VERSION ""

NS_ :

BS_:

BU_: VCU FCM

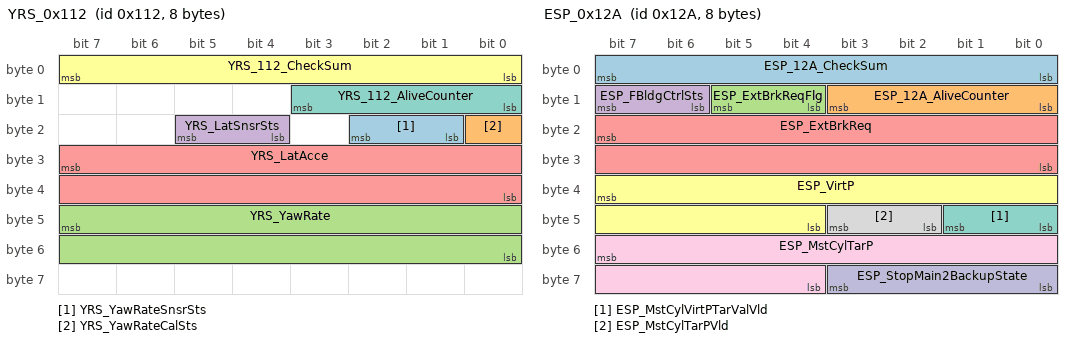
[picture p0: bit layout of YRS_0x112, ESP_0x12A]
BO_ 274 YRS_0x112: 8 VCU
 SG_ YRS_YawRateSnsrSts : 18|2@0+ (1,0) [0|3] ""  FCM
 SG_ YRS_YawRateCalSts : 16|1@0+ (1,0) [0|1] ""  FCM
 SG_ YRS_YawRate : 47|16@0+ (0.01,-180) [-180|180] "deg/s"  FCM
 SG_ YRS_LatSnsrSts : 21|2@0+ (1,0) [0|3] ""  FCM
 SG_ YRS_LatAcce : 31|16@0+ (0.001,-2) [-2|2] "g"  FCM
 SG_ YRS_112_CheckSum : 7|8@0+ (1,0) [0|255] ""  FCM
 SG_ YRS_112_AliveCounter : 11|4@0+ (1,0) [0|14] ""  FCM

BO_ 298 ESP_0x12A: 8 VCU
 SG_ ESP_12A_CheckSum : 7|8@0+ (1,0) [0|255] ""  FCM
 SG_ ESP_12A_AliveCounter : 11|4@0+ (1,0) [0|14] ""  FCM
 SG_ ESP_ExtBrkReqFlg : 13|2@0+ (1,0) [0|3] ""  FCM
 SG_ ESP_FBldgCtrlSts : 15|2@0+ (1,0) [0|3] ""  FCM
 SG_ ESP_ExtBrkReq : 23|16@0+ (0.0078125,-252) [-252|252] "ml/s"  FCM
 SG_ ESP_VirtP : 39|12@0+ (0.25,0) [0|250] "bar"  FCM
 SG_ ESP_MstCylVirtPTarValVld : 41|2@0+ (1,0) [0|3] ""  FCM
 SG_ ESP_MstCylTarPVld : 43|2@0+ (1,0) [0|3] ""  FCM
 SG_ ESP_MstCylTarP : 55|12@0+ (0.25,0) [0|250] "bar"  FCM
 SG_ ESP_StopMain2BackupState : 59|4@0+ (1,0) [0|15] ""  FCM

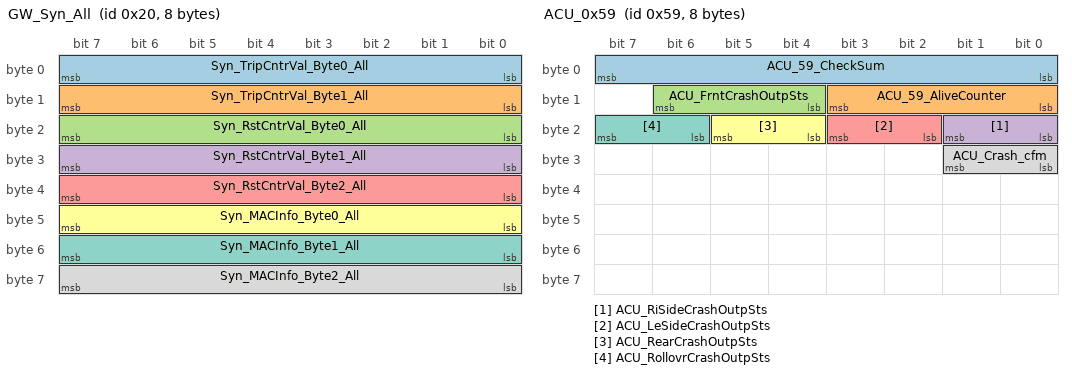
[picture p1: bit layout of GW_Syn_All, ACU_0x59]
BO_ 32 GW_Syn_All: 8 VCU
 SG_ Syn_TripCntrVal_Byte0_All : 7|8@0+ (1,0) [0|255] ""  FCM
 SG_ Syn_TripCntrVal_Byte1_All : 15|8@0+ (1,0) [0|255] ""  FCM
 SG_ Syn_RstCntrVal_Byte0_All : 23|8@0+ (1,0) [0|255] ""  FCM
 SG_ Syn_RstCntrVal_Byte1_All : 31|8@0+ (1,0) [0|255] ""  FCM
 SG_ Syn_RstCntrVal_Byte2_All : 39|8@0+ (1,0) [0|255] ""  FCM
 SG_ Syn_MACInfo_Byte0_All : 47|8@0+ (1,0) [0|255] ""  FCM
 SG_ Syn_MACInfo_Byte1_All : 55|8@0+ (1,0) [0|255] ""  FCM
 SG_ Syn_MACInfo_Byte2_All : 63|8@0+ (1,0) [0|255] ""  FCM

BO_ 89 ACU_0x59: 8 VCU
 SG_ ACU_59_CheckSum : 7|8@0+ (1,0) [0|255] ""  FCM
 SG_ ACU_59_AliveCounter : 11|4@0+ (1,0) [0|14] ""  FCM
 SG_ ACU_FrntCrashOutpSts : 14|3@0+ (1,0) [0|7] "" Vector__XXX
 SG_ ACU_RiSideCrashOutpSts : 17|2@0+ (1,0) [0|3] "" Vector__XXX
 SG_ ACU_LeSideCrashOutpSts : 19|2@0+ (1,0) [0|3] "" Vector__XXX
 SG_ ACU_RearCrashOutpSts : 21|2@0+ (1,0) [0|3] "" Vector__XXX
 SG_ ACU_RollovrCrashOutpSts : 23|2@0+ (1,0) [0|3] "" Vector__XXX
 SG_ ACU_Crash_cfm : 25|2@0+ (1,0) [0|3] ""  FCM

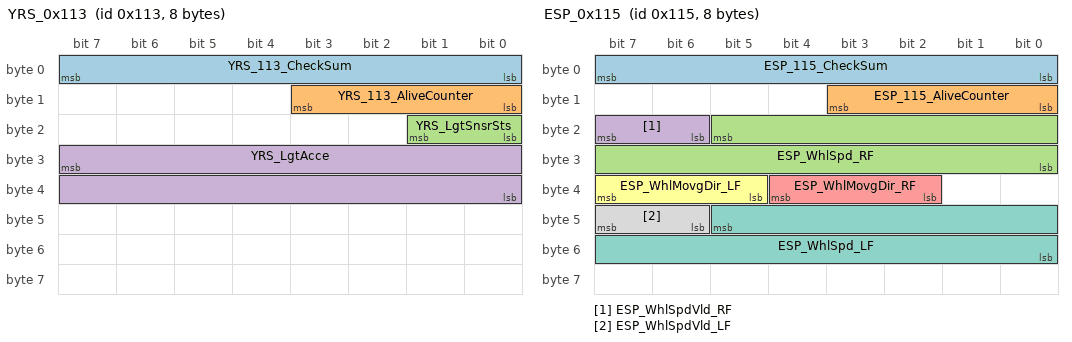
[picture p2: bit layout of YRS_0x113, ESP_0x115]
BO_ 275 YRS_0x113: 8 VCU
 SG_ YRS_113_CheckSum : 7|8@0+ (1,0) [0|255] ""  FCM
 SG_ YRS_113_AliveCounter : 11|4@0+ (1,0) [0|14] ""  FCM
 SG_ YRS_LgtSnsrSts : 17|2@0+ (1,0) [0|3] ""  FCM
 SG_ YRS_LgtAcce : 31|16@0+ (0.001,-2) [-2|2] "g"  FCM

BO_ 276 ESP_0x114: 8 VCU
 SG_ ESP_114_CheckSum : 7|8@0+ (1,0) [0|255] ""  FCM
 SG_ ESP_114_AliveCounter : 11|4@0+ (1,0) [0|14] ""  FCM
 SG_ ESP_OTARdy_Fb : 13|2@0+ (1,0) [0|3] "" Vector__XXX
 SG_ ESP_FltIndcn_DTC : 15|1@0+ (1,0) [0|1] "" Vector__XXX
 SG_ ESP_ActvSig_VDC : 16|1@0+ (1,0) [0|1] ""  FCM
 SG_ ESP_ActvSig_TCS : 17|1@0+ (1,0) [0|1] "" Vector__XXX
 SG_ ESP_ActvSig_EBD : 19|1@0+ (1,0) [0|1] "" Vector__XXX
 SG_ ESP_ActvSig_DTC : 20|1@0+ (1,0) [0|1] "" Vector__XXX
 SG_ ESP_WarningOn : 22|2@0+ (1,0) [0|3] "" Vector__XXX
 SG_ ESP_Actvndcn_CDD : 24|1@0+ (1,0) [0|1] "" Vector__XXX
 SG_ ESP_FltIndcn_CDD : 25|1@0+ (1,0) [0|1] "" Vector__XXX
 SG_ ESP_ActvIndcn_ABA : 26|1@0+ (1,0) [0|1] "" Vector__XXX
 SG_ ESP_FltIndcn_ABA : 27|1@0+ (1,0) [0|1] "" Vector__XXX
 SG_ ESP_ActvIndcn_ABP : 28|1@0+ (1,0) [0|1] "" Vector__XXX
 SG_ ESP_FltIndcn_ABP : 29|1@0+ (1,0) [0|1] "" Vector__XXX
 SG_ ESP_ActvIndcn_AEB : 30|1@0+ (1,0) [0|1] ""  FCM
 SG_ ESP_FltIndcn_AEB : 31|1@0+ (1,0) [0|1] ""  FCM
 SG_ ESP_ActvIndcn_AWB : 32|1@0+ (1,0) [0|1] "" Vector__XXX
 SG_ ESP_FltIndcn_AWB : 33|1@0+ (1,0) [0|1] "" Vector__XXX
 SG_ ESP_VehStandstillIndcn : 35|2@0+ (1,0) [0|3] ""  FCM
 SG_ ESP_BrkOverTIndcn : 36|1@0+ (1,0) [0|1] "" Vector__XXX
 SG_ ESP_FltIndcn_VDC : 37|1@0+ (1,0) [0|1] "" Vector__XXX
 SG_ ESP_ActvIndcn_CDD_AP : 42|1@0+ (1,0) [0|1] "" Vector__XXX
 SG_ ESP_FltIndcn_CDD_AP : 43|1@0+ (1,0) [0|1] "" Vector__XXX

BO_ 277 ESP_0x115: 8 VCU
 SG_ ESP_115_CheckSum : 7|8@0+ (1,0) [0|255] ""  FCM
 SG_ ESP_115_AliveCounter : 11|4@0+ (1,0) [0|14] ""  FCM
 SG_ ESP_WhlSpd_RF : 21|14@0+ (0.0625,0) [0|300] "km/h"  FCM
 SG_ ESP_WhlSpdVld_RF : 23|2@0+ (1,0) [0|3] ""  FCM
 SG_ ESP_WhlMovgDir_RF : 36|3@0+ (1,0) [0|7] ""  FCM
 SG_ ESP_WhlMovgDir_LF : 39|3@0+ (1,0) [0|7] ""  FCM
 SG_ ESP_WhlSpd_LF : 45|14@0+ (0.0625,0) [0|300] "km/h"  FCM
 SG_ ESP_WhlSpdVld_LF : 47|2@0+ (1,0) [0|3] ""  FCM

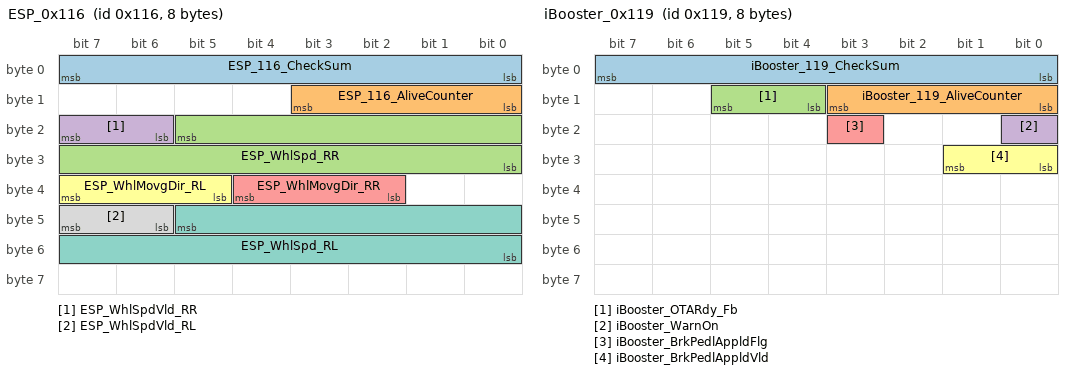
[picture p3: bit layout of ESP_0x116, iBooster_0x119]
BO_ 278 ESP_0x116: 8 VCU
 SG_ ESP_116_CheckSum : 7|8@0+ (1,0) [0|255] ""  FCM
 SG_ ESP_116_AliveCounter : 11|4@0+ (1,0) [0|14] ""  FCM
 SG_ ESP_WhlSpd_RR : 21|14@0+ (0.0625,0) [0|300] "km/h"  FCM
 SG_ ESP_WhlSpdVld_RR : 23|2@0+ (1,0) [0|3] ""  FCM
 SG_ ESP_WhlMovgDir_RR : 36|3@0+ (1,0) [0|7] ""  FCM
 SG_ ESP_WhlMovgDir_RL : 39|3@0+ (1,0) [0|7] ""  FCM
 SG_ ESP_WhlSpd_RL : 45|14@0+ (0.0625,0) [0|300] "km/h"  FCM
 SG_ ESP_WhlSpdVld_RL : 47|2@0+ (1,0) [0|3] ""  FCM

BO_ 281 iBooster_0x119: 8 VCU
 SG_ iBooster_119_CheckSum : 7|8@0+ (1,0) [0|255] ""  FCM
 SG_ iBooster_119_AliveCounter : 11|4@0+ (1,0) [0|14] ""  FCM
 SG_ iBooster_OTARdy_Fb : 13|2@0+ (1,0) [0|3] "" Vector__XXX
 SG_ iBooster_WarnOn : 16|1@0+ (1,0) [0|1] "" Vector__XXX
 SG_ iBooster_BrkPedlAppldFlg : 19|1@0+ (1,0) [0|1] ""  FCM
 SG_ iBooster_BrkPedlAppldVld : 25|2@0+ (1,0) [0|3] ""  FCM

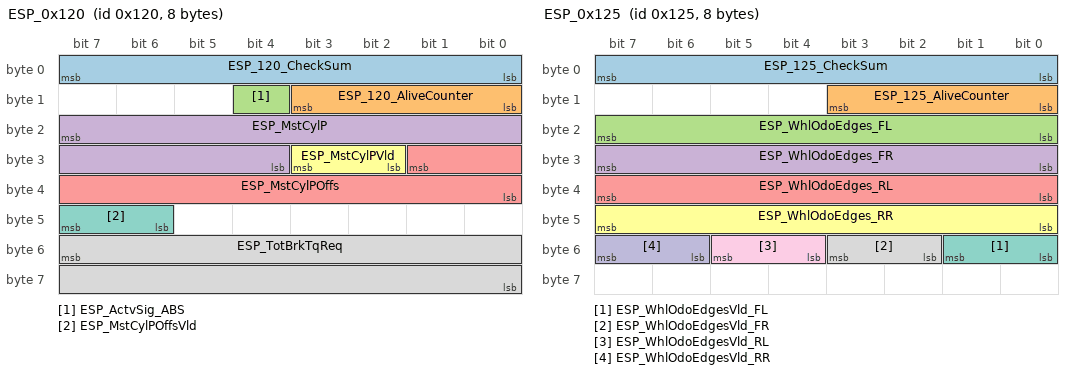
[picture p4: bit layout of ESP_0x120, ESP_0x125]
BO_ 288 ESP_0x120: 8 VCU
 SG_ ESP_120_CheckSum : 7|8@0+ (1,0) [0|255] ""  FCM
 SG_ ESP_120_AliveCounter : 11|4@0+ (1,0) [0|14] ""  FCM
 SG_ ESP_ActvSig_ABS : 12|1@0+ (1,0) [0|1] ""  FCM
 SG_ ESP_MstCylP : 23|12@0+ (0.1,-30) [-30|276.6] "bar"  FCM
 SG_ ESP_MstCylPOffs : 25|10@0+ (0.1,-15) [-15|15] "bar"  FCM
 SG_ ESP_MstCylPVld : 27|2@0+ (1,0) [0|3] ""  FCM
 SG_ ESP_MstCylPOffsVld : 47|2@0+ (1,0) [0|3] ""  FCM
 SG_ ESP_TotBrkTqReq : 55|16@0+ (1,-30000) [-30000|30000] "Nm" Vector__XXX

BO_ 293 ESP_0x125: 8 VCU
 SG_ ESP_125_CheckSum : 7|8@0+ (1,0) [0|255] ""  FCM
 SG_ ESP_125_AliveCounter : 11|4@0+ (1,0) [0|14] ""  FCM
 SG_ ESP_WhlOdoEdges_FL : 23|8@0+ (1,0) [0|255] "pulses"  FCM
 SG_ ESP_WhlOdoEdges_FR : 31|8@0+ (1,0) [0|255] "pulses"  FCM
 SG_ ESP_WhlOdoEdges_RL : 39|8@0+ (1,0) [0|255] "pulses"  FCM
 SG_ ESP_WhlOdoEdges_RR : 47|8@0+ (1,0) [0|255] "pulses"  FCM
 SG_ ESP_WhlOdoEdgesVld_FL : 49|2@0+ (1,0) [0|3] ""  FCM
 SG_ ESP_WhlOdoEdgesVld_FR : 51|2@0+ (1,0) [0|3] ""  FCM
 SG_ ESP_WhlOdoEdgesVld_RL : 53|2@0+ (1,0) [0|3] ""  FCM
 SG_ ESP_WhlOdoEdgesVld_RR : 55|2@0+ (1,0) [0|3] ""  FCM

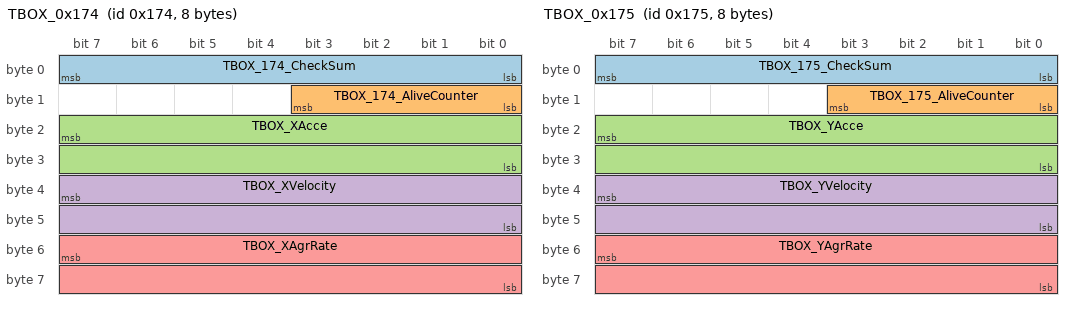
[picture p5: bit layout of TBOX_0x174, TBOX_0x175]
BO_ 372 TBOX_0x174: 8 VCU
 SG_ TBOX_174_CheckSum : 7|8@0+ (1,0) [0|255] ""  FCM
 SG_ TBOX_174_AliveCounter : 11|4@0+ (1,0) [0|14] ""  FCM
 SG_ TBOX_XAcce : 23|16@0- (0.01,0) [-327|327] "m/s2"  FCM
 SG_ TBOX_XVelocity : 39|16@0- (1,0) [-32768|32767] "cm/s"  FCM
 SG_ TBOX_XAgrRate : 55|16@0- (0.01,0) [-327|327] "deg/s"  FCM

BO_ 373 TBOX_0x175: 8 VCU
 SG_ TBOX_175_CheckSum : 7|8@0+ (1,0) [0|255] ""  FCM
 SG_ TBOX_175_AliveCounter : 11|4@0+ (1,0) [0|14] ""  FCM
 SG_ TBOX_YAcce : 23|16@0- (0.01,0) [-327|327] "m/s2"  FCM
 SG_ TBOX_YVelocity : 39|16@0- (1,0) [-32768|32767] "cm/s"  FCM
 SG_ TBOX_YAgrRate : 55|16@0- (0.01,0) [-327|327] "deg/s"  FCM

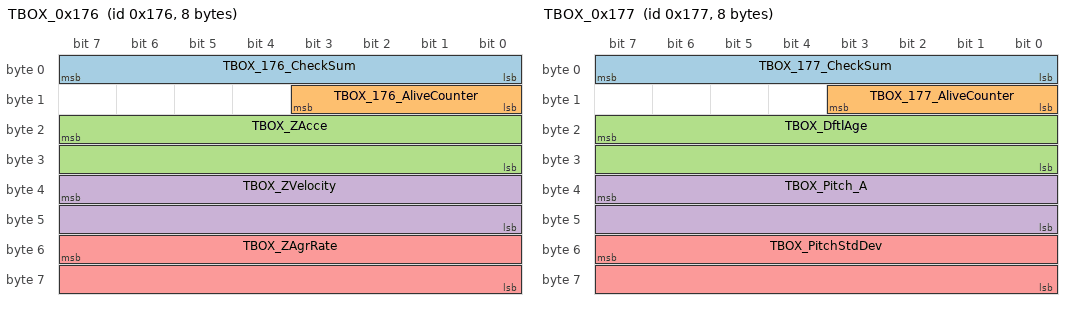
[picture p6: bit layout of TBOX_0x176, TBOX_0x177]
BO_ 374 TBOX_0x176: 8 VCU
 SG_ TBOX_176_CheckSum : 7|8@0+ (1,0) [0|255] ""  FCM
 SG_ TBOX_176_AliveCounter : 11|4@0+ (1,0) [0|14] ""  FCM
 SG_ TBOX_ZAcce : 23|16@0- (0.01,0) [-327|327] "m/s2"  FCM
 SG_ TBOX_ZVelocity : 39|16@0- (1,0) [-32768|32767] "cm/s"  FCM
 SG_ TBOX_ZAgrRate : 55|16@0- (0.01,0) [-327|327] "deg/s"  FCM

BO_ 375 TBOX_0x177: 8 VCU
 SG_ TBOX_177_CheckSum : 7|8@0+ (1,0) [0|255] ""  FCM
 SG_ TBOX_177_AliveCounter : 11|4@0+ (1,0) [0|14] ""  FCM
 SG_ TBOX_DftlAge : 23|16@0+ (1,0) [0|65000] "s"  FCM
 SG_ TBOX_Pitch_A : 39|16@0+ (0.01,-180) [-180|180] "deg"  FCM
 SG_ TBOX_PitchStdDev : 55|16@0+ (0.01,0) [0|179.9] "deg"  FCM

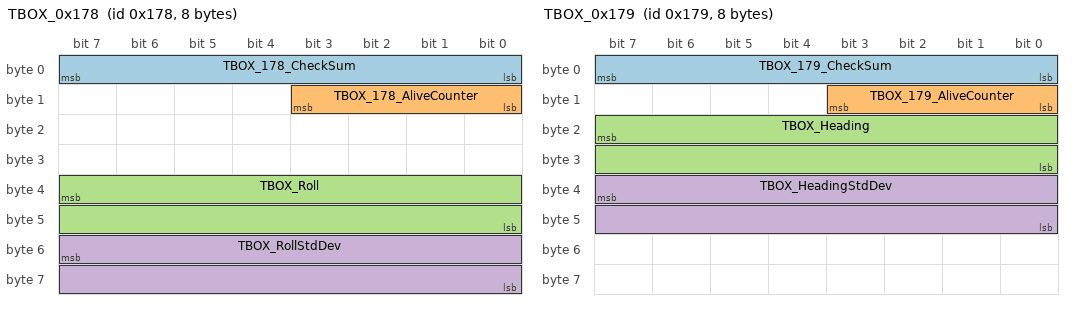
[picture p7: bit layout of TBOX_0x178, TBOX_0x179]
BO_ 376 TBOX_0x178: 8 VCU
 SG_ TBOX_178_CheckSum : 7|8@0+ (1,0) [0|255] ""  FCM
 SG_ TBOX_178_AliveCounter : 11|4@0+ (1,0) [0|14] ""  FCM
 SG_ TBOX_Roll : 39|16@0+ (0.01,-180) [-180|180] "deg"  FCM
 SG_ TBOX_RollStdDev : 55|16@0+ (0.01,0) [0|179.9] "deg"  FCM

BO_ 377 TBOX_0x179: 8 VCU
 SG_ TBOX_179_CheckSum : 7|8@0+ (1,0) [0|255] ""  FCM
 SG_ TBOX_179_AliveCounter : 11|4@0+ (1,0) [0|14] ""  FCM
 SG_ TBOX_Heading : 23|16@0+ (0.01,0) [0|359.9] "deg"  FCM
 SG_ TBOX_HeadingStdDev : 39|16@0+ (0.01,0) [0|179.9] "deg"  FCM

BO_ 440 ESP_0x1B8: 8 VCU
 SG_ ESP_1B8_CheckSum : 7|8@0+ (1,0) [0|255] ""  FCM
 SG_ ESP_1B8_AliveCounter : 11|4@0+ (1,0) [0|14] ""  FCM
 SG_ ESP_ModFbSig : 14|3@0+ (1,0) [0|7] "" Vector__XXX
 SG_ ESP_ModSwtAllw : 15|1@0+ (1,0) [0|1] "" Vector__XXX
 SG_ ESP_ActvVehHldFlg : 16|1@0+ (1,0) [0|1] "" Vector__XXX
 SG_ ESP_VehSecuCdn : 19|3@0+ (1,0) [0|7] "" Vector__XXX
 SG_ ESP_BrkFStsFlg : 20|1@0+ (1,0) [0|1] "" Vector__XXX
 SG_ ESP_CddApOpsDirMovmt : 24|1@0+ (1,0) [0|1] "" Vector__XXX
 SG_ ESP_VehStopSts : 32|1@0+ (1,0) [0|1] ""  FCM
 SG_ ESP_VehStandstillSts : 33|1@0+ (1,0) [0|1] ""  FCM
 SG_ ESP_EPB_BenchMode : 35|2@0+ (1,0) [0|3] "" Vector__XXX
 SG_ ESP_RoadSlopVld : 37|2@0+ (1,0) [0|3] "" Vector__XXX
 SG_ ESP_AEBRdy : 41|2@0+ (1,0) [0|3] "" Vector__XXX
 SG_ ESPACCRdy : 43|2@0+ (1,0) [0|3] "" Vector__XXX
 SG_ ESP_ParkRdy : 45|2@0+ (1,0) [0|3] "" Vector__XXX
 SG_ ESP_ReAEBRdy : 47|2@0+ (1,0) [0|3] "" Vector__XXX
 SG_ ESP_RoadSlop : 50|11@0+ (0.01,-10) [-10|10] "m/s2" Vector__XXX
 SG_ ESP_SpclTerrainModFltIndcn : 51|1@0+ (1,0) [0|1] "" Vector__XXX
 SG_ ESP_DrvOffStRdy : 52|1@0+ (1,0) [0|1] "" Vector__XXX
 SG_ ESP_TarLSMSts : 55|1@0+ (1,0) [0|1] "" Vector__XXX

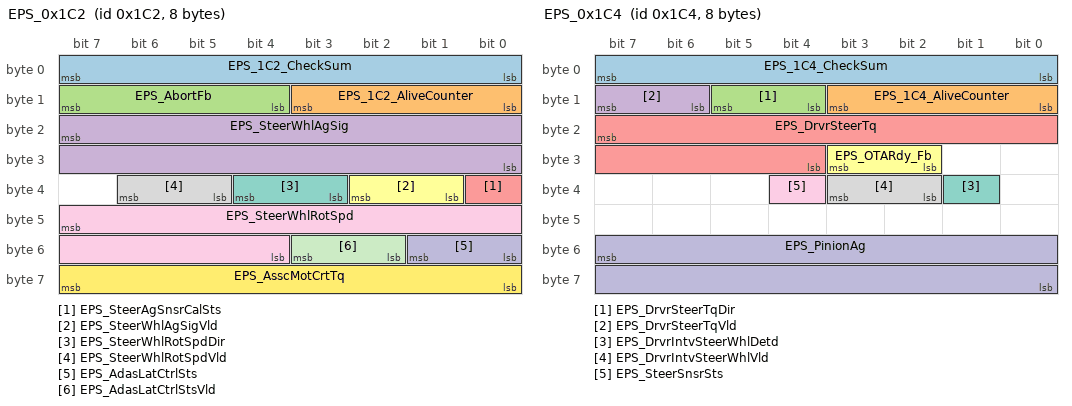
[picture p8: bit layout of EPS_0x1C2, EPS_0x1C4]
BO_ 450 EPS_0x1C2: 8 VCU
 SG_ EPS_1C2_CheckSum : 7|8@0+ (1,0) [0|255] ""  FCM
 SG_ EPS_1C2_AliveCounter : 11|4@0+ (1,0) [0|14] ""  FCM
 SG_ EPS_AbortFb : 15|4@0+ (1,0) [0|15] "" Vector__XXX
 SG_ EPS_SteerWhlAgSig : 23|16@0+ (0.0625,-780) [-780|780] "deg"  FCM
 SG_ EPS_SteerAgSnsrCalSts : 32|1@0+ (1,0) [0|1] ""  FCM
 SG_ EPS_SteerWhlAgSigVld : 34|2@0+ (1,0) [0|3] ""  FCM
 SG_ EPS_SteerWhlRotSpdDir : 36|2@0+ (1,0) [0|3] "" Vector__XXX
 SG_ EPS_SteerWhlRotSpdVld : 38|2@0+ (1,0) [0|3] ""  FCM
 SG_ EPS_SteerWhlRotSpd : 47|12@0+ (0.5,-1016) [-1016|1016] "deg/s"  FCM
 SG_ EPS_AdasLatCtrlSts : 49|2@0+ (1,0) [0|3] "" Vector__XXX
 SG_ EPS_AdasLatCtrlStsVld : 51|2@0+ (1,0) [0|3] "" Vector__XXX
 SG_ EPS_AsscMotCrtTq : 63|8@0+ (0.1,0) [0|10] "Nm" Vector__XXX

BO_ 452 EPS_0x1C4: 8 VCU
 SG_ EPS_1C4_CheckSum : 7|8@0+ (1,0) [0|255] ""  FCM
 SG_ EPS_1C4_AliveCounter : 11|4@0+ (1,0) [0|14] ""  FCM
 SG_ EPS_DrvrSteerTqDir : 13|2@0+ (1,0) [0|3] "" Vector__XXX
 SG_ EPS_DrvrSteerTqVld : 15|2@0+ (1,0) [0|3] "" Vector__XXX
 SG_ EPS_DrvrSteerTq : 23|12@0+ (0.01,0) [0|8] "Nm" Vector__XXX
 SG_ EPS_OTARdy_Fb : 27|2@0+ (1,0) [0|3] "" Vector__XXX
 SG_ EPS_DrvrIntvSteerWhlDetd : 33|1@0+ (1,0) [0|1] "" Vector__XXX
 SG_ EPS_DrvrIntvSteerWhlVld : 35|2@0+ (1,0) [0|3] "" Vector__XXX
 SG_ EPS_SteerSnsrSts : 36|1@0+ (1,0) [0|1] ""  FCM
 SG_ EPS_PinionAg : 55|16@0+ (0.0625,-780) [-780|780] "deg" Vector__XXX

BO_ 532 VCU_0x214: 16 VCU
 SG_ VCU_214_234_CheckSum : 7|8@0+ (1,0) [0|255] ""  FCM
 SG_ VCU_214_234_AliveCounter : 11|4@0+ (1,0) [0|14] ""  FCM
 SG_ VCU_RdyLamp : 12|1@0+ (1,0) [0|1] "" Vector__XXX
 SG_ VCU_BrkLampCtrlSts : 14|1@0+ (1,0) [0|1] "" Vector__XXX
 SG_ VCU_RemWakeUpEndFlg : 15|1@0+ (1,0) [0|1] "" Vector__XXX
 SG_ VCU_StgyGearSig : 19|4@0+ (1,0) [0|15] "" Vector__XXX
 SG_ VCU_ShiftMisoper : 21|1@0+ (1,0) [0|1] "" Vector__XXX
 SG_ VCU_GearSigVld : 23|2@0+ (1,0) [0|3] ""  FCM
 SG_ VCU_GearSig : 27|4@0+ (1,0) [0|15] ""  FCM
 SG_ VCU_ACCRdy : 28|1@0+ (1,0) [0|1] "" Vector__XXX
 SG_ VCU_ParkRdy : 29|1@0+ (1,0) [0|1] "" Vector__XXX
 SG_ VCU_APSPercVld : 31|2@0+ (1,0) [0|3] ""  FCM
 SG_ VCU_VehSt : 39|16@0+ (1,0) [0|65535] "" Vector__XXX
 SG_ VCU_APSPerc : 55|8@0+ (0.4,0) [0|100] "%"  FCM
 SG_ VCU_BrkSig : 56|1@0+ (1,0) [0|1] ""  FCM
 SG_ VCU_BrkSigVld : 58|2@0+ (1,0) [0|3] ""  FCM
 SG_ VCU_DrvModSigFb : 61|3@0+ (1,0) [0|7] "" Vector__XXX
 SG_ VCU_DrvModShiftMisoper : 62|1@0+ (1,0) [0|1] "" Vector__XXX
 SG_ VCU_SpclTerrainModEnaSig : 63|1@0+ (1,0) [0|1] "" Vector__XXX
 SG_ VCU_214_SSecOC_Fresh_Byte0 : 71|8@0+ (1,0) [0|255] "" Vector__XXX
 SG_ VCU_214_SSecOC_MAC_Byte0 : 79|8@0+ (1,0) [0|255] "" Vector__XXX
 SG_ VCU_214_SSecOC_MAC_Byte1 : 87|8@0+ (1,0) [0|255] "" Vector__XXX
 SG_ VCU_214_SSecOC_MAC_Byte2 : 95|8@0+ (1,0) [0|255] "" Vector__XXX

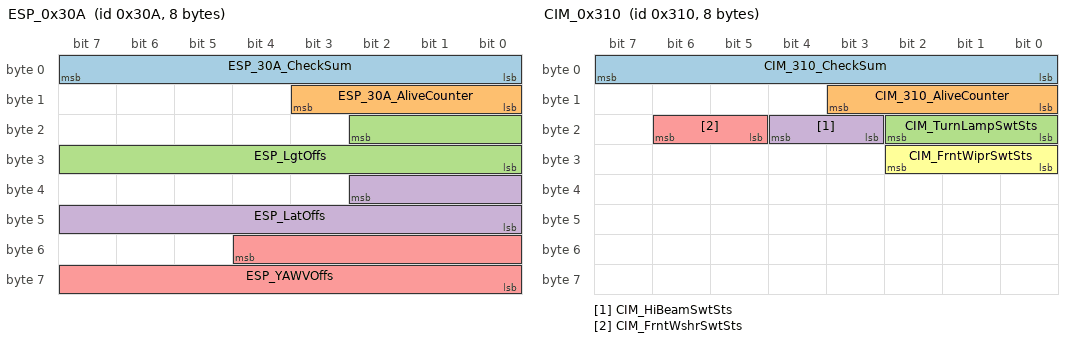
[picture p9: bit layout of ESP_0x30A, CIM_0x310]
BO_ 778 ESP_0x30A: 8 VCU
 SG_ ESP_30A_CheckSum : 7|8@0+ (1,0) [0|255] ""  FCM
 SG_ ESP_30A_AliveCounter : 11|4@0+ (1,0) [0|14] ""  FCM
 SG_ ESP_LgtOffs : 18|11@0+ (0.0027127,-2.15928) [-2.15928|2.15928] "g"  FCM
 SG_ ESP_LatOffs : 34|11@0+ (0.0027127,-2.15928) [-2.15928|2.15928] "g"  FCM
 SG_ ESP_YAWVOffs : 52|13@0+ (0.056,-120) [-120|120] "deg/s"  FCM

BO_ 784 CIM_0x310: 8 VCU
 SG_ CIM_310_CheckSum : 7|8@0+ (1,0) [0|255] ""  FCM
 SG_ CIM_310_AliveCounter : 11|4@0+ (1,0) [0|14] ""  FCM
 SG_ CIM_TurnLampSwtSts : 18|3@0+ (1,0) [0|7] ""  FCM
 SG_ CIM_HiBeamSwtSts : 20|2@0+ (1,0) [0|3] ""  FCM
 SG_ CIM_FrntWshrSwtSts : 22|2@0+ (1,0) [0|3] ""  FCM
 SG_ CIM_FrntWiprSwtSts : 26|3@0+ (1,0) [0|7] ""  FCM

BO_ 792 ESP_0x318: 8 VCU
 SG_ ESP_318_CheckSum : 7|8@0+ (1,0) [0|255] ""  FCM
 SG_ ESP_318_AliveCounter : 11|4@0+ (1,0) [0|14] ""  FCM
 SG_ ESP_BrkPedlStsVld : 13|2@0+ (1,0) [0|3] ""  FCM
 SG_ ESP_BrkPedlSts : 14|1@0+ (1,0) [0|1] ""  FCM
 SG_ ESP_VehSpdVld : 17|2@0+ (1,0) [0|3] ""  FCM
 SG_ ESP_SysActv : 20|1@0+ (1,0) [0|1] "" Vector__XXX
 SG_ ESP_LampSwtOffIndcn : 21|1@0+ (1,0) [0|1] "" Vector__XXX
 SG_ ESP_FltIndcn_EBD : 22|1@0+ (1,0) [0|1] "" Vector__XXX
 SG_ ESP_FltIndcn_ABS : 23|1@0+ (1,0) [0|1] ""  FCM
 SG_ ESP_MilgRollgCntr_ODO : 31|16@0+ (1,0) [0|65535] "pulses" Vector__XXX
 SG_ ESP_VehSpd : 47|16@0+ (0.1,0) [0|300] "km/h"  FCM
 SG_ ESP_IninModSigIndcn : 56|1@0+ (1,0) [0|1] "" Vector__XXX
 SG_ ESP_FltIndcn_TCS : 57|1@0+ (1,0) [0|1] ""  FCM
 SG_ ESP_CtrlSts_HDC : 59|2@0+ (1,0) [0|3] "" Vector__XXX
 SG_ ESP_AvlIndcn_HDC : 60|1@0+ (1,0) [0|1] "" Vector__XXX
 SG_ ESP_NoBrkP : 61|1@0+ (1,0) [0|1] "" Vector__XXX
 SG_ ESP_RDAEnaFlg : 62|1@0+ (1,0) [0|1] "" Vector__XXX

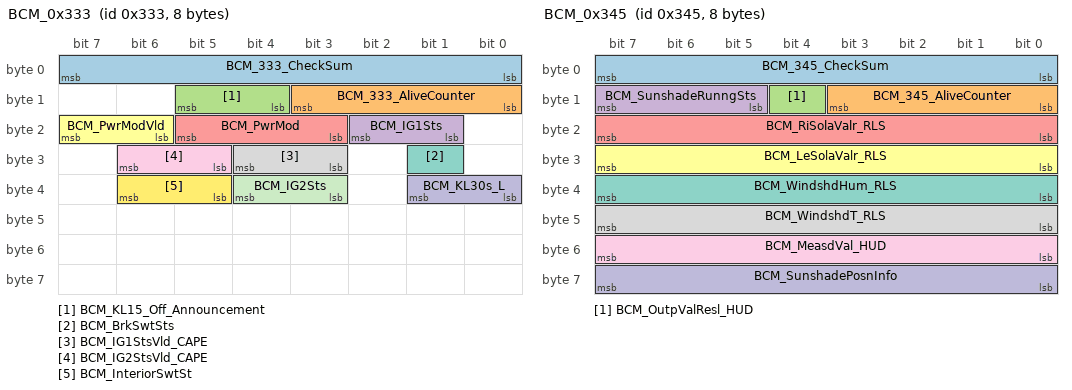
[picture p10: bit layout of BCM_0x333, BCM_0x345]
BO_ 819 BCM_0x333: 8 VCU
 SG_ BCM_333_CheckSum : 7|8@0+ (1,0) [0|255] ""  FCM
 SG_ BCM_333_AliveCounter : 11|4@0+ (1,0) [0|14] ""  FCM
 SG_ BCM_KL15_Off_Announcement : 13|2@0+ (1,0) [0|3] "" Vector__XXX
 SG_ BCM_IG1Sts : 18|2@0+ (1,0) [0|3] ""  FCM
 SG_ BCM_PwrMod : 21|3@0+ (1,0) [0|7] ""  FCM
 SG_ BCM_PwrModVld : 23|2@0+ (1,0) [0|3] ""  FCM
 SG_ BCM_BrkSwtSts : 25|1@0+ (1,0) [0|1] "" Vector__XXX
 SG_ BCM_IG1StsVld_CAPE : 28|2@0+ (1,0) [0|3] "" Vector__XXX
 SG_ BCM_IG2StsVld_CAPE : 30|2@0+ (1,0) [0|3] "" Vector__XXX
 SG_ BCM_KL30s_L : 33|2@0+ (1,0) [0|3] "" Vector__XXX
 SG_ BCM_IG2Sts : 36|2@0+ (1,0) [0|3] "" Vector__XXX
 SG_ BCM_InteriorSwtSt : 38|2@0+ (1,0) [0|3] "" Vector__XXX

BO_ 821 BCM_0x335: 8 VCU
 SG_ BCM_335_CheckSum : 7|8@0+ (1,0) [0|255] ""  FCM
 SG_ BCM_335_AliveCounter : 11|4@0+ (1,0) [0|14] ""  FCM
 SG_ BCM_WiprInSrvPosn : 12|1@0+ (1,0) [0|1] "" Vector__XXX
 SG_ BCM_IntLampTiSetSts : 15|3@0+ (1,0) [0|7] "" Vector__XXX
 SG_ BCM_WaterPosnSnsrSwtSts : 16|1@0+ (1,0) [0|1] "" Vector__XXX
 SG_ BCM_FrntFogLampOutpCmd : 17|1@0+ (1,0) [0|1] "" Vector__XXX
 SG_ BCM_LicPlateLampOutpCmd : 18|1@0+ (1,0) [0|1] "" Vector__XXX
 SG_ BCM_EnaSts_ADB : 19|1@0+ (1,0) [0|1] "" Vector__XXX
 SG_ BCM_PwrSaveOutpCmd : 20|1@0+ (1,0) [0|1] "" Vector__XXX
 SG_ BCM_ExtLampSwtSts : 23|3@0+ (1,0) [0|7] ""  FCM
 SG_ BCM_HornOutpCmd : 24|1@0+ (1,0) [0|1] "" Vector__XXX
 SG_ BCM_HornSwtSts : 25|1@0+ (1,0) [0|1] "" Vector__XXX
 SG_ BCM_WelLampOutpCmd : 26|1@0+ (1,0) [0|1] "" Vector__XXX
 SG_ BCM_FolwMeHomeSts : 27|1@0+ (1,0) [0|1] "" Vector__XXX
 SG_ BCM_FrntFogLampSwtSts : 28|1@0+ (1,0) [0|1] "" Vector__XXX
 SG_ BCM_ReFogLampSwtSts : 29|1@0+ (1,0) [0|1] ""  FCM
 SG_ BCM_ReWiprBackSwtSts : 30|1@0+ (1,0) [0|1] "" Vector__XXX
 SG_ BCM_RainClsSunroofSetSts : 31|1@0+ (1,0) [0|0] "" Vector__XXX
 SG_ BCM_MirrLockAutoSetSts : 32|1@0+ (1,0) [0|1] "" Vector__XXX
 SG_ BCM_FrntWshrOutpCmd : 33|1@0+ (1,0) [0|1] "" Vector__XXX
 SG_ BCM_DangerAlrmLampSwtSts : 34|1@0+ (1,0) [0|1] "" Vector__XXX
 SG_ BCM_ReDefrstHeatgCmd : 35|1@0+ (1,0) [0|1] "" Vector__XXX
 SG_ BCM_RvsLampOutpCmd : 36|1@0+ (1,0) [0|1] "" Vector__XXX
 SG_ BCM_IntLampOutpCmd : 37|1@0+ (1,0) [0|1] "" Vector__XXX
 SG_ BCM_LeTrunLampOutpCmd : 38|1@0+ (1,0) [0|1] "" Vector__XXX
 SG_ BCM_RiTrunLampOutpCmd : 39|1@0+ (1,0) [0|1] "" Vector__XXX
 SG_ BCM_ReWiprOutpCmd : 40|1@0+ (1,0) [0|1] "" Vector__XXX
 SG_ BCM_ReWshrOutpCmd : 41|1@0+ (1,0) [0|1] "" Vector__XXX
 SG_ BCM_BrkLampSwtSts : 42|1@0+ (1,0) [0|1] "" Vector__XXX
 SG_ BCM_HiBeamOutpCmd : 43|1@0+ (1,0) [0|1] ""  FCM
 SG_ BCM_LoBeamOutpCmd : 44|1@0+ (1,0) [0|1] ""  FCM
 SG_ BCM_PosnLampOutpCmd : 46|2@0+ (1,0) [0|3] "" Vector__XXX
 SG_ BCM_BrkLampOutpCmd : 47|1@0+ (1,0) [0|1] "" Vector__XXX
 SG_ BCM_ReFogLampOutpCmd : 48|1@0+ (1,0) [0|1] "" Vector__XXX
 SG_ BCM_FrntWiprSpd : 54|6@0+ (1,0) [0|63] "time/m"  FCM
 SG_ BCM_EnaReq_ADB : 55|1@0+ (1,0) [0|1] "" Vector__XXX
 SG_ BCM_VehAmbBri : 63|8@0+ (100,0) [0|25400] "lx" Vector__XXX

BO_ 822 ICC_0x336: 8 VCU
 SG_ ICC_336_Checksum : 7|8@0+ (1,0) [0|255] ""  FCM
 SG_ ICC_336_AliveCounter : 11|4@0+ (1,0) [0|14] ""  FCM
 SG_ ICC_SetAtmLampBri : 15|4@0+ (1,0) [0|15] "" Vector__XXX
 SG_ ICC_SuspSet : 17|2@0+ (1,0) [0|3] "" Vector__XXX
 SG_ ICC_OTAInhbRdy : 19|2@0+ (1,0) [0|3] "" Vector__XXX
 SG_ ICC_AtmLampOpenCmd : 20|1@0+ (1,0) [0|1] "" Vector__XXX
 SG_ ICC_SteerAssiSet : 23|3@0+ (1,0) [0|7] "" Vector__XXX
 SG_ ICC_SetStorageBriLvl : 27|4@0+ (1,0) [0|15] "" Vector__XXX
 SG_ ICC_HDCSwtSig : 28|1@0+ (1,0) [0|1] "" Vector__XXX
 SG_ ICC_ESPSwtSig : 29|1@0+ (1,0) [0|1] "" Vector__XXX
 SG_ ICC_ReqCalifModHMIBtn : 31|2@0+ (1,0) [0|3] "" Vector__XXX
 SG_ ICC_SpdLimOffs : 35|4@0+ (1,0) [0|15] ""  FCM
 SG_ ICC_iTPMSResetSig : 37|2@0+ (1,0) [0|3] "" Vector__XXX
 SG_ ICC_WIFIOnOffSig : 39|2@0+ (1,0) [0|3] "" Vector__XXX
 SG_ ICC_LeMirrAlrmLampFlt : 41|2@0+ (1,0) [0|3] "" Vector__XXX
 SG_ ICC_RiMirrAlrmLampFlt : 43|2@0+ (1,0) [0|3] "" Vector__XXX
 SG_ ICC_PhoneSt : 45|2@0+ (1,0) [0|3] ""  FCM
 SG_ ICC_SpeechSt : 47|2@0+ (1,0) [0|3] ""  FCM
 SG_ ICC_RemReqFb : 49|2@0+ (1,0) [0|3] "" Vector__XXX
 SG_ ICC_SpdLimFdb : 51|2@0+ (1,0) [0|3] "" Vector__XXX
 SG_ ICC_OTARdy_Fb : 54|2@0+ (1,0) [0|3] "" Vector__XXX

BO_ 837 BCM_0x345: 8 VCU
 SG_ BCM_345_CheckSum : 7|8@0+ (1,0) [0|255] ""  FCM
 SG_ BCM_345_AliveCounter : 11|4@0+ (1,0) [0|14] ""  FCM
 SG_ BCM_OutpValResl_HUD : 12|1@0+ (1,0) [0|1] "" Vector__XXX
 SG_ BCM_SunshadeRunngSts : 15|3@0+ (1,0) [0|7] "" Vector__XXX
 SG_ BCM_RiSolaValr_RLS : 23|8@0+ (4.01575,0) [0|1024.01625] "W/m2"  FCM
 SG_ BCM_LeSolaValr_RLS : 31|8@0+ (4.01575,0) [0|1024.01625] "W/m2"  FCM
 SG_ BCM_WindshdHum_RLS : 39|8@0+ (0.5,0) [0|127.5] "%"  FCM
 SG_ BCM_WindshdT_RLS : 47|8@0+ (0.5,-40) [-40|87.5] "Degree Celsius"  FCM
 SG_ BCM_MeasdVal_HUD : 55|8@0+ (1,0) [0|255] "" Vector__XXX
 SG_ BCM_SunshadePosnInfo : 63|8@0+ (1,0) [0|100] "" Vector__XXX

BO_ 856 VCU_0x358: 8 VCU
 SG_ VCU_358_CheckSum : 7|8@0+ (1,0) [0|255] "" Vector__XXX
 SG_ VCU_358_AliveCounter : 11|4@0+ (1,0) [0|14] "" Vector__XXX
 SG_ VCU_KickdwnFlg : 13|2@0+ (1,0) [0|3] "" Vector__XXX
 SG_ VCU_EPedlEnaSig : 15|1@0+ (1,0) [0|1] "" Vector__XXX
 SG_ VCU_ComLostFlt_ESP : 16|1@0+ (1,0) [0|1] "" Vector__XXX
 SG_ VCU_ComFlt_iBooster : 17|1@0+ (1,0) [0|1] "" Vector__XXX
 SG_ VCU_RegenLvlFb : 19|2@0+ (1,0) [0|3] "" Vector__XXX
 SG_ VCU_AccelModFb : 21|2@0+ (1,0) [0|3] "" Vector__XXX
 SG_ VCU_EPedlStsFb : 23|2@0+ (1,0) [0|3] "" Vector__XXX
 SG_ VCU_CcTrgSpdDisp : 31|8@0+ (1,0) [0|255] "" Vector__XXX
 SG_ VCU_Sts_CC_ICC : 35|4@0+ (1,0) [0|15] "" Vector__XXX
 SG_ VCU_CCIconDisp : 38|3@0+ (1,0) [0|7] "" Vector__XXX
 SG_ VCU_DispSpdUnit_CC : 39|1@0+ (1,0) [0|1] "" Vector__XXX
 SG_ VCU_BoostEnStat : 43|4@0+ (1,0) [0|15] "" Vector__XXX
 SG_ VCU_OTARdy_Fb : 45|2@0+ (1,0) [0|3] "" Vector__XXX
 SG_ VCU_OTA_ECUInhb_Req : 47|2@0+ (1,0) [0|3] "" Vector__XXX
 SG_ VCU_OTAVehCdnChk_ASIL : 49|2@0+ (1,0) [0|3] ""  FCM
 SG_ VCU_OTAVehInhb_ASIL_Fb : 51|2@0+ (1,0) [0|3] ""  FCM

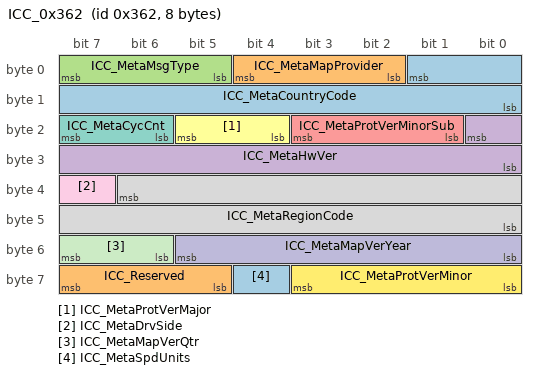
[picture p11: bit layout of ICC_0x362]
BO_ 866 ICC_0x362: 8 VCU
 SG_ ICC_MetaCountryCode : 1|10@0+ (1,0) [0|1023] ""  FCM
 SG_ ICC_MetaMapProvider : 4|3@0+ (1,0) [0|7] "m" Vector__XXX
 SG_ ICC_MetaMsgType : 7|3@0+ (1,0) [0|7] "" Vector__XXX
 SG_ ICC_MetaHwVer : 16|9@0+ (1,0) [0|511] "" Vector__XXX
 SG_ ICC_MetaProtVerMinorSub : 19|3@0+ (1,0) [0|7] "" Vector__XXX
 SG_ ICC_MetaProtVerMajor : 21|2@0+ (1,0) [0|3] "" Vector__XXX
 SG_ ICC_MetaCycCnt : 23|2@0+ (1,0) [0|3] "" Vector__XXX
 SG_ ICC_MetaRegionCode : 38|15@0+ (1,0) [0|32767] ""  FCM
 SG_ ICC_MetaDrvSide : 39|1@0+ (1,0) [0|1] "" Vector__XXX
 SG_ ICC_MetaMapVerYear : 53|6@0+ (1,2000) [2000|2063] "" Vector__XXX
 SG_ ICC_MetaMapVerQtr : 55|2@0+ (1,1) [1|3] "" Vector__XXX
 SG_ ICC_MetaProtVerMinor : 59|4@0+ (1,0) [0|15] "" Vector__XXX
 SG_ ICC_MetaSpdUnits : 60|1@0+ (1,0) [0|1] "" Vector__XXX
 SG_ ICC_Reserved : 63|3@0+ (1,0) [0|7] "" Vector__XXX

BO_ 883 ECC_0x373: 8 VCU
 SG_ ECC_CrtSts : 3|4@0+ (1,0) [0|15] "" Vector__XXX
 SG_ ECC_IninSts : 4|1@0+ (1,0) [0|1] "" Vector__XXX
 SG_ ECC_PwrSysHeatMngtSts : 6|2@0+ (1,0) [0|3] "" Vector__XXX
 SG_ ECC_ACSts : 7|1@0+ (1,0) [0|1] "" Vector__XXX
 SG_ ECC_AirClnSts : 8|1@0+ (1,0) [0|1] "" Vector__XXX
 SG_ ECC_WindSpdSts : 12|4@0+ (1,0) [0|15] ""  FCM
 SG_ ECC_BackRowAirOutlModSts : 15|3@0+ (1,0) [0|7] "" Vector__XXX
 SG_ ECC_DrvrTSetSts : 23|8@0+ (0.5,0) [0|127.5] "" Vector__XXX
 SG_ ECC_PassTSetSts : 31|8@0+ (0.5,0) [0|127.5] "" Vector__XXX
 SG_ ECC_HeatSts : 32|1@0+ (1,0) [0|1] "" Vector__XXX
 SG_ ECC_AUTOSts : 33|1@0+ (1,0) [0|1] "" Vector__XXX
 SG_ ECC_SYNCSts : 34|1@0+ (1,0) [0|1] "" Vector__XXX
 SG_ ECC_InfoSysWrmColdDisp : 36|2@0+ (1,0) [0|3] "" Vector__XXX
 SG_ ECC_CircSts : 37|1@0+ (1,0) [0|1] "" Vector__XXX
 SG_ ECC_ParticleConcVld : 39|2@0+ (1,0) [0|3] "" Vector__XXX
 SG_ ECC_OutdT : 47|8@0+ (0.5,-48) [-48|79.5] "Degree Celsius"  FCM
 SG_ ECC_OutdTVld : 49|2@0+ (1,0) [0|3] ""  FCM
 SG_ ECC_MaxFrntDefrst : 50|1@0+ (1,0) [0|1] "" Vector__XXX
 SG_ ECC_HeatMngtSysFlt : 51|1@0+ (1,0) [0|1] "" Vector__XXX
 SG_ ECC_HeatMngtFctLim : 52|1@0+ (1,0) [0|1] "" Vector__XXX
 SG_ ECC_DrvrAirOutlMod : 55|3@0+ (1,0) [0|7] "" Vector__XXX
 SG_ ECC_PassAirOutlMod : 58|3@0+ (1,0) [0|7] "" Vector__XXX
 SG_ ECC_RemSts : 60|2@0+ (1,0) [0|3] "" Vector__XXX
 SG_ ECC_OTAInhbRdy : 62|2@0+ (1,0) [0|3] "" Vector__XXX

CM_ SG_ 274 YRS_YawRateSnsrSts "Status of yaw rate sensor Indicates Yaw Rate Sensor State.";
CM_ SG_ 274 YRS_YawRateCalSts "Yaw rate sensor calibration state Indicates Yaw Rate Sensor Calibration State.";
CM_ SG_ 274 YRS_YawRate "Indicates the yaw rate (counterclockwise positive, clockwise negative, Real Value = raw value-offset)Indicates Yaw Rate.";
CM_ SG_ 274 YRS_LatSnsrSts "Status of lateral sensor Indicates Lateral Sensor State.";
CM_ SG_ 274 YRS_LatAcce "Lateral acceleration (left positive, right negative, Real Value = raw value-offset)Indicates Lateral Acceleration.";
CM_ SG_ 274 YRS_112_CheckSum "YRS_112_Message Checksum (E2E data ID: 0xA1)";
CM_ SG_ 274 YRS_112_AliveCounter "YRS_112_ AliveCounter";
CM_ SG_ 298 ESP_12A_CheckSum "ESP_12A_Message checksum_( E2E data ID: 0x54)";
CM_ SG_ 298 ESP_12A_AliveCounter "EP_12A_Message CounterESP_12A_AliveCounter";
CM_ SG_ 298 ESP_ExtBrkReqFlg "External brake request flag bitEnable bit for qTargetExternal.";
CM_ SG_ 298 ESP_FBldgCtrlSts "Electro-hydraulic coordination state positionControl state of force-blending interface to activate or hold teh pedal force compenasation.";
CM_ SG_ 298 ESP_ExtBrkReq "External braking requestTarget volume flow for external brake request (EBR) by iBooster.";
CM_ SG_ 298 ESP_MstCylVirtPTarValVld "Effective position of virtual pressure target value of master cylinderQualifier for pMcVirtual.";
CM_ SG_ 298 ESP_MstCylTarPVld "Effective position of master cylinder target pressureQualifier for pForceBlendingMc.";
CM_ SG_ 298 ESP_StopMain2BackupState "Brake master state to brake backup mode";
CM_ SG_ 32 Syn_TripCntrVal_Byte0_All "Trip Counter Value";
CM_ SG_ 32 Syn_TripCntrVal_Byte1_All "Trip Counter Value";
CM_ SG_ 32 Syn_RstCntrVal_Byte0_All "Reset Counter Value";
CM_ SG_ 32 Syn_RstCntrVal_Byte1_All "Reset Counter Value";
CM_ SG_ 32 Syn_RstCntrVal_Byte2_All "Reset Counter Value";
CM_ SG_ 32 Syn_MACInfo_Byte0_All "Synchronization message Mac Info";
CM_ SG_ 32 Syn_MACInfo_Byte1_All "Synchronization message Mac Info";
CM_ SG_ 32 Syn_MACInfo_Byte2_All "Synchronization message Mac Info";
CM_ SG_ 89 ACU_59_CheckSum "ACU_59_CheckSum (E2E data ID: 0x98) ";
CM_ SG_ 89 ACU_59_AliveCounter "ACU_0x59_Message counterACU_59_AliveCounter";
CM_ SG_ 89 ACU_FrntCrashOutpSts "Front Crash Status";
CM_ SG_ 89 ACU_RiSideCrashOutpSts "Right Side Crash Status";
CM_ SG_ 89 ACU_LeSideCrashOutpSts "Left Side Crash Status";
CM_ SG_ 89 ACU_RearCrashOutpSts "Rear Crash Status";
CM_ SG_ 89 ACU_RollovrCrashOutpSts "Rollover Crash Status";
CM_ SG_ 89 ACU_Crash_cfm "Crash confirm signal";
CM_ SG_ 275 YRS_113_CheckSum "YRS_113_Message Checksum (E2E data ID: 0xB8)";
CM_ SG_ 275 YRS_113_AliveCounter "YRS_113_AliveCounter";
CM_ SG_ 275 YRS_LgtSnsrSts "Status of lateral sensorIndicates Lateral Sensor State.";
CM_ SG_ 275 YRS_LgtAcce "Longitudinal acceleration (Forward positive, Backward negative, Real Value = raw value-offset)Indicates Longitudinal Acceleration";
CM_ SG_ 276 ESP_114_CheckSum "ESP_114_Message checksum (E2E data ID: 0x72)";
CM_ SG_ 276 ESP_114_AliveCounter "EP_114 _Message counter";
CM_ SG_ 276 ESP_OTARdy_Fb "ESP OTA ready status feedback";
CM_ SG_ 276 ESP_FltIndcn_DTC "ESP/TCS fault indication Signal indicates failure monitoring of ESP function. Not used for ABS";
CM_ SG_ 276 ESP_ActvSig_VDC "ESP activation signal VDC operating When ESP is active shall the system send out a bus signal. Not used for ABS.";
CM_ SG_ 276 ESP_ActvSig_TCS "TCS activation signal TCS operating(including DTC operating)When TCS is active shall the system send out a bus signal. Not used for ABS.";
CM_ SG_ 276 ESP_ActvSig_EBD "EBD activation signal indicating EBD in active control or not.";
CM_ SG_ 276 ESP_ActvSig_DTC "DTC activation signal indicate DTC in active control or not.";
CM_ SG_ 276 ESP_WarningOn "ESP brake fault turning on request With this signal ESP requests the warning in the dashboard.";
CM_ SG_ 276 ESP_Actvndcn_CDD "CDD operation indication indicating CDD is working or not.";
CM_ SG_ 276 ESP_FltIndcn_CDD "CDD fault indication indicating CDD is available or not.";
CM_ SG_ 276 ESP_ActvIndcn_ABA "ABA working indication ABA is active.";
CM_ SG_ 276 ESP_FltIndcn_ABA "ABA fault indication the ABA function is available.";
CM_ SG_ 276 ESP_ActvIndcn_ABP "ABP operation indication Prefill (ABP) is active.";
CM_ SG_ 276 ESP_FltIndcn_ABP "ABP fault indication Prefill (ABP) is available.";
CM_ SG_ 276 ESP_ActvIndcn_AEB "AEB operation indication ESP is excuting AEB braking function.";
CM_ SG_ 276 ESP_FltIndcn_AEB "AEB fault indication AEB is available.";
CM_ SG_ 276 ESP_ActvIndcn_AWB "AWB operation indication AWB is active(brake jerk).";
CM_ SG_ 276 ESP_FltIndcn_AWB "AWB fault indication AWB is available. Feedback of AWB activation for ACC.";
CM_ SG_ 276 ESP_VehStandstillIndcn "Vehicle stop indication indicating whether the vehicle is standstill or not; must not be set until standstill is surely reached.";
CM_ SG_ 276 ESP_BrkOverTIndcn "Brake disc high temperature indication , set 1 to exit ACC function indicating brake temperature too high or not.";
CM_ SG_ 276 ESP_FltIndcn_VDC "ESP/TCS fault indication Signal indicates failure monitoring of ESP function. Not used for ABS";
CM_ SG_ 276 ESP_ActvIndcn_CDD_AP "ECS Active indication_CDD_APWhen VLC AP is active shall the system send out a bus signal.";
CM_ SG_ 276 ESP_FltIndcn_CDD_AP "Signal from ESC indicates whether CDD_AP is activated When VLC AP is active shall the system send out a bus signal.";
CM_ SG_ 277 ESP_115_CheckSum "ESP_115_Message checksum (E2E data ID: 0x8A)";
CM_ SG_ 277 ESP_115_AliveCounter "EP_115 _Message counter";
CM_ SG_ 277 ESP_WhlSpd_RF "Right front wheel speed Wheel speed of the front right wheel.";
CM_ SG_ 277 ESP_WhlSpdVld_RF "Effective right front wheel speed Validty of signal 'WHEEL_SPEED_FRONT_RIGHT_ACC '";
CM_ SG_ 277 ESP_WhlMovgDir_RF "Front right wheel movement direction (positive forward and negative backward)Front Right wheel Moving direction.";
CM_ SG_ 277 ESP_WhlMovgDir_LF "Front left wheel movement direction (positive forward and negative backward)Front left wheel Moving direction.";
CM_ SG_ 277 ESP_WhlSpd_LF "Left front wheel speed Wheel speed of the front left wheel.";
CM_ SG_ 277 ESP_WhlSpdVld_LF "Effective position of left front wheel speed Validty of signal 'WHEEL_SPEED_FRONT_LEFT_ACC'";
CM_ SG_ 278 ESP_116_CheckSum "ESP_116_Message checksum (E2E data ID: 0x9F)";
CM_ SG_ 278 ESP_116_AliveCounter "EP_116 _Message counter";
CM_ SG_ 278 ESP_WhlSpd_RR "Right rear wheel speed Wheel speed of the rear right wheel.";
CM_ SG_ 278 ESP_WhlSpdVld_RR "Right rear wheel speed effective position Validty of signal 'WHEEL_SPEED_REAR_RIGHT_ACC'.";
CM_ SG_ 278 ESP_WhlMovgDir_RR "Movement direction of right rear wheel (positive forward and negative backward)Rear Right wheel Moving direction.";
CM_ SG_ 278 ESP_WhlMovgDir_RL "Movement direction of left rear wheel (positive forward and negative backward)Rear left wheel Moving direction.";
CM_ SG_ 278 ESP_WhlSpd_RL "Left rear wheel speed Wheel speed of the rear left wheel.";
CM_ SG_ 278 ESP_WhlSpdVld_RL "Effective left rear wheel speed Validty of signal 'WHEEL_SPEED_REAR_LEFT_ACC'.";
CM_ SG_ 281 iBooster_119_CheckSum "iBooster_119_Message Checksum (E2E data ID: 0xA4)";
CM_ SG_ 281 iBooster_119_AliveCounter "iBooster_119_Message CounteriBooster_119_AliveCounter";
CM_ SG_ 281 iBooster_OTARdy_Fb "iBooster OTA ready status feedback";
CM_ SG_ 281 iBooster_WarnOn "Required instrument display fault warning lamp With this signal eBooster requests the warning lamp in the dashboard.";
CM_ SG_ 281 iBooster_BrkPedlAppldFlg "Press the brake pedal to the mark position information about the driver attendance.";
CM_ SG_ 281 iBooster_BrkPedlAppldVld "State bit of the brake pedal depressed flag position Qualifier for Brake Pedal Applied.";
CM_ SG_ 288 ESP_120_CheckSum "ESP_120_Message checksum (E2E data ID: 0xB1)";
CM_ SG_ 288 ESP_120_AliveCounter "EP_120_Message CounterESP_120_AliveCounter";
CM_ SG_ 288 ESP_ActvSig_ABS "ABS activation signal ABS operating When ABS is active shall the system send out a bus signal.";
CM_ SG_ 288 ESP_MstCylP "Master cylinder pressure (Real value = raw value-offset)Current pressure of the master cylinder pressure sensor in the ESP. Raw value without offset compensation.";
CM_ SG_ 288 ESP_MstCylPOffs "Master cylinder pressure offset Master cylinder pressure offset.(Real value = raw value ¨C offset)";
CM_ SG_ 288 ESP_MstCylPVld "Effective pressure of master cylinder Information about signal quality of pMC1.";
CM_ SG_ 288 ESP_MstCylPOffsVld "Effective position of master cylinder pressure offset Valid Information of the signal.";
CM_ SG_ 288 ESP_TotBrkTqReq "(Total driver braking torque requirement)This signal with driver general brake torque request.";
CM_ SG_ 293 ESP_125_CheckSum "ESP_125_Message checksum (E2E data ID: 0x91)";
CM_ SG_ 293 ESP_125_AliveCounter "EP_125_Message counterESP_125_AliveCounter";
CM_ SG_ 293 ESP_WhlOdoEdges_FL "Left front wheel speed pulse accumulation Wheel speed Odo Edges front left wheel.";
CM_ SG_ 293 ESP_WhlOdoEdges_FR "Right front wheel speed pulse accumulation Wheel speed Odo Edges front right wheel.";
CM_ SG_ 293 ESP_WhlOdoEdges_RL "Trunk of left rear wheel speed Wheel speed Odo Edges rear left wheel.";
CM_ SG_ 293 ESP_WhlOdoEdges_RR "Right rear wheel speed pulse accumulation Wheel speed Odo Edges rear right wheel.";
CM_ SG_ 293 ESP_WhlOdoEdgesVld_FL "Cumulative effective bit of left front wheel speed pulseValidty of signal 'ESP_WhlOdoEdges_FL'.";
CM_ SG_ 293 ESP_WhlOdoEdgesVld_FR "Cumulative effective bit of right front wheel speed pulseValidty of signal 'ESP_WhlOdoEdges_FR'.";
CM_ SG_ 293 ESP_WhlOdoEdgesVld_RL "Effective accumulative value of left rear wheel speed pulse Validty of signal 'ESP_WhlOdoEdges_RL'.";
CM_ SG_ 293 ESP_WhlOdoEdgesVld_RR "Effective sum of right rear wheel speed pulse Validty of signal 'ESP_WhlOdoEdges_RR'.";
CM_ SG_ 372 TBOX_174_CheckSum "TBOX_174_message checksum (E2E Data ID: 0x66)";
CM_ SG_ 372 TBOX_174_AliveCounter "TBOX_174_message counter";
CM_ SG_ 372 TBOX_XAcce "X Acceleration";
CM_ SG_ 372 TBOX_XVelocity "X Velocity";
CM_ SG_ 372 TBOX_XAgrRate "X Angular Rate";
CM_ SG_ 373 TBOX_175_CheckSum "TBOX_175_message checksum (E2E Data ID: 0x67)";
CM_ SG_ 373 TBOX_175_AliveCounter "TBOX_175_message counter";
CM_ SG_ 373 TBOX_YAcce "Y Acceleration";
CM_ SG_ 373 TBOX_YVelocity "Y Velocity";
CM_ SG_ 373 TBOX_YAgrRate "Y Angular Rate";
CM_ SG_ 374 TBOX_176_CheckSum "TBOX_176_message checksum (E2E Data ID: 0x64)";
CM_ SG_ 374 TBOX_176_AliveCounter "TBOX_176_message counter";
CM_ SG_ 374 TBOX_ZAcce "Z Acceleration";
CM_ SG_ 374 TBOX_ZVelocity "Z Velocity";
CM_ SG_ 374 TBOX_ZAgrRate "Z Angular Rate";
CM_ SG_ 375 TBOX_177_CheckSum "TBOX_177_message checksum (E2E Data ID: 0x69)";
CM_ SG_ 375 TBOX_177_AliveCounter "TBOX_177_message counter";
CM_ SG_ 375 TBOX_DftlAge "Differential Age";
CM_ SG_ 375 TBOX_Pitch_A "Pitch";
CM_ SG_ 375 TBOX_PitchStdDev "Pitch Std Dev";
CM_ SG_ 376 TBOX_178_CheckSum "TBOX_178_message checksum (E2E Data ID: 0x6A)";
CM_ SG_ 376 TBOX_178_AliveCounter "TBOX_178_message counter";
CM_ SG_ 376 TBOX_Roll "Roll";
CM_ SG_ 376 TBOX_RollStdDev "Roll Std Dev";
CM_ SG_ 377 TBOX_179_CheckSum "TBOX_179_message checksum (E2E Data ID: 0x6B)";
CM_ SG_ 377 TBOX_179_AliveCounter "TBOX_179_message counter";
CM_ SG_ 377 TBOX_Heading "Vehicle heading";
CM_ SG_ 377 TBOX_HeadingStdDev "Vehicle heading Std Dev";
CM_ SG_ 440 ESP_1B8_CheckSum "ESP _1B8_Message checksum (E2E data ID: 0xC1)";
CM_ SG_ 440 ESP_1B8_AliveCounter "EP_1B8_Message counterESP_1B8_AliveCounter";
CM_ SG_ 440 ESP_ModFbSig "ESP mode feedback signal ESP mode feedback signal";
CM_ SG_ 440 ESP_ModSwtAllw "Whether ESP allows switching mode ESP Special terrain mode switch allowed";
CM_ SG_ 440 ESP_ActvVehHldFlg "ESP actively builds the brake stop vehicle flag position Flag whether the vehicle is actively held by ESP pressure built up.";
CM_ SG_ 440 ESP_VehSecuCdn "Vehicle safety condition .Indicates security states when request security condition.";
CM_ SG_ 440 ESP_BrkFStsFlg "Whether ESP has brake force Flag whether ESP there is brake force present.";
CM_ SG_ 440 ESP_CddApOpsDirMovmt "CDD_AP flag for identification of opposite direction motion Flag whether CDDAP recognises an opposite direction movement.";
CM_ SG_ 440 ESP_VehStopSts "Vehicle stop signal (fully stationary)Flag whether vehicle is in stop.";
CM_ SG_ 440 ESP_VehStandstillSts "Vehicle stop signal (v < 3 km/h)flag whether vehicle is in standstill.";
CM_ SG_ 440 ESP_RoadSlopVld "Whether the slope signal is Valid";
CM_ SG_ 440 ESP_AEBRdy "AEB ready status signal from ESP";
CM_ SG_ 440 ESPACCRdy "ACC ready status signal from ESP";
CM_ SG_ 440 ESP_ParkRdy "Park ready status signal from ESP";
CM_ SG_ 440 ESP_ReAEBRdy "ReAEB ready status signal from ESP";
CM_ SG_ 440 ESP_RoadSlop " Road gradient ";
CM_ SG_ 440 ESP_SpclTerrainModFltIndcn "ESP all-terrain mode fault indication ATM Available";
CM_ SG_ 440 ESP_DrvOffStRdy "Does the drive off flag be supported in the current LSMLSM confirmation that all conditions are fullfilled to support parking maneuver";
CM_ SG_ 440 ESP_TarLSMSts " LSM status of ESP request";
CM_ SG_ 450 EPS_1C2_CheckSum "EPS_1C2_Message check ( E2E data ID: 0x90)";
CM_ SG_ 450 EPS_1C2_AliveCounter "EP_1C2 _Message counterEPS_1C2_AliveCounter";
CM_ SG_ 450 EPS_AbortFb "EPS control interruption reason";
CM_ SG_ 450 EPS_SteerWhlAgSig "Steering wheel angle signal (counterclockwise as positive, clockwise as negative)Steering wheel angle left is positive, right is negative.
";
CM_ SG_ 450 EPS_SteerAgSnsrCalSts "Calibration state of rotation angle sensor SAS Calibration status.";
CM_ SG_ 450 EPS_SteerWhlAgSigVld "Effective bit of steering wheel angle signal indicate Steer Wheel Angle signal valid or not.";
CM_ SG_ 450 EPS_SteerWhlRotSpdDir "Steering wheel speed direction Rotation speed direction of the steering wheel.";
CM_ SG_ 450 EPS_SteerWhlRotSpdVld "Effective Position of Steering Wheel Speed";
CM_ SG_ 450 EPS_SteerWhlRotSpd "Steering wheel speed (counterclockwise is positive, clockwise is negative)Rotation speed of the steering wheel.";
CM_ SG_ 450 EPS_AdasLatCtrlSts "EPS system available state Electrical Power Steering Available Status.";
CM_ SG_ 450 EPS_AdasLatCtrlStsVld "EPS system available state Electrical Power Steering Available valid Status.";
CM_ SG_ 450 EPS_AsscMotCrtTq "Current torque of EPS booster motor";
CM_ SG_ 452 EPS_1C4_CheckSum "EPS_1C4_Message check ( E2E data ID: 0x9C)";
CM_ SG_ 452 EPS_1C4_AliveCounter "EP_1C4EPS_1C4_AliveCounter";
CM_ SG_ 452 EPS_DrvrSteerTqDir "Driver steering torque direction (0 in counterclockwise and 1 in clockwise)";
CM_ SG_ 452 EPS_DrvrSteerTqVld "Effective Position of Driver Steering Torque";
CM_ SG_ 452 EPS_DrvrSteerTq "Driver steering torque";
CM_ SG_ 452 EPS_OTARdy_Fb "EPS OTA ready status feedback";
CM_ SG_ 452 EPS_DrvrIntvSteerWhlDetd "Detect driver intervention on steering wheel Driver Steering Interference Detected.";
CM_ SG_ 452 EPS_DrvrIntvSteerWhlVld "Effective position of driver intervention on steering wheel Driver Steering Interference Detected Validity.";
CM_ SG_ 452 EPS_SteerSnsrSts "Rotation angle sensor status SAS_Failure_Status.";
CM_ SG_ 452 EPS_PinionAg "Pinion rotation angle (positive counterclockwise, negative clockwise)";
CM_ SG_ 532 VCU_214_234_CheckSum "VCU_214_Message checksum (E2E data ID: 0x12)";
CM_ SG_ 532 VCU_214_234_AliveCounter "VCU_214_Packet counterVCU_214_AliveCounter";
CM_ SG_ 532 VCU_RdyLamp "READY lamp";
CM_ SG_ 532 VCU_BrkLampCtrlSts "Stop lamp control state";
CM_ SG_ 532 VCU_RemWakeUpEndFlg "Terminal wake-up end flag bit";
CM_ SG_ 532 VCU_StgyGearSig "Strategy gear signal";
CM_ SG_ 532 VCU_ShiftMisoper "Gear misoperation";
CM_ SG_ 532 VCU_GearSigVld "Effective bit of gear signal";
CM_ SG_ 532 VCU_GearSig "Gear signal";
CM_ SG_ 532 VCU_ACCRdy "ACC ready signal from VCU";
CM_ SG_ 532 VCU_ParkRdy "Park ready signal from VCU";
CM_ SG_ 532 VCU_APSPercVld "Effective position of accelerator pedal opening";
CM_ SG_ 532 VCU_VehSt "State of complete vehicle";
CM_ SG_ 532 VCU_APSPerc "Accelerator pedal opening";
CM_ SG_ 532 VCU_BrkSig "Brake signal";
CM_ SG_ 532 VCU_BrkSigVld "Effective bit of brake signal";
CM_ SG_ 532 VCU_DrvModSigFb "Driving mode signal feedback to ICC";
CM_ SG_ 532 VCU_DrvModShiftMisoper "Driving mode switching error operation";
CM_ SG_ 532 VCU_SpclTerrainModEnaSig "All-terrain driving mode enable signal";
CM_ SG_ 532 VCU_214_SSecOC_Fresh_Byte0 "Short SecOC Fresh signal byte 0 on CAN";
CM_ SG_ 532 VCU_214_SSecOC_MAC_Byte0 "Short SecOC MAC signal byte 0 on CAN";
CM_ SG_ 532 VCU_214_SSecOC_MAC_Byte1 "Short SecOC MAC signal byte 1 on CAN";
CM_ SG_ 532 VCU_214_SSecOC_MAC_Byte2 "Short SecOC MAC signal byte 2 on CAN";
CM_ SG_ 778 ESP_30A_CheckSum "ESP_30A_Message checksum ( E2E data ID: 0x74)";
CM_ SG_ 778 ESP_30A_AliveCounter "EP_30A_Message CounterESP_30A_AliveCounter";
CM_ SG_ 778 ESP_LgtOffs "Longitudinal acceleration offset It is used with Longitudinal acceleration raw data (Real value = raw value ¨C offset).";
CM_ SG_ 778 ESP_LatOffs "Lateral acceleration offset It is used with Lateral acceleration raw data (Real value = raw value ¨C offset).";
CM_ SG_ 778 ESP_YAWVOffs "Yaw velocity offset It is used with YAW veloctity raw data (Real value = raw value ¨C offset).";
CM_ SG_ 784 CIM_310_CheckSum "CIM_310_Message checksum ( 0xC8)CIM_310_CheckSum";
CM_ SG_ 784 CIM_310_AliveCounter "CIM_310_Message counterCIM_310_AliveCounter";
CM_ SG_ 784 CIM_TurnLampSwtSts "Turn signal lamp switch stateturn signal lever status.";
CM_ SG_ 784 CIM_HiBeamSwtSts "High beam switch stateHigh beam switch status.";
CM_ SG_ 784 CIM_FrntWshrSwtSts "Status of front washer switchWasherFrontCommand.";
CM_ SG_ 784 CIM_FrntWiprSwtSts "Front wiper wiper switch stateWiper front command.";
CM_ SG_ 792 ESP_318_CheckSum "ESP318_Message Checksum ( E2E data ID: 0x79)";
CM_ SG_ 792 ESP_318_AliveCounter "ESP 3318_Message counterESP_318_AliveCounter";
CM_ SG_ 792 ESP_BrkPedlStsVld "Effective position of brake pedal state validity of BRAKE_STATUS_ESP.";
CM_ SG_ 792 ESP_BrkPedlSts "Brake pedal state indicating brake pedal activated by driver or not.";
CM_ SG_ 792 ESP_VehSpdVld "ABS_ESC signal indicates whether the vehicle speed is valid When the diagnostic have set the failure code on this signal the value wil be 2.";
CM_ SG_ 792 ESP_SysActv "ESP works effectively Is used to indicate to the driver that the system is currently active. Not used for ABS.";
CM_ SG_ 792 ESP_LampSwtOffIndcn "ESP OFF indication Signal indicates to light up 'TCS/ESP off' lamp.-manual switch off of ESP function (on/off switch).Not used for ABS.";
CM_ SG_ 792 ESP_FltIndcn_EBD "EBD fault indication Signal indicates to light up EBD lamp.";
CM_ SG_ 792 ESP_FltIndcn_ABS "ABS fault indication Signal indicates to light up ABS lamp.";
CM_ SG_ 792 ESP_MilgRollgCntr_ODO "Mileage statistical pulse Odometer rolling count 1 pulse/bit. The value shall be set to zero at every ignition off and if the counter reach max value it starts from zero again.";
CM_ SG_ 792 ESP_VehSpd "Speed signal";
CM_ SG_ 792 ESP_IninModSigIndcn "The signal needs to cover the time of ESP and ABS fault signals caused by self-inspection. Signal indicates if ESP or ABS is in initialization mode or not.";
CM_ SG_ 792 ESP_FltIndcn_TCS "ESP/TCS fault indication Signal indicates failure monitoring of ESP function. Not used for ABS";
CM_ SG_ 792 ESP_CtrlSts_HDC "Indicate that the HDC is on/off or working, and the ADAS receives this signal to determine whether the ACC is off. HDC control(Off/On, not active braking/On, active braking).";
CM_ SG_ 792 ESP_AvlIndcn_HDC "Effective bit of HDC indicating HDC is available or not.";
CM_ SG_ 792 ESP_NoBrkP "When the vehicle is stationary, whether the function has braking force or not, whether it is braking.no brake pressure applied; generally it regards wheel cylinder presure.";
CM_ SG_ 792 ESP_RDAEnaFlg "ESP remote driving function enable flag position";
CM_ SG_ 819 BCM_333_CheckSum "BCM333_message checksum ( 0xCB)BCM_333_CheckSum";
CM_ SG_ 819 BCM_333_AliveCounter "BCM333_Packet counterBCM_333_AliveCounter";
CM_ SG_ 819 BCM_KL15_Off_Announcement "Before switching off the KL15 (5s), this signal gets active to inform other ECUs that the KL15 will be disabled in 5seconds if there are still no triggers to keep it active";
CM_ SG_ 819 BCM_IG1Sts "IG1 state";
CM_ SG_ 819 BCM_PwrMod "Power mode";
CM_ SG_ 819 BCM_PwrModVld "Effective value of power mode";
CM_ SG_ 819 BCM_BrkSwtSts "Brake switch status";
CM_ SG_ 819 BCM_IG1StsVld_CAPE "Effective value of IG1 state";
CM_ SG_ 819 BCM_IG2StsVld_CAPE "Effective value of IG2 state";
CM_ SG_ 819 BCM_KL30s_L "Logical State of KL30";
CM_ SG_ 819 BCM_IG2Sts "IG2 state";
CM_ SG_ 819 BCM_InteriorSwtSt "Interior switch status from LIN1";
CM_ SG_ 821 BCM_335_CheckSum "BCM_335_Message checksum ( 0xD4)BCM_335_CheckSum";
CM_ SG_ 821 BCM_335_AliveCounter "BC_335_Message counterBCM_335_AliveCounter";
CM_ SG_ 821 BCM_WiprInSrvPosn "Whether the electronic wiper is in the service position";
CM_ SG_ 821 BCM_IntLampTiSetSts "Central control interior lamp door control delay time setting state";
CM_ SG_ 821 BCM_WaterPosnSnsrSwtSts "Condition of level sensor switch";
CM_ SG_ 821 BCM_FrntFogLampOutpCmd "Front fog lamp output command";
CM_ SG_ 821 BCM_LicPlateLampOutpCmd "License plate lamp output command";
CM_ SG_ 821 BCM_EnaSts_ADB "ADB enable";
CM_ SG_ 821 BCM_PwrSaveOutpCmd "Power saving output command";
CM_ SG_ 821 BCM_ExtLampSwtSts "Outside lamp switch status";
CM_ SG_ 821 BCM_HornOutpCmd "Horn output command";
CM_ SG_ 821 BCM_HornSwtSts "Horn switch state";
CM_ SG_ 821 BCM_WelLampOutpCmd "Approach lamp output command";
CM_ SG_ 821 BCM_FolwMeHomeSts "Follow me home state";
CM_ SG_ 821 BCM_FrntFogLampSwtSts "Front fog lamp switch state";
CM_ SG_ 821 BCM_ReFogLampSwtSts "Rear fog lamp switch state";
CM_ SG_ 821 BCM_ReWiprBackSwtSts "State of rear wiper return switch";
CM_ SG_ 821 BCM_RainClsSunroofSetSts "Central control screen closing sunroof setting state in rainy days";
CM_ SG_ 821 BCM_MirrLockAutoSetSts "Central control rearview mirror locking automatic folding setting state";
CM_ SG_ 821 BCM_FrntWshrOutpCmd "Front washing output command";
CM_ SG_ 821 BCM_DangerAlrmLampSwtSts "Hazard warning lamp switch state";
CM_ SG_ 821 BCM_ReDefrstHeatgCmd "Rear defrosting heating command";
CM_ SG_ 821 BCM_RvsLampOutpCmd "Reverse lamp output command";
CM_ SG_ 821 BCM_IntLampOutpCmd "Output state of internal lamp";
CM_ SG_ 821 BCM_LeTrunLampOutpCmd "Left turn signal lamp output command";
CM_ SG_ 821 BCM_RiTrunLampOutpCmd "Right turn signal lamp output command";
CM_ SG_ 821 BCM_ReWiprOutpCmd "Rear wiper output command";
CM_ SG_ 821 BCM_ReWshrOutpCmd "Rear washer output command";
CM_ SG_ 821 BCM_BrkLampSwtSts "Brake lamp switch state";
CM_ SG_ 821 BCM_HiBeamOutpCmd "High beam output command";
CM_ SG_ 821 BCM_LoBeamOutpCmd "Low beam output command";
CM_ SG_ 821 BCM_PosnLampOutpCmd "Position lamp output command";
CM_ SG_ 821 BCM_BrkLampOutpCmd "Brake lamp output command";
CM_ SG_ 821 BCM_ReFogLampOutpCmd "Rear fog lamp output command";
CM_ SG_ 821 BCM_FrntWiprSpd "Front wiper speed";
CM_ SG_ 821 BCM_EnaReq_ADB "ADB enable state feedback";
CM_ SG_ 821 BCM_VehAmbBri "Ambient light detection value output";
CM_ SG_ 822 ICC_336_Checksum "EHU336_Message checksum ( 0xE5)EHU_336_Checksum";
CM_ SG_ 822 ICC_336_AliveCounter "EHU336_Message CounterEHU_336_AliveCounter";
CM_ SG_ 822 ICC_SetAtmLampBri "Set the ambient light brightness";
CM_ SG_ 822 ICC_SuspSet "Suspension set";
CM_ SG_ 822 ICC_AtmLampOpenCmd "Atmosphere lamp opening command";
CM_ SG_ 822 ICC_SteerAssiSet "Steering Assist set";
CM_ SG_ 822 ICC_SetStorageBriLvl "Set brightness of storage lights";
CM_ SG_ 822 ICC_HDCSwtSig "HDC switch signalHDC switch, pressed or not.";
CM_ SG_ 822 ICC_ESPSwtSig "ESP switch signalESP switch, pressed or not.";
CM_ SG_ 822 ICC_ReqCalifModHMIBtn "California HMI button";
CM_ SG_ 822 ICC_SpdLimOffs "Speed limit deviation (reserved)";
CM_ SG_ 822 ICC_iTPMSResetSig "iTPMS reset signal";
CM_ SG_ 822 ICC_WIFIOnOffSig "Send WIFI ON/OFF signal to TBOX";
CM_ SG_ 822 ICC_LeMirrAlrmLampFlt "Left reflector warning lamp fault";
CM_ SG_ 822 ICC_RiMirrAlrmLampFlt "Right reflector warning lamp fault";
CM_ SG_ 822 ICC_PhoneSt "Phone is being usedPhone status";
CM_ SG_ 822 ICC_SpeechSt "Speech statusIndication of someone talking to a vehicle application, like navigation.";
CM_ SG_ 822 ICC_RemReqFb "Feeback signal to TBOX_RemSWH_Req from ICC to TBOX";
CM_ SG_ 822 ICC_SpdLimFdb "Feeback signal to TBOX_SpdLim from ICC to TBOX";
CM_ SG_ 822 ICC_OTARdy_Fb "ICC OTA ready status feedback";
CM_ SG_ 837 BCM_345_CheckSum "BCM_345_Message checksum ( 0xD9)BCM_345_CheckSum";
CM_ SG_ 837 BCM_345_AliveCounter "BCM345_Packet counterBCM_345_AliveCounter";
CM_ SG_ 837 BCM_OutpValResl_HUD "HUD output value resolution";
CM_ SG_ 837 BCM_SunshadeRunngSts "Sunshade running status";
CM_ SG_ 837 BCM_RiSolaValr_RLS "Solar radiation intensity at the right side";
CM_ SG_ 837 BCM_LeSolaValr_RLS "Left solar radiation intensity";
CM_ SG_ 837 BCM_WindshdHum_RLS "Glass humidity";
CM_ SG_ 837 BCM_WindshdT_RLS "Glass temperature";
CM_ SG_ 837 BCM_MeasdVal_HUD "HUD function measurement value";
CM_ SG_ 837 BCM_SunshadePosnInfo "Sunshade opening information";
CM_ SG_ 856 VCU_358_CheckSum "VCU_0x358_Message Check (E2E data ID: 0x47)";
CM_ SG_ 856 VCU_358_AliveCounter "VCU_0x358_Message counter";
CM_ SG_ 856 VCU_KickdwnFlg "status of kickdown function ";
CM_ SG_ 856 VCU_EPedlEnaSig "E-Pedal enable signal (TBD if required)";
CM_ SG_ 856 VCU_ComLostFlt_ESP "VCU and ESP communication related faults";
CM_ SG_ 856 VCU_ComFlt_iBooster "VCU and iBooster communication failure_U101587_E03";
CM_ SG_ 856 VCU_RegenLvlFb "Coasting Mode settings (Off, Normal, high) feedback to ICC";
CM_ SG_ 856 VCU_AccelModFb "Acceleration Mode setting (Low/Mid/High) feedback to ICC";
CM_ SG_ 856 VCU_EPedlStsFb "Pedal Comport Setting (One Pedal Drive / Roll / Creep) feedback to ICC";
CM_ SG_ 856 VCU_CcTrgSpdDisp "Cruise Control Target Speed display";
CM_ SG_ 856 VCU_Sts_CC_ICC "ACC status";
CM_ SG_ 856 VCU_CCIconDisp "ACC icon color";
CM_ SG_ 856 VCU_DispSpdUnit_CC "CC display speed unit";
CM_ SG_ 856 VCU_BoostEnStat "Boost Enable Status";
CM_ SG_ 856 VCU_OTARdy_Fb "VCU OTA ready status feedback";
CM_ SG_ 856 VCU_OTA_ECUInhb_Req "VCU OTA inhibit request to ECUs";
CM_ SG_ 856 VCU_OTAVehCdnChk_ASIL "ASIL A group OTA vehicle condition check status";
CM_ SG_ 856 VCU_OTAVehInhb_ASIL_Fb "ASIL A group OTA vehicle Inhibit feedback";
CM_ SG_ 866 ICC_MetaCountryCode "Country codeISO 3166-1 Release 2007-03 country code of current position;0 stands for unknown. Valid values are those specified by ISO 3166-1 numeric [14].";
CM_ SG_ 866 ICC_MetaMapProvider "Map providers of the current area (map tile, area, country...).";
CM_ SG_ 866 ICC_MetaMsgType "Identify the message bit";
CM_ SG_ 866 ICC_MetaHwVer "Hardware and/or software version of generator";
CM_ SG_ 866 ICC_MetaProtVerMinorSub "Secondary agreement sub-versionContains Minor protocol sub-version.";
CM_ SG_ 866 ICC_MetaProtVerMajor "Main agreement versionContains Major protocol version.";
CM_ SG_ 866 ICC_MetaCycCnt "This message type loop counter: The reconstructor can use this value to detect missing messagesCyclic counter of this message type:Reconstructor can use this value to detect missing messages.";
CM_ SG_ 866 ICC_MetaRegionCode "Area code0 stands for unknown, value 32767 means N/AAll other values are based on ISO 3166-2 [15] with the code mapping scheme.";
CM_ SG_ 866 ICC_MetaDrvSide "Driving direction";
CM_ SG_ 866 ICC_MetaMapVerYear "Map version (year)Please note if the whole map may be partitioned into parts that can be released on different times or even by different providers. In that case, value of this field may vary between messages. 63 stands for N/A";
CM_ SG_ 866 ICC_MetaMapVerQtr "Map version (quarter)Please note if the whole map may be partitioned into parts that can be released on different times or even by different providers. In that case, value if this field may vary between messages.";
CM_ SG_ 866 ICC_MetaProtVerMinor "Minor agreement version";
CM_ SG_ 866 ICC_MetaSpdUnits "Speed limit unit";
CM_ SG_ 866 ICC_Reserved "Reserved space";
CM_ SG_ 883 ECC_CrtSts "ECC current state";
CM_ SG_ 883 ECC_IninSts "ECC initialization state";
CM_ SG_ 883 ECC_PwrSysHeatMngtSts "Power system thermal management state";
CM_ SG_ 883 ECC_ACSts "A/C state";
CM_ SG_ 883 ECC_AirClnSts "Air purification state";
CM_ SG_ 883 ECC_WindSpdSts "Wind speed state";
CM_ SG_ 883 ECC_BackRowAirOutlModSts "Rear exhaust mode state";
CM_ SG_ 883 ECC_DrvrTSetSts "Main driving temperature setting state";
CM_ SG_ 883 ECC_PassTSetSts "Temperature setting state of front passenger";
CM_ SG_ 883 ECC_HeatSts "HEAT state";
CM_ SG_ 883 ECC_AUTOSts "A/C AUTO state";
CM_ SG_ 883 ECC_SYNCSts "SYNC state";
CM_ SG_ 883 ECC_InfoSysWrmColdDisp "Display of heating and cooling degree of entertainment system";
CM_ SG_ 883 ECC_CircSts "Cycle state";
CM_ SG_ 883 ECC_ParticleConcVld "Effective position of particle concentration";
CM_ SG_ 883 ECC_OutdT "Ambient temperature outside the vehicle";
CM_ SG_ 883 ECC_OutdTVld "Effective position of ambient temperature outside vehicle";
CM_ SG_ 883 ECC_MaxFrntDefrst "Max Front defrosting";
CM_ SG_ 883 ECC_HeatMngtSysFlt "Fault of thermal management system";
CM_ SG_ 883 ECC_HeatMngtFctLim "Requirement for Thermal Management Function of Occupant Compartment";
CM_ SG_ 883 ECC_DrvrAirOutlMod "Driver Air Outlet Mode";
CM_ SG_ 883 ECC_PassAirOutlMod "Front passenger air-out mode";
CM_ SG_ 883 ECC_RemSts "Operating status of remote A/C";
CM_ SG_ 883 ECC_OTAInhbRdy "OTA pre-condition and Inhibiting of all OTA relevant ECUs";
BA_DEF_ BO_  "FBlock" STRING ;
BA_DEF_ BO_  "FunctionClass" ENUM  "Property","Method";
BA_DEF_  "NmAsrWaitBusSleepTime" INT 0 65535;
BA_DEF_  "NmAsrTimeoutTime" INT 0 65535;
BA_DEF_  "NmAsrRepeatMessageTime" INT 0 65535;
BA_DEF_ BU_  "NmAsrNodeIdentifier" HEX 0 255;
BA_DEF_ BU_  "NmAsrNode" ENUM  "No","Yes";
BA_DEF_  "E2EP01ProfileName" STRING ;
BA_DEF_  "NmAsrMessageCount" INT 1 256;
BA_DEF_  "E2EP01ProfileBehavior" ENUM  "PRE_R4_2","R4_2";
BA_DEF_ BO_  "NmAsrMessage" ENUM  "No","Yes";
BA_DEF_ BU_  "NmAsrCanMsgReducedTime" INT 320 640;
BA_DEF_ BU_  "NmAsrCanMsgCycleOffset" INT 0 65535;
BA_DEF_ SG_  "GenSigCycleTime" INT 0 0;
BA_DEF_  "NmAsrBaseAddress" HEX 0 2047;
BA_DEF_  "NmAsrCanMsgCycleTime" INT 0 0;
BA_DEF_ BO_  "NmMessage" ENUM  "No","Yes";
BA_DEF_ BO_  "SC_Message" ENUM  "No","Yes","Yes, split message";
BA_DEF_ BO_  "DiagState" ENUM  "No","Yes";
BA_DEF_ BO_  "SC_LinkPos" INT 0 65535;
BA_DEF_ BO_  "DiagRequest" ENUM  "No","Yes";
BA_DEF_ BO_  "DiagFdOnly" ENUM  "No","Yes";
BA_DEF_ BO_  "DiagResponse" ENUM  "No","Yes";
BA_DEF_ BO_  "SCP_AuthInfoTxLength" INT 0 512;
BA_DEF_  "BusBaudateData" INT 0 10000;
BA_DEF_  "E2EP01DataIdMode" ENUM  "all16Bit","alternating8Bit","lower8Bit","lower12Bit";
BA_DEF_ BO_  "GenMsgSendType" ENUM  "Cyclic","NotUsed","NotUsed","NotUsed","NotUsed","NotUsed","NotUsed","IfActive","NoMsgSendType";
BA_DEF_ BO_  "SCP_DataId" INT 0 65535;
BA_DEF_  "BusBaudateOther" INT 0 10000;
BA_DEF_ BO_  "GenMsgCycleTime" INT 0 0;
BA_DEF_ BO_  "SCP_FreshnessValueId" INT 0 65535;
BA_DEF_ BO_  "SCP_FreshnessValueLength" INT 0 512;
BA_DEF_ SG_  "GenSigStartValue" INT 0 0;
BA_DEF_ BO_  "SCL_CryptographicMessageID" INT 0 65535;
BA_DEF_ SG_  "GenSigInactiveValue" INT 0 0;
BA_DEF_ SG_  "GenSigSendType" ENUM  "Cyclic","OnWrite","OnWriteWithRepetition","OnChange","OnChangeWithRepetition","IfActive","IfActiveWithRepetition","NoSigSendType";
BA_DEF_ BO_  "SCP_FreshnessValueTxLength" INT 0 512;
BA_DEF_ BO_  "GenMsgCycleTimeFast" INT 0 0;
BA_DEF_ BO_  "GenMsgNrOfRepetition" INT 0 0;
BA_DEF_ BO_  "DiagConnection" INT 0 65535;
BA_DEF_ BO_  "GenMsgDelayTime" INT 0 0;
BA_DEF_  "DBName" STRING ;
BA_DEF_  "BusBaudrate" INT 0 10000;
BA_DEF_ BU_  "NodeLayerModules" STRING ;
BA_DEF_ BU_  "ILUsed" ENUM  "No","Yes";
BA_DEF_ BU_  "DiagStationAddress" HEX 0 255;
BA_DEF_ BU_  "NmNode" ENUM  "No","Yes";
BA_DEF_ BU_  "NmStationAddress" HEX 0 65535;
BA_DEF_ BU_  "NmCAN" INT 0 2;
BA_DEF_  "NmType" STRING ;
BA_DEF_  "NmBaseAddress" HEX 1024 2047;
BA_DEF_  "NmMessageCount" INT 0 255;
BA_DEF_ BO_  "CANFD_BRS" ENUM  "0","1";
BA_DEF_ BO_  "VFrameFormat" ENUM  "StandardCAN","ExtendedCAN","reserved","reserved","reserved","reserved","reserved","reserved","reserved","reserved","reserved","reserved","reserved","reserved","StandardCAN_FD","ExtendedCAN_FD";
BA_DEF_ BO_  "GenMsgILSupport" ENUM  "No","Yes";
BA_DEF_ BO_  "GenMsgStartDelayTime" INT 0 65535;
BA_DEF_  "BusType" STRING ;
BA_DEF_ BO_  "E2EP01DataLength" INT 0 65535;
BA_DEF_ BO_  "E2EP01DataId" INT 0 65535;
BA_DEF_ SG_  "sigSecLevel" STRING ;
BA_DEF_ SG_  "sigConfig" STRING ;
BA_DEF_ SG_  "sigExplanation" STRING ;
BA_DEF_DEF_  "FBlock" "GeneralBlock";
BA_DEF_DEF_  "FunctionClass" "Property";
BA_DEF_DEF_  "NmAsrWaitBusSleepTime" 1500;
BA_DEF_DEF_  "NmAsrTimeoutTime" 2000;
BA_DEF_DEF_  "NmAsrRepeatMessageTime" 3200;
BA_DEF_DEF_  "NmAsrNodeIdentifier" 0;
BA_DEF_DEF_  "NmAsrNode" "No";
BA_DEF_DEF_  "E2EP01ProfileName" "PROFILE_01";
BA_DEF_DEF_  "NmAsrMessageCount" 128;
BA_DEF_DEF_  "E2EP01ProfileBehavior" "R4_2";
BA_DEF_DEF_  "NmAsrMessage" "No";
BA_DEF_DEF_  "NmAsrCanMsgReducedTime" 320;
BA_DEF_DEF_  "NmAsrCanMsgCycleOffset" 0;
BA_DEF_DEF_  "GenSigCycleTime" 0;
BA_DEF_DEF_  "NmAsrBaseAddress" 1024;
BA_DEF_DEF_  "NmAsrCanMsgCycleTime" 640;
BA_DEF_DEF_  "NmMessage" "No";
BA_DEF_DEF_  "SC_Message" "No";
BA_DEF_DEF_  "DiagState" "No";
BA_DEF_DEF_  "SC_LinkPos" 0;
BA_DEF_DEF_  "DiagRequest" "No";
BA_DEF_DEF_  "DiagFdOnly" "No";
BA_DEF_DEF_  "DiagResponse" "No";
BA_DEF_DEF_  "SCP_AuthInfoTxLength" 0;
BA_DEF_DEF_  "BusBaudateData" 2;
BA_DEF_DEF_  "E2EP01DataIdMode" "lower8Bit";
BA_DEF_DEF_  "GenMsgSendType" "Cyclic";
BA_DEF_DEF_  "SCP_DataId" 0;
BA_DEF_DEF_  "BusBaudateOther" 500;
BA_DEF_DEF_  "GenMsgCycleTime" 0;
BA_DEF_DEF_  "SCP_FreshnessValueId" 0;
BA_DEF_DEF_  "SCP_FreshnessValueLength" 0;
BA_DEF_DEF_  "GenSigStartValue" 0;
BA_DEF_DEF_  "SCL_CryptographicMessageID" 0;
BA_DEF_DEF_  "GenSigInactiveValue" 0;
BA_DEF_DEF_  "GenSigSendType" "Cyclic";
BA_DEF_DEF_  "SCP_FreshnessValueTxLength" 0;
BA_DEF_DEF_  "GenMsgCycleTimeFast" 0;
BA_DEF_DEF_  "GenMsgNrOfRepetition" 0;
BA_DEF_DEF_  "DiagConnection" 0;
BA_DEF_DEF_  "GenMsgDelayTime" 0;
BA_DEF_DEF_  "DBName" "";
BA_DEF_DEF_  "BusBaudrate" 500;
BA_DEF_DEF_  "NodeLayerModules" "CANoeILNLVector.dll";
BA_DEF_DEF_  "ILUsed" "Yes";
BA_DEF_DEF_  "DiagStationAddress" 0;
BA_DEF_DEF_  "NmNode" "No";
BA_DEF_DEF_  "NmStationAddress" 0;
BA_DEF_DEF_  "NmCAN" 0;
BA_DEF_DEF_  "NmType" "NmAsr";
BA_DEF_DEF_  "NmBaseAddress" 1024;
BA_DEF_DEF_  "NmMessageCount" 128;
BA_DEF_DEF_  "CANFD_BRS" "1";
BA_DEF_DEF_  "VFrameFormat" "StandardCAN";
BA_DEF_DEF_  "GenMsgILSupport" "Yes";
BA_DEF_DEF_  "GenMsgStartDelayTime" 0;
BA_DEF_DEF_  "BusType" "MOST";
BA_DEF_DEF_  "E2EP01DataLength" 0;
BA_DEF_DEF_  "E2EP01DataId" 0;
BA_DEF_DEF_  "sigSecLevel" "";
BA_DEF_DEF_  "sigConfig" "";
BA_DEF_DEF_  "sigExplanation" "";
BA_ "NmMessageCount" 64;
BA_ "NmAsrMessageCount" 64;
BA_ "BusType" "CAN FD";
BA_ "BusBaudrate" 2000;
BA_ "DBName" "CAN_LRR_CENTER";
BA_ "NmStationAddress" BU_ VCU 45;
BA_ "NmNode" BU_ VCU 1;
BA_ "NmCAN" BU_ VCU 1;
BA_ "NmAsrNodeIdentifier" BU_ VCU 45;
BA_ "NmAsrNode" BU_ VCU 1;
BA_ "NmAsrCanMsgReducedTime" BU_ VCU 432;
BA_ "NmAsrCanMsgCycleOffset" BU_ VCU 225;
BA_ "DiagStationAddress" BU_ VCU 174;
BA_ "NmStationAddress" BU_ FCM 46;
BA_ "NmNode" BU_ FCM 1;
BA_ "NmCAN" BU_ FCM 1;
BA_ "NmAsrNodeIdentifier" BU_ FCM 46;
BA_ "NmAsrNode" BU_ FCM 1;
BA_ "NmAsrCanMsgReducedTime" BU_ FCM 435;
BA_ "NmAsrCanMsgCycleOffset" BU_ FCM 230;
BA_ "DiagStationAddress" BU_ FCM 136;
BA_ "VFrameFormat" BO_ 274 14;
BA_ "VFrameFormat" BO_ 298 14;
BA_ "GenMsgCycleTime" BO_ 32 1000;
BA_ "GenMsgCycleTimeFast" BO_ 32 1000;
BA_ "GenMsgNrOfRepetition" BO_ 32 3;
BA_ "SC_Message" BO_ 32 1;
BA_ "SCP_FreshnessValueTxLength" BO_ 32 40;
BA_ "SCP_FreshnessValueLength" BO_ 32 40;
BA_ "SCP_DataId" BO_ 32 32;
BA_ "SCP_AuthInfoTxLength" BO_ 32 24;
BA_ "GenMsgDelayTime" BO_ 32 50;
BA_ "VFrameFormat" BO_ 32 14;
BA_ "GenMsgNrOfRepetition" BO_ 89 5;
BA_ "GenMsgDelayTime" BO_ 89 10;
BA_ "GenMsgCycleTimeFast" BO_ 89 10;
BA_ "GenMsgCycleTime" BO_ 89 50;
BA_ "E2EP01DataLength" BO_ 89 64;
BA_ "E2EP01DataId" BO_ 89 152;
BA_ "VFrameFormat" BO_ 89 14;
BA_ "GenMsgCycleTime" BO_ 275 10;
BA_ "E2EP01DataLength" BO_ 275 64;
BA_ "E2EP01DataId" BO_ 275 184;
BA_ "VFrameFormat" BO_ 275 14;
BA_ "GenMsgCycleTime" BO_ 276 20;
BA_ "E2EP01DataLength" BO_ 276 64;
BA_ "E2EP01DataId" BO_ 276 114;
BA_ "VFrameFormat" BO_ 276 14;
BA_ "GenMsgCycleTime" BO_ 277 10;
BA_ "E2EP01DataLength" BO_ 277 64;
BA_ "E2EP01DataId" BO_ 277 138;
BA_ "VFrameFormat" BO_ 277 14;
BA_ "GenMsgCycleTime" BO_ 278 10;
BA_ "E2EP01DataLength" BO_ 278 64;
BA_ "E2EP01DataId" BO_ 278 159;
BA_ "VFrameFormat" BO_ 278 14;
BA_ "GenMsgCycleTime" BO_ 281 20;
BA_ "E2EP01DataLength" BO_ 281 64;
BA_ "E2EP01DataId" BO_ 281 164;
BA_ "VFrameFormat" BO_ 281 14;
BA_ "GenMsgCycleTime" BO_ 288 10;
BA_ "E2EP01DataLength" BO_ 288 64;
BA_ "E2EP01DataId" BO_ 288 177;
BA_ "VFrameFormat" BO_ 288 14;
BA_ "GenMsgCycleTime" BO_ 293 10;
BA_ "E2EP01DataLength" BO_ 293 64;
BA_ "E2EP01DataId" BO_ 293 145;
BA_ "VFrameFormat" BO_ 293 14;
BA_ "GenMsgCycleTime" BO_ 372 100;
BA_ "E2EP01DataLength" BO_ 372 64;
BA_ "E2EP01DataId" BO_ 372 102;
BA_ "VFrameFormat" BO_ 372 14;
BA_ "GenMsgCycleTime" BO_ 373 100;
BA_ "E2EP01DataLength" BO_ 373 64;
BA_ "E2EP01DataId" BO_ 373 103;
BA_ "VFrameFormat" BO_ 373 14;
BA_ "GenMsgCycleTime" BO_ 374 100;
BA_ "E2EP01DataLength" BO_ 374 64;
BA_ "E2EP01DataId" BO_ 374 100;
BA_ "VFrameFormat" BO_ 374 14;
BA_ "GenMsgCycleTime" BO_ 375 100;
BA_ "E2EP01DataLength" BO_ 375 64;
BA_ "E2EP01DataId" BO_ 375 105;
BA_ "VFrameFormat" BO_ 375 14;
BA_ "GenMsgCycleTime" BO_ 376 100;
BA_ "E2EP01DataLength" BO_ 376 64;
BA_ "E2EP01DataId" BO_ 376 106;
BA_ "VFrameFormat" BO_ 376 14;
BA_ "GenMsgCycleTime" BO_ 377 100;
BA_ "E2EP01DataLength" BO_ 377 64;
BA_ "E2EP01DataId" BO_ 377 107;
BA_ "VFrameFormat" BO_ 377 14;
BA_ "GenMsgCycleTime" BO_ 440 20;
BA_ "E2EP01DataLength" BO_ 440 64;
BA_ "E2EP01DataId" BO_ 440 193;
BA_ "VFrameFormat" BO_ 440 14;
BA_ "GenMsgCycleTime" BO_ 450 10;
BA_ "E2EP01DataLength" BO_ 450 64;
BA_ "E2EP01DataId" BO_ 450 144;
BA_ "VFrameFormat" BO_ 450 14;
BA_ "GenMsgCycleTime" BO_ 452 10;
BA_ "E2EP01DataLength" BO_ 452 64;
BA_ "E2EP01DataId" BO_ 452 156;
BA_ "VFrameFormat" BO_ 452 14;
BA_ "SC_Message" BO_ 532 1;
BA_ "SC_LinkPos" BO_ 532 64;
BA_ "SCP_FreshnessValueTxLength" BO_ 532 8;
BA_ "SCP_FreshnessValueLength" BO_ 532 64;
BA_ "SCP_FreshnessValueId" BO_ 532 532;
BA_ "SCP_DataId" BO_ 532 532;
BA_ "SCP_AuthInfoTxLength" BO_ 532 24;
BA_ "SCL_CryptographicMessageID" BO_ 532 532;
BA_ "GenMsgCycleTime" BO_ 532 10;
BA_ "E2EP01DataLength" BO_ 532 64;
BA_ "E2EP01DataId" BO_ 532 18;
BA_ "VFrameFormat" BO_ 532 14;
BA_ "GenMsgCycleTime" BO_ 778 10;
BA_ "E2EP01DataLength" BO_ 778 64;
BA_ "E2EP01DataId" BO_ 778 116;
BA_ "VFrameFormat" BO_ 778 14;
BA_ "GenMsgCycleTime" BO_ 784 20;
BA_ "E2EP01DataLength" BO_ 784 64;
BA_ "E2EP01DataId" BO_ 784 200;
BA_ "VFrameFormat" BO_ 784 14;
BA_ "GenMsgCycleTime" BO_ 792 20;
BA_ "E2EP01DataLength" BO_ 792 64;
BA_ "E2EP01DataId" BO_ 792 121;
BA_ "VFrameFormat" BO_ 792 14;
BA_ "GenMsgCycleTime" BO_ 819 50;
BA_ "E2EP01DataLength" BO_ 819 64;
BA_ "E2EP01DataId" BO_ 819 203;
BA_ "VFrameFormat" BO_ 819 14;
BA_ "GenMsgCycleTime" BO_ 821 50;
BA_ "E2EP01DataLength" BO_ 821 64;
BA_ "E2EP01DataId" BO_ 821 212;
BA_ "VFrameFormat" BO_ 821 14;
BA_ "GenMsgCycleTime" BO_ 822 100;
BA_ "E2EP01DataLength" BO_ 822 64;
BA_ "E2EP01DataId" BO_ 822 229;
BA_ "VFrameFormat" BO_ 822 14;
BA_ "GenMsgCycleTime" BO_ 837 50;
BA_ "E2EP01DataLength" BO_ 837 64;
BA_ "E2EP01DataId" BO_ 837 217;
BA_ "VFrameFormat" BO_ 837 14;
BA_ "GenMsgCycleTime" BO_ 856 100;
BA_ "E2EP01DataLength" BO_ 856 64;
BA_ "E2EP01DataId" BO_ 856 71;
BA_ "VFrameFormat" BO_ 856 14;
BA_ "GenMsgCycleTime" BO_ 866 100;
BA_ "VFrameFormat" BO_ 866 14;
BA_ "GenMsgCycleTime" BO_ 883 100;
BA_ "VFrameFormat" BO_ 883 14;
BA_ "sigSecLevel" SG_ 32 Syn_TripCntrVal_Byte0_All "null";
BA_ "sigExplanation" SG_ 32 Syn_TripCntrVal_Byte0_All "null";
BA_ "sigConfig" SG_ 32 Syn_TripCntrVal_Byte0_All "null";
BA_ "GenSigSendType" SG_ 32 Syn_TripCntrVal_Byte0_All 2;
BA_ "sigSecLevel" SG_ 32 Syn_TripCntrVal_Byte1_All "null";
BA_ "sigExplanation" SG_ 32 Syn_TripCntrVal_Byte1_All "null";
BA_ "sigConfig" SG_ 32 Syn_TripCntrVal_Byte1_All "null";
BA_ "GenSigSendType" SG_ 32 Syn_TripCntrVal_Byte1_All 2;
BA_ "sigSecLevel" SG_ 32 Syn_RstCntrVal_Byte0_All "null";
BA_ "sigExplanation" SG_ 32 Syn_RstCntrVal_Byte0_All "null";
BA_ "sigConfig" SG_ 32 Syn_RstCntrVal_Byte0_All "null";
BA_ "GenSigSendType" SG_ 32 Syn_RstCntrVal_Byte0_All 2;
BA_ "sigSecLevel" SG_ 32 Syn_RstCntrVal_Byte1_All "null";
BA_ "sigExplanation" SG_ 32 Syn_RstCntrVal_Byte1_All "null";
BA_ "sigConfig" SG_ 32 Syn_RstCntrVal_Byte1_All "null";
BA_ "GenSigSendType" SG_ 32 Syn_RstCntrVal_Byte1_All 2;
BA_ "sigSecLevel" SG_ 32 Syn_RstCntrVal_Byte2_All "null";
BA_ "sigExplanation" SG_ 32 Syn_RstCntrVal_Byte2_All "null";
BA_ "sigConfig" SG_ 32 Syn_RstCntrVal_Byte2_All "null";
BA_ "GenSigSendType" SG_ 32 Syn_RstCntrVal_Byte2_All 2;
BA_ "sigSecLevel" SG_ 32 Syn_MACInfo_Byte0_All "null";
BA_ "sigExplanation" SG_ 32 Syn_MACInfo_Byte0_All "null";
BA_ "sigConfig" SG_ 32 Syn_MACInfo_Byte0_All "null";
BA_ "GenSigSendType" SG_ 32 Syn_MACInfo_Byte0_All 2;
BA_ "sigSecLevel" SG_ 32 Syn_MACInfo_Byte1_All "null";
BA_ "sigExplanation" SG_ 32 Syn_MACInfo_Byte1_All "null";
BA_ "sigConfig" SG_ 32 Syn_MACInfo_Byte1_All "null";
BA_ "GenSigSendType" SG_ 32 Syn_MACInfo_Byte1_All 2;
BA_ "sigSecLevel" SG_ 32 Syn_MACInfo_Byte2_All "null";
BA_ "sigExplanation" SG_ 32 Syn_MACInfo_Byte2_All "null";
BA_ "sigConfig" SG_ 32 Syn_MACInfo_Byte2_All "null";
BA_ "GenSigSendType" SG_ 32 Syn_MACInfo_Byte2_All 2;
BA_ "sigSecLevel" SG_ 89 ACU_59_CheckSum "null";
BA_ "sigExplanation" SG_ 89 ACU_59_CheckSum "null";
BA_ "sigConfig" SG_ 89 ACU_59_CheckSum "null";
BA_ "sigSecLevel" SG_ 89 ACU_59_AliveCounter "null";
BA_ "sigExplanation" SG_ 89 ACU_59_AliveCounter "null";
BA_ "sigConfig" SG_ 89 ACU_59_AliveCounter "null";
BA_ "sigSecLevel" SG_ 89 ACU_FrntCrashOutpSts "A(D)";
BA_ "sigExplanation" SG_ 89 ACU_FrntCrashOutpSts "null";
BA_ "sigConfig" SG_ 89 ACU_FrntCrashOutpSts "null";
BA_ "GenSigSendType" SG_ 89 ACU_FrntCrashOutpSts 4;
BA_ "sigSecLevel" SG_ 89 ACU_RiSideCrashOutpSts "A(D)";
BA_ "sigExplanation" SG_ 89 ACU_RiSideCrashOutpSts "null";
BA_ "sigConfig" SG_ 89 ACU_RiSideCrashOutpSts "null";
BA_ "GenSigSendType" SG_ 89 ACU_RiSideCrashOutpSts 4;
BA_ "sigSecLevel" SG_ 89 ACU_LeSideCrashOutpSts "A(D)";
BA_ "sigExplanation" SG_ 89 ACU_LeSideCrashOutpSts "null";
BA_ "sigConfig" SG_ 89 ACU_LeSideCrashOutpSts "null";
BA_ "GenSigSendType" SG_ 89 ACU_LeSideCrashOutpSts 4;
BA_ "sigSecLevel" SG_ 89 ACU_RearCrashOutpSts "A(D)";
BA_ "sigExplanation" SG_ 89 ACU_RearCrashOutpSts "null";
BA_ "sigConfig" SG_ 89 ACU_RearCrashOutpSts "null";
BA_ "GenSigSendType" SG_ 89 ACU_RearCrashOutpSts 4;
BA_ "sigSecLevel" SG_ 89 ACU_RollovrCrashOutpSts "A(D)";
BA_ "sigExplanation" SG_ 89 ACU_RollovrCrashOutpSts "null";
BA_ "sigConfig" SG_ 89 ACU_RollovrCrashOutpSts "null";
BA_ "GenSigSendType" SG_ 89 ACU_RollovrCrashOutpSts 4;
BA_ "sigSecLevel" SG_ 89 ACU_Crash_cfm "A(D)";
BA_ "sigExplanation" SG_ 89 ACU_Crash_cfm "null";
BA_ "sigConfig" SG_ 89 ACU_Crash_cfm "null";
BA_ "GenSigSendType" SG_ 89 ACU_Crash_cfm 4;
BA_ "sigSecLevel" SG_ 275 YRS_113_CheckSum "null";
BA_ "sigExplanation" SG_ 275 YRS_113_CheckSum "null";
BA_ "sigConfig" SG_ 275 YRS_113_CheckSum "null";
BA_ "sigSecLevel" SG_ 275 YRS_113_AliveCounter "null";
BA_ "sigExplanation" SG_ 275 YRS_113_AliveCounter "null";
BA_ "sigConfig" SG_ 275 YRS_113_AliveCounter "null";
BA_ "sigSecLevel" SG_ 275 YRS_LgtSnsrSts "C";
BA_ "sigExplanation" SG_ 275 YRS_LgtSnsrSts "null";
BA_ "sigConfig" SG_ 275 YRS_LgtSnsrSts "null";
BA_ "sigSecLevel" SG_ 275 YRS_LgtAcce "C";
BA_ "sigExplanation" SG_ 275 YRS_LgtAcce "null";
BA_ "sigConfig" SG_ 275 YRS_LgtAcce "null";
BA_ "GenSigStartValue" SG_ 275 YRS_LgtAcce 2000;
BA_ "sigSecLevel" SG_ 276 ESP_114_CheckSum "null";
BA_ "sigExplanation" SG_ 276 ESP_114_CheckSum "null";
BA_ "sigConfig" SG_ 276 ESP_114_CheckSum "null";
BA_ "sigSecLevel" SG_ 276 ESP_114_AliveCounter "null";
BA_ "sigExplanation" SG_ 276 ESP_114_AliveCounter "null";
BA_ "sigConfig" SG_ 276 ESP_114_AliveCounter "null";
BA_ "sigSecLevel" SG_ 276 ESP_FltIndcn_DTC "A";
BA_ "sigExplanation" SG_ 276 ESP_FltIndcn_DTC "null";
BA_ "sigConfig" SG_ 276 ESP_FltIndcn_DTC "null";
BA_ "sigSecLevel" SG_ 276 ESP_ActvSig_VDC "B";
BA_ "sigExplanation" SG_ 276 ESP_ActvSig_VDC "null";
BA_ "sigConfig" SG_ 276 ESP_ActvSig_VDC "null";
BA_ "sigSecLevel" SG_ 276 ESP_ActvSig_TCS "B";
BA_ "sigExplanation" SG_ 276 ESP_ActvSig_TCS "null";
BA_ "sigConfig" SG_ 276 ESP_ActvSig_TCS "null";
BA_ "sigSecLevel" SG_ 276 ESP_ActvSig_EBD "B";
BA_ "sigExplanation" SG_ 276 ESP_ActvSig_EBD "null";
BA_ "sigConfig" SG_ 276 ESP_ActvSig_EBD "null";
BA_ "sigSecLevel" SG_ 276 ESP_ActvSig_DTC "B";
BA_ "sigExplanation" SG_ 276 ESP_ActvSig_DTC "null";
BA_ "sigConfig" SG_ 276 ESP_ActvSig_DTC "null";
BA_ "sigSecLevel" SG_ 276 ESP_WarningOn "B";
BA_ "sigExplanation" SG_ 276 ESP_WarningOn "null";
BA_ "sigConfig" SG_ 276 ESP_WarningOn "null";
BA_ "sigSecLevel" SG_ 276 ESP_Actvndcn_CDD "null";
BA_ "sigExplanation" SG_ 276 ESP_Actvndcn_CDD "null";
BA_ "sigConfig" SG_ 276 ESP_Actvndcn_CDD "null";
BA_ "sigSecLevel" SG_ 276 ESP_FltIndcn_CDD "null";
BA_ "sigExplanation" SG_ 276 ESP_FltIndcn_CDD "null";
BA_ "sigConfig" SG_ 276 ESP_FltIndcn_CDD "null";
BA_ "sigSecLevel" SG_ 276 ESP_ActvIndcn_ABA "A";
BA_ "sigExplanation" SG_ 276 ESP_ActvIndcn_ABA "null";
BA_ "sigConfig" SG_ 276 ESP_ActvIndcn_ABA "null";
BA_ "sigSecLevel" SG_ 276 ESP_FltIndcn_ABA "A";
BA_ "sigExplanation" SG_ 276 ESP_FltIndcn_ABA "null";
BA_ "sigConfig" SG_ 276 ESP_FltIndcn_ABA "null";
BA_ "sigSecLevel" SG_ 276 ESP_ActvIndcn_ABP "A";
BA_ "sigExplanation" SG_ 276 ESP_ActvIndcn_ABP "null";
BA_ "sigConfig" SG_ 276 ESP_ActvIndcn_ABP "null";
BA_ "sigSecLevel" SG_ 276 ESP_FltIndcn_ABP "A";
BA_ "sigExplanation" SG_ 276 ESP_FltIndcn_ABP "null";
BA_ "sigConfig" SG_ 276 ESP_FltIndcn_ABP "null";
BA_ "sigSecLevel" SG_ 276 ESP_ActvIndcn_AEB "A";
BA_ "sigExplanation" SG_ 276 ESP_ActvIndcn_AEB "null";
BA_ "sigConfig" SG_ 276 ESP_ActvIndcn_AEB "null";
BA_ "sigSecLevel" SG_ 276 ESP_FltIndcn_AEB "A";
BA_ "sigExplanation" SG_ 276 ESP_FltIndcn_AEB "null";
BA_ "sigConfig" SG_ 276 ESP_FltIndcn_AEB "null";
BA_ "sigSecLevel" SG_ 276 ESP_ActvIndcn_AWB "C";
BA_ "sigExplanation" SG_ 276 ESP_ActvIndcn_AWB "null";
BA_ "sigConfig" SG_ 276 ESP_ActvIndcn_AWB "null";
BA_ "sigSecLevel" SG_ 276 ESP_FltIndcn_AWB "C";
BA_ "sigExplanation" SG_ 276 ESP_FltIndcn_AWB "null";
BA_ "sigConfig" SG_ 276 ESP_FltIndcn_AWB "null";
BA_ "sigSecLevel" SG_ 276 ESP_VehStandstillIndcn "null";
BA_ "sigExplanation" SG_ 276 ESP_VehStandstillIndcn "null";
BA_ "sigConfig" SG_ 276 ESP_VehStandstillIndcn "null";
BA_ "sigSecLevel" SG_ 276 ESP_BrkOverTIndcn "C";
BA_ "sigExplanation" SG_ 276 ESP_BrkOverTIndcn "null";
BA_ "sigConfig" SG_ 276 ESP_BrkOverTIndcn "null";
BA_ "sigSecLevel" SG_ 276 ESP_FltIndcn_VDC "B";
BA_ "sigExplanation" SG_ 276 ESP_FltIndcn_VDC "null";
BA_ "sigConfig" SG_ 276 ESP_FltIndcn_VDC "null";
BA_ "sigSecLevel" SG_ 276 ESP_ActvIndcn_CDD_AP "null";
BA_ "sigExplanation" SG_ 276 ESP_ActvIndcn_CDD_AP "null";
BA_ "sigConfig" SG_ 276 ESP_ActvIndcn_CDD_AP "null";
BA_ "sigSecLevel" SG_ 276 ESP_FltIndcn_CDD_AP "null";
BA_ "sigExplanation" SG_ 276 ESP_FltIndcn_CDD_AP "null";
BA_ "sigConfig" SG_ 276 ESP_FltIndcn_CDD_AP "null";
BA_ "sigSecLevel" SG_ 277 ESP_115_CheckSum "null";
BA_ "sigExplanation" SG_ 277 ESP_115_CheckSum "null";
BA_ "sigConfig" SG_ 277 ESP_115_CheckSum "null";
BA_ "sigSecLevel" SG_ 277 ESP_115_AliveCounter "null";
BA_ "sigExplanation" SG_ 277 ESP_115_AliveCounter "null";
BA_ "sigConfig" SG_ 277 ESP_115_AliveCounter "null";
BA_ "sigSecLevel" SG_ 277 ESP_WhlSpd_RF "B";
BA_ "sigExplanation" SG_ 277 ESP_WhlSpd_RF "null";
BA_ "sigConfig" SG_ 277 ESP_WhlSpd_RF "null";
BA_ "sigSecLevel" SG_ 277 ESP_WhlSpdVld_RF "B";
BA_ "sigExplanation" SG_ 277 ESP_WhlSpdVld_RF "null";
BA_ "sigConfig" SG_ 277 ESP_WhlSpdVld_RF "null";
BA_ "sigSecLevel" SG_ 277 ESP_WhlMovgDir_RF "A";
BA_ "sigExplanation" SG_ 277 ESP_WhlMovgDir_RF "null";
BA_ "sigConfig" SG_ 277 ESP_WhlMovgDir_RF "null";
BA_ "sigSecLevel" SG_ 277 ESP_WhlMovgDir_LF "A";
BA_ "sigExplanation" SG_ 277 ESP_WhlMovgDir_LF "null";
BA_ "sigConfig" SG_ 277 ESP_WhlMovgDir_LF "null";
BA_ "sigSecLevel" SG_ 277 ESP_WhlSpd_LF "B";
BA_ "sigExplanation" SG_ 277 ESP_WhlSpd_LF "null";
BA_ "sigConfig" SG_ 277 ESP_WhlSpd_LF "null";
BA_ "sigSecLevel" SG_ 277 ESP_WhlSpdVld_LF "B";
BA_ "sigExplanation" SG_ 277 ESP_WhlSpdVld_LF "null";
BA_ "sigConfig" SG_ 277 ESP_WhlSpdVld_LF "null";
BA_ "sigSecLevel" SG_ 278 ESP_116_CheckSum "null";
BA_ "sigExplanation" SG_ 278 ESP_116_CheckSum "null";
BA_ "sigConfig" SG_ 278 ESP_116_CheckSum "null";
BA_ "sigSecLevel" SG_ 278 ESP_116_AliveCounter "null";
BA_ "sigExplanation" SG_ 278 ESP_116_AliveCounter "null";
BA_ "sigConfig" SG_ 278 ESP_116_AliveCounter "null";
BA_ "sigSecLevel" SG_ 278 ESP_WhlSpd_RR "B";
BA_ "sigExplanation" SG_ 278 ESP_WhlSpd_RR "null";
BA_ "sigConfig" SG_ 278 ESP_WhlSpd_RR "null";
BA_ "sigSecLevel" SG_ 278 ESP_WhlSpdVld_RR "B";
BA_ "sigExplanation" SG_ 278 ESP_WhlSpdVld_RR "null";
BA_ "sigConfig" SG_ 278 ESP_WhlSpdVld_RR "null";
BA_ "sigSecLevel" SG_ 278 ESP_WhlMovgDir_RR "A";
BA_ "sigExplanation" SG_ 278 ESP_WhlMovgDir_RR "null";
BA_ "sigConfig" SG_ 278 ESP_WhlMovgDir_RR "null";
BA_ "sigSecLevel" SG_ 278 ESP_WhlMovgDir_RL "A";
BA_ "sigExplanation" SG_ 278 ESP_WhlMovgDir_RL "null";
BA_ "sigConfig" SG_ 278 ESP_WhlMovgDir_RL "null";
BA_ "sigSecLevel" SG_ 278 ESP_WhlSpd_RL "B";
BA_ "sigExplanation" SG_ 278 ESP_WhlSpd_RL "null";
BA_ "sigConfig" SG_ 278 ESP_WhlSpd_RL "null";
BA_ "sigSecLevel" SG_ 278 ESP_WhlSpdVld_RL "B";
BA_ "sigExplanation" SG_ 278 ESP_WhlSpdVld_RL "null";
BA_ "sigConfig" SG_ 278 ESP_WhlSpdVld_RL "null";
BA_ "sigSecLevel" SG_ 281 iBooster_119_CheckSum "null";
BA_ "sigExplanation" SG_ 281 iBooster_119_CheckSum "null";
BA_ "sigConfig" SG_ 281 iBooster_119_CheckSum "null";
BA_ "sigSecLevel" SG_ 281 iBooster_119_AliveCounter "null";
BA_ "sigExplanation" SG_ 281 iBooster_119_AliveCounter "null";
BA_ "sigConfig" SG_ 281 iBooster_119_AliveCounter "null";
BA_ "sigSecLevel" SG_ 281 iBooster_WarnOn "null";
BA_ "sigExplanation" SG_ 281 iBooster_WarnOn "null";
BA_ "sigConfig" SG_ 281 iBooster_WarnOn "null";
BA_ "sigSecLevel" SG_ 281 iBooster_BrkPedlAppldFlg "A";
BA_ "sigExplanation" SG_ 281 iBooster_BrkPedlAppldFlg "null";
BA_ "sigConfig" SG_ 281 iBooster_BrkPedlAppldFlg "null";
BA_ "sigSecLevel" SG_ 281 iBooster_BrkPedlAppldVld "A";
BA_ "sigExplanation" SG_ 281 iBooster_BrkPedlAppldVld "null";
BA_ "sigConfig" SG_ 281 iBooster_BrkPedlAppldVld "null";
BA_ "sigSecLevel" SG_ 288 ESP_120_CheckSum "null";
BA_ "sigExplanation" SG_ 288 ESP_120_CheckSum "null";
BA_ "sigConfig" SG_ 288 ESP_120_CheckSum "null";
BA_ "sigSecLevel" SG_ 288 ESP_120_AliveCounter "null";
BA_ "sigExplanation" SG_ 288 ESP_120_AliveCounter "null";
BA_ "sigConfig" SG_ 288 ESP_120_AliveCounter "null";
BA_ "sigSecLevel" SG_ 288 ESP_ActvSig_ABS "C";
BA_ "sigExplanation" SG_ 288 ESP_ActvSig_ABS "null";
BA_ "sigConfig" SG_ 288 ESP_ActvSig_ABS "null";
BA_ "sigSecLevel" SG_ 288 ESP_MstCylP "B";
BA_ "sigExplanation" SG_ 288 ESP_MstCylP "null";
BA_ "sigConfig" SG_ 288 ESP_MstCylP "null";
BA_ "GenSigStartValue" SG_ 288 ESP_MstCylP 300;
BA_ "sigSecLevel" SG_ 288 ESP_MstCylPOffs "null";
BA_ "sigExplanation" SG_ 288 ESP_MstCylPOffs "null";
BA_ "sigConfig" SG_ 288 ESP_MstCylPOffs "null";
BA_ "sigSecLevel" SG_ 288 ESP_MstCylPVld "B";
BA_ "sigExplanation" SG_ 288 ESP_MstCylPVld "null";
BA_ "sigConfig" SG_ 288 ESP_MstCylPVld "null";
BA_ "sigSecLevel" SG_ 288 ESP_MstCylPOffsVld "null";
BA_ "sigExplanation" SG_ 288 ESP_MstCylPOffsVld "null";
BA_ "sigConfig" SG_ 288 ESP_MstCylPOffsVld "null";
BA_ "sigSecLevel" SG_ 288 ESP_TotBrkTqReq "C";
BA_ "sigExplanation" SG_ 288 ESP_TotBrkTqReq "null";
BA_ "sigConfig" SG_ 288 ESP_TotBrkTqReq "null";
BA_ "GenSigStartValue" SG_ 288 ESP_TotBrkTqReq 30000;
BA_ "sigSecLevel" SG_ 293 ESP_125_CheckSum "null";
BA_ "sigExplanation" SG_ 293 ESP_125_CheckSum "null";
BA_ "sigConfig" SG_ 293 ESP_125_CheckSum "null";
BA_ "sigSecLevel" SG_ 293 ESP_125_AliveCounter "null";
BA_ "sigExplanation" SG_ 293 ESP_125_AliveCounter "null";
BA_ "sigConfig" SG_ 293 ESP_125_AliveCounter "null";
BA_ "sigSecLevel" SG_ 293 ESP_WhlOdoEdges_FL "null";
BA_ "sigExplanation" SG_ 293 ESP_WhlOdoEdges_FL "null";
BA_ "sigConfig" SG_ 293 ESP_WhlOdoEdges_FL "null";
BA_ "sigSecLevel" SG_ 293 ESP_WhlOdoEdges_FR "null";
BA_ "sigExplanation" SG_ 293 ESP_WhlOdoEdges_FR "null";
BA_ "sigConfig" SG_ 293 ESP_WhlOdoEdges_FR "null";
BA_ "sigSecLevel" SG_ 293 ESP_WhlOdoEdges_RL "null";
BA_ "sigExplanation" SG_ 293 ESP_WhlOdoEdges_RL "null";
BA_ "sigConfig" SG_ 293 ESP_WhlOdoEdges_RL "null";
BA_ "sigSecLevel" SG_ 293 ESP_WhlOdoEdges_RR "null";
BA_ "sigExplanation" SG_ 293 ESP_WhlOdoEdges_RR "null";
BA_ "sigConfig" SG_ 293 ESP_WhlOdoEdges_RR "null";
BA_ "sigSecLevel" SG_ 293 ESP_WhlOdoEdgesVld_FL "A";
BA_ "sigExplanation" SG_ 293 ESP_WhlOdoEdgesVld_FL "null";
BA_ "sigConfig" SG_ 293 ESP_WhlOdoEdgesVld_FL "null";
BA_ "sigSecLevel" SG_ 293 ESP_WhlOdoEdgesVld_FR "A";
BA_ "sigExplanation" SG_ 293 ESP_WhlOdoEdgesVld_FR "null";
BA_ "sigConfig" SG_ 293 ESP_WhlOdoEdgesVld_FR "null";
BA_ "sigSecLevel" SG_ 293 ESP_WhlOdoEdgesVld_RL "A";
BA_ "sigExplanation" SG_ 293 ESP_WhlOdoEdgesVld_RL "null";
BA_ "sigConfig" SG_ 293 ESP_WhlOdoEdgesVld_RL "null";
BA_ "sigSecLevel" SG_ 293 ESP_WhlOdoEdgesVld_RR "A";
BA_ "sigExplanation" SG_ 293 ESP_WhlOdoEdgesVld_RR "null";
BA_ "sigConfig" SG_ 293 ESP_WhlOdoEdgesVld_RR "null";
BA_ "sigSecLevel" SG_ 372 TBOX_XAcce "null";
BA_ "sigExplanation" SG_ 372 TBOX_XAcce "null";
BA_ "sigConfig" SG_ 372 TBOX_XAcce "null";
BA_ "sigSecLevel" SG_ 372 TBOX_XVelocity "null";
BA_ "sigExplanation" SG_ 372 TBOX_XVelocity "null";
BA_ "sigConfig" SG_ 372 TBOX_XVelocity "null";
BA_ "sigSecLevel" SG_ 372 TBOX_XAgrRate "null";
BA_ "sigExplanation" SG_ 372 TBOX_XAgrRate "null";
BA_ "sigConfig" SG_ 372 TBOX_XAgrRate "null";
BA_ "sigSecLevel" SG_ 373 TBOX_YAcce "null";
BA_ "sigExplanation" SG_ 373 TBOX_YAcce "null";
BA_ "sigConfig" SG_ 373 TBOX_YAcce "null";
BA_ "sigSecLevel" SG_ 373 TBOX_YVelocity "null";
BA_ "sigExplanation" SG_ 373 TBOX_YVelocity "null";
BA_ "sigConfig" SG_ 373 TBOX_YVelocity "null";
BA_ "sigSecLevel" SG_ 373 TBOX_YAgrRate "null";
BA_ "sigExplanation" SG_ 373 TBOX_YAgrRate "null";
BA_ "sigConfig" SG_ 373 TBOX_YAgrRate "null";
BA_ "sigSecLevel" SG_ 374 TBOX_ZAcce "null";
BA_ "sigExplanation" SG_ 374 TBOX_ZAcce "null";
BA_ "sigConfig" SG_ 374 TBOX_ZAcce "null";
BA_ "sigSecLevel" SG_ 374 TBOX_ZVelocity "null";
BA_ "sigExplanation" SG_ 374 TBOX_ZVelocity "null";
BA_ "sigConfig" SG_ 374 TBOX_ZVelocity "null";
BA_ "sigSecLevel" SG_ 374 TBOX_ZAgrRate "null";
BA_ "sigExplanation" SG_ 374 TBOX_ZAgrRate "null";
BA_ "sigConfig" SG_ 374 TBOX_ZAgrRate "null";
BA_ "sigSecLevel" SG_ 375 TBOX_DftlAge "null";
BA_ "sigExplanation" SG_ 375 TBOX_DftlAge "null";
BA_ "sigConfig" SG_ 375 TBOX_DftlAge "null";
BA_ "sigSecLevel" SG_ 375 TBOX_PitchStdDev "null";
BA_ "sigExplanation" SG_ 375 TBOX_PitchStdDev "null";
BA_ "sigConfig" SG_ 375 TBOX_PitchStdDev "null";
BA_ "sigSecLevel" SG_ 376 TBOX_Roll "null";
BA_ "sigExplanation" SG_ 376 TBOX_Roll "null";
BA_ "sigConfig" SG_ 376 TBOX_Roll "null";
BA_ "sigSecLevel" SG_ 376 TBOX_RollStdDev "null";
BA_ "sigExplanation" SG_ 376 TBOX_RollStdDev "null";
BA_ "sigConfig" SG_ 376 TBOX_RollStdDev "null";
BA_ "sigSecLevel" SG_ 377 TBOX_Heading "null";
BA_ "sigExplanation" SG_ 377 TBOX_Heading "null";
BA_ "sigConfig" SG_ 377 TBOX_Heading "null";
BA_ "sigSecLevel" SG_ 377 TBOX_HeadingStdDev "null";
BA_ "sigExplanation" SG_ 377 TBOX_HeadingStdDev "null";
BA_ "sigConfig" SG_ 377 TBOX_HeadingStdDev "null";
BA_ "sigSecLevel" SG_ 440 ESP_1B8_CheckSum "null";
BA_ "sigExplanation" SG_ 440 ESP_1B8_CheckSum "null";
BA_ "sigConfig" SG_ 440 ESP_1B8_CheckSum "null";
BA_ "sigSecLevel" SG_ 440 ESP_1B8_AliveCounter "null";
BA_ "sigExplanation" SG_ 440 ESP_1B8_AliveCounter "null";
BA_ "sigConfig" SG_ 440 ESP_1B8_AliveCounter "null";
BA_ "sigSecLevel" SG_ 440 ESP_ModFbSig "null";
BA_ "sigExplanation" SG_ 440 ESP_ModFbSig "null";
BA_ "sigConfig" SG_ 440 ESP_ModFbSig "null";
BA_ "sigSecLevel" SG_ 440 ESP_ModSwtAllw "null";
BA_ "sigExplanation" SG_ 440 ESP_ModSwtAllw "null";
BA_ "sigConfig" SG_ 440 ESP_ModSwtAllw "null";
BA_ "sigSecLevel" SG_ 440 ESP_ActvVehHldFlg "null";
BA_ "sigExplanation" SG_ 440 ESP_ActvVehHldFlg "null";
BA_ "sigConfig" SG_ 440 ESP_ActvVehHldFlg "null";
BA_ "sigSecLevel" SG_ 440 ESP_VehSecuCdn "null";
BA_ "sigExplanation" SG_ 440 ESP_VehSecuCdn "null";
BA_ "sigConfig" SG_ 440 ESP_VehSecuCdn "null";
BA_ "sigSecLevel" SG_ 440 ESP_BrkFStsFlg "null";
BA_ "sigExplanation" SG_ 440 ESP_BrkFStsFlg "null";
BA_ "sigConfig" SG_ 440 ESP_BrkFStsFlg "null";
BA_ "sigSecLevel" SG_ 440 ESP_CddApOpsDirMovmt "null";
BA_ "sigExplanation" SG_ 440 ESP_CddApOpsDirMovmt "null";
BA_ "sigConfig" SG_ 440 ESP_CddApOpsDirMovmt "null";
BA_ "sigSecLevel" SG_ 440 ESP_VehStopSts "B";
BA_ "sigExplanation" SG_ 440 ESP_VehStopSts "null";
BA_ "sigConfig" SG_ 440 ESP_VehStopSts "null";
BA_ "sigSecLevel" SG_ 440 ESP_VehStandstillSts "B";
BA_ "sigExplanation" SG_ 440 ESP_VehStandstillSts "null";
BA_ "sigConfig" SG_ 440 ESP_VehStandstillSts "null";
BA_ "sigSecLevel" SG_ 440 ESP_RoadSlopVld "null";
BA_ "sigExplanation" SG_ 440 ESP_RoadSlopVld "null";
BA_ "sigConfig" SG_ 440 ESP_RoadSlopVld "null";
BA_ "sigSecLevel" SG_ 440 ESP_AEBRdy "null";
BA_ "sigExplanation" SG_ 440 ESP_AEBRdy "null";
BA_ "sigConfig" SG_ 440 ESP_AEBRdy "null";
BA_ "sigSecLevel" SG_ 440 ESPACCRdy "null";
BA_ "sigExplanation" SG_ 440 ESPACCRdy "null";
BA_ "sigConfig" SG_ 440 ESPACCRdy "null";
BA_ "sigSecLevel" SG_ 440 ESP_ParkRdy "null";
BA_ "sigExplanation" SG_ 440 ESP_ParkRdy "null";
BA_ "sigConfig" SG_ 440 ESP_ParkRdy "null";
BA_ "sigSecLevel" SG_ 440 ESP_ReAEBRdy "null";
BA_ "sigExplanation" SG_ 440 ESP_ReAEBRdy "null";
BA_ "sigConfig" SG_ 440 ESP_ReAEBRdy "null";
BA_ "sigSecLevel" SG_ 440 ESP_RoadSlop "null";
BA_ "sigExplanation" SG_ 440 ESP_RoadSlop "null";
BA_ "sigConfig" SG_ 440 ESP_RoadSlop "null";
BA_ "GenSigStartValue" SG_ 440 ESP_RoadSlop 1000;
BA_ "sigSecLevel" SG_ 440 ESP_SpclTerrainModFltIndcn "null";
BA_ "sigExplanation" SG_ 440 ESP_SpclTerrainModFltIndcn "null";
BA_ "sigConfig" SG_ 440 ESP_SpclTerrainModFltIndcn "null";
BA_ "sigSecLevel" SG_ 440 ESP_DrvOffStRdy "null";
BA_ "sigExplanation" SG_ 440 ESP_DrvOffStRdy "null";
BA_ "sigConfig" SG_ 440 ESP_DrvOffStRdy "null";
BA_ "sigSecLevel" SG_ 440 ESP_TarLSMSts "null";
BA_ "sigExplanation" SG_ 440 ESP_TarLSMSts "null";
BA_ "sigConfig" SG_ 440 ESP_TarLSMSts "null";
BA_ "sigSecLevel" SG_ 450 EPS_1C2_CheckSum "null";
BA_ "sigExplanation" SG_ 450 EPS_1C2_CheckSum "null";
BA_ "sigConfig" SG_ 450 EPS_1C2_CheckSum "null";
BA_ "sigSecLevel" SG_ 450 EPS_1C2_AliveCounter "null";
BA_ "sigExplanation" SG_ 450 EPS_1C2_AliveCounter "null";
BA_ "sigConfig" SG_ 450 EPS_1C2_AliveCounter "null";
BA_ "sigSecLevel" SG_ 450 EPS_AbortFb "null";
BA_ "sigExplanation" SG_ 450 EPS_AbortFb "null";
BA_ "sigConfig" SG_ 450 EPS_AbortFb "null";
BA_ "sigSecLevel" SG_ 450 EPS_SteerWhlAgSig "B";
BA_ "sigExplanation" SG_ 450 EPS_SteerWhlAgSig "null";
BA_ "sigConfig" SG_ 450 EPS_SteerWhlAgSig "null";
BA_ "GenSigStartValue" SG_ 450 EPS_SteerWhlAgSig 12480;
BA_ "sigSecLevel" SG_ 450 EPS_SteerAgSnsrCalSts "null";
BA_ "sigExplanation" SG_ 450 EPS_SteerAgSnsrCalSts "null";
BA_ "sigConfig" SG_ 450 EPS_SteerAgSnsrCalSts "null";
BA_ "sigSecLevel" SG_ 450 EPS_SteerWhlAgSigVld "B";
BA_ "sigExplanation" SG_ 450 EPS_SteerWhlAgSigVld "null";
BA_ "sigConfig" SG_ 450 EPS_SteerWhlAgSigVld "null";
BA_ "sigSecLevel" SG_ 450 EPS_SteerWhlRotSpdDir "B";
BA_ "sigExplanation" SG_ 450 EPS_SteerWhlRotSpdDir "null";
BA_ "sigConfig" SG_ 450 EPS_SteerWhlRotSpdDir "null";
BA_ "GenSigStartValue" SG_ 450 EPS_SteerWhlRotSpdDir 2;
BA_ "sigSecLevel" SG_ 450 EPS_SteerWhlRotSpdVld "B";
BA_ "sigExplanation" SG_ 450 EPS_SteerWhlRotSpdVld "null";
BA_ "sigConfig" SG_ 450 EPS_SteerWhlRotSpdVld "null";
BA_ "sigSecLevel" SG_ 450 EPS_SteerWhlRotSpd "B";
BA_ "sigExplanation" SG_ 450 EPS_SteerWhlRotSpd "null";
BA_ "sigConfig" SG_ 450 EPS_SteerWhlRotSpd "null";
BA_ "GenSigStartValue" SG_ 450 EPS_SteerWhlRotSpd 2032;
BA_ "sigSecLevel" SG_ 450 EPS_AdasLatCtrlSts "null";
BA_ "sigExplanation" SG_ 450 EPS_AdasLatCtrlSts "null";
BA_ "sigConfig" SG_ 450 EPS_AdasLatCtrlSts "null";
BA_ "sigSecLevel" SG_ 450 EPS_AdasLatCtrlStsVld "A";
BA_ "sigExplanation" SG_ 450 EPS_AdasLatCtrlStsVld "null";
BA_ "sigConfig" SG_ 450 EPS_AdasLatCtrlStsVld "null";
BA_ "sigSecLevel" SG_ 450 EPS_AsscMotCrtTq "null";
BA_ "sigExplanation" SG_ 450 EPS_AsscMotCrtTq "null";
BA_ "sigConfig" SG_ 450 EPS_AsscMotCrtTq "null";
BA_ "sigSecLevel" SG_ 452 EPS_1C4_CheckSum "null";
BA_ "sigExplanation" SG_ 452 EPS_1C4_CheckSum "null";
BA_ "sigConfig" SG_ 452 EPS_1C4_CheckSum "null";
BA_ "sigSecLevel" SG_ 452 EPS_1C4_AliveCounter "null";
BA_ "sigExplanation" SG_ 452 EPS_1C4_AliveCounter "null";
BA_ "sigConfig" SG_ 452 EPS_1C4_AliveCounter "null";
BA_ "sigSecLevel" SG_ 452 EPS_DrvrSteerTqDir "null";
BA_ "sigExplanation" SG_ 452 EPS_DrvrSteerTqDir "null";
BA_ "sigConfig" SG_ 452 EPS_DrvrSteerTqDir "null";
BA_ "sigSecLevel" SG_ 452 EPS_DrvrSteerTqVld "null";
BA_ "sigExplanation" SG_ 452 EPS_DrvrSteerTqVld "null";
BA_ "sigConfig" SG_ 452 EPS_DrvrSteerTqVld "null";
BA_ "sigSecLevel" SG_ 452 EPS_DrvrSteerTq "null";
BA_ "sigExplanation" SG_ 452 EPS_DrvrSteerTq "null";
BA_ "sigConfig" SG_ 452 EPS_DrvrSteerTq "null";
BA_ "sigSecLevel" SG_ 452 EPS_DrvrIntvSteerWhlDetd "null";
BA_ "sigExplanation" SG_ 452 EPS_DrvrIntvSteerWhlDetd "null";
BA_ "sigConfig" SG_ 452 EPS_DrvrIntvSteerWhlDetd "null";
BA_ "sigSecLevel" SG_ 452 EPS_DrvrIntvSteerWhlVld "null";
BA_ "sigExplanation" SG_ 452 EPS_DrvrIntvSteerWhlVld "null";
BA_ "sigConfig" SG_ 452 EPS_DrvrIntvSteerWhlVld "null";
BA_ "sigSecLevel" SG_ 452 EPS_SteerSnsrSts "null";
BA_ "sigExplanation" SG_ 452 EPS_SteerSnsrSts "null";
BA_ "sigConfig" SG_ 452 EPS_SteerSnsrSts "null";
BA_ "sigSecLevel" SG_ 452 EPS_PinionAg "null";
BA_ "sigExplanation" SG_ 452 EPS_PinionAg "null";
BA_ "sigConfig" SG_ 452 EPS_PinionAg "null";
BA_ "GenSigStartValue" SG_ 452 EPS_PinionAg 12480;
BA_ "sigSecLevel" SG_ 532 VCU_214_234_CheckSum "null";
BA_ "sigExplanation" SG_ 532 VCU_214_234_CheckSum "null";
BA_ "sigConfig" SG_ 532 VCU_214_234_CheckSum "null";
BA_ "sigSecLevel" SG_ 532 VCU_214_234_AliveCounter "null";
BA_ "sigExplanation" SG_ 532 VCU_214_234_AliveCounter "null";
BA_ "sigConfig" SG_ 532 VCU_214_234_AliveCounter "null";
BA_ "sigSecLevel" SG_ 532 VCU_RdyLamp "null";
BA_ "sigExplanation" SG_ 532 VCU_RdyLamp "null";
BA_ "sigConfig" SG_ 532 VCU_RdyLamp "null";
BA_ "sigSecLevel" SG_ 532 VCU_BrkLampCtrlSts "null";
BA_ "sigExplanation" SG_ 532 VCU_BrkLampCtrlSts "null";
BA_ "sigConfig" SG_ 532 VCU_BrkLampCtrlSts "null";
BA_ "sigSecLevel" SG_ 532 VCU_RemWakeUpEndFlg "null";
BA_ "sigExplanation" SG_ 532 VCU_RemWakeUpEndFlg "null";
BA_ "sigConfig" SG_ 532 VCU_RemWakeUpEndFlg "null";
BA_ "sigSecLevel" SG_ 532 VCU_StgyGearSig "B";
BA_ "sigExplanation" SG_ 532 VCU_StgyGearSig "null";
BA_ "sigConfig" SG_ 532 VCU_StgyGearSig "null";
BA_ "sigSecLevel" SG_ 532 VCU_ShiftMisoper "null";
BA_ "sigExplanation" SG_ 532 VCU_ShiftMisoper "null";
BA_ "sigConfig" SG_ 532 VCU_ShiftMisoper "null";
BA_ "sigSecLevel" SG_ 532 VCU_GearSigVld "C";
BA_ "sigExplanation" SG_ 532 VCU_GearSigVld "null";
BA_ "sigConfig" SG_ 532 VCU_GearSigVld "null";
BA_ "sigSecLevel" SG_ 532 VCU_GearSig "C";
BA_ "sigExplanation" SG_ 532 VCU_GearSig "null";
BA_ "sigConfig" SG_ 532 VCU_GearSig "null";
BA_ "sigSecLevel" SG_ 532 VCU_ACCRdy "null";
BA_ "sigExplanation" SG_ 532 VCU_ACCRdy "null";
BA_ "sigConfig" SG_ 532 VCU_ACCRdy "null";
BA_ "sigSecLevel" SG_ 532 VCU_ParkRdy "null";
BA_ "sigExplanation" SG_ 532 VCU_ParkRdy "null";
BA_ "sigConfig" SG_ 532 VCU_ParkRdy "null";
BA_ "sigSecLevel" SG_ 532 VCU_APSPercVld "B";
BA_ "sigExplanation" SG_ 532 VCU_APSPercVld "null";
BA_ "sigConfig" SG_ 532 VCU_APSPercVld "null";
BA_ "sigSecLevel" SG_ 532 VCU_VehSt "B";
BA_ "sigExplanation" SG_ 532 VCU_VehSt "null";
BA_ "sigConfig" SG_ 532 VCU_VehSt "null";
BA_ "sigSecLevel" SG_ 532 VCU_APSPerc "B";
BA_ "sigExplanation" SG_ 532 VCU_APSPerc "null";
BA_ "sigConfig" SG_ 532 VCU_APSPerc "null";
BA_ "sigSecLevel" SG_ 532 VCU_BrkSig "null";
BA_ "sigExplanation" SG_ 532 VCU_BrkSig "null";
BA_ "sigConfig" SG_ 532 VCU_BrkSig "null";
BA_ "sigSecLevel" SG_ 532 VCU_BrkSigVld "null";
BA_ "sigExplanation" SG_ 532 VCU_BrkSigVld "null";
BA_ "sigConfig" SG_ 532 VCU_BrkSigVld "null";
BA_ "sigSecLevel" SG_ 532 VCU_DrvModSigFb "null";
BA_ "sigExplanation" SG_ 532 VCU_DrvModSigFb "null";
BA_ "sigConfig" SG_ 532 VCU_DrvModSigFb "null";
BA_ "sigSecLevel" SG_ 532 VCU_DrvModShiftMisoper "null";
BA_ "sigExplanation" SG_ 532 VCU_DrvModShiftMisoper "null";
BA_ "sigConfig" SG_ 532 VCU_DrvModShiftMisoper "null";
BA_ "sigSecLevel" SG_ 532 VCU_SpclTerrainModEnaSig "null";
BA_ "sigExplanation" SG_ 532 VCU_SpclTerrainModEnaSig "null";
BA_ "sigConfig" SG_ 532 VCU_SpclTerrainModEnaSig "null";
BA_ "sigSecLevel" SG_ 532 VCU_214_SSecOC_Fresh_Byte0 "null";
BA_ "sigExplanation" SG_ 532 VCU_214_SSecOC_Fresh_Byte0 "null";
BA_ "sigConfig" SG_ 532 VCU_214_SSecOC_Fresh_Byte0 "null";
BA_ "sigSecLevel" SG_ 532 VCU_214_SSecOC_MAC_Byte0 "null";
BA_ "sigExplanation" SG_ 532 VCU_214_SSecOC_MAC_Byte0 "null";
BA_ "sigConfig" SG_ 532 VCU_214_SSecOC_MAC_Byte0 "null";
BA_ "sigSecLevel" SG_ 532 VCU_214_SSecOC_MAC_Byte1 "null";
BA_ "sigExplanation" SG_ 532 VCU_214_SSecOC_MAC_Byte1 "null";
BA_ "sigConfig" SG_ 532 VCU_214_SSecOC_MAC_Byte1 "null";
BA_ "sigSecLevel" SG_ 532 VCU_214_SSecOC_MAC_Byte2 "null";
BA_ "sigExplanation" SG_ 532 VCU_214_SSecOC_MAC_Byte2 "null";
BA_ "sigConfig" SG_ 532 VCU_214_SSecOC_MAC_Byte2 "null";
BA_ "sigSecLevel" SG_ 778 ESP_30A_CheckSum "null";
BA_ "sigExplanation" SG_ 778 ESP_30A_CheckSum "null";
BA_ "sigConfig" SG_ 778 ESP_30A_CheckSum "null";
BA_ "sigSecLevel" SG_ 778 ESP_30A_AliveCounter "null";
BA_ "sigExplanation" SG_ 778 ESP_30A_AliveCounter "null";
BA_ "sigConfig" SG_ 778 ESP_30A_AliveCounter "null";
BA_ "sigSecLevel" SG_ 778 ESP_LgtOffs "null";
BA_ "sigExplanation" SG_ 778 ESP_LgtOffs "null";
BA_ "sigConfig" SG_ 778 ESP_LgtOffs "null";
BA_ "GenSigStartValue" SG_ 778 ESP_LgtOffs 796;
BA_ "sigSecLevel" SG_ 778 ESP_LatOffs "null";
BA_ "sigExplanation" SG_ 778 ESP_LatOffs "null";
BA_ "sigConfig" SG_ 778 ESP_LatOffs "null";
BA_ "GenSigStartValue" SG_ 778 ESP_LatOffs 796;
BA_ "sigSecLevel" SG_ 778 ESP_YAWVOffs "null";
BA_ "sigExplanation" SG_ 778 ESP_YAWVOffs "null";
BA_ "sigConfig" SG_ 778 ESP_YAWVOffs "null";
BA_ "GenSigStartValue" SG_ 778 ESP_YAWVOffs 2143;
BA_ "sigSecLevel" SG_ 784 CIM_310_CheckSum "null";
BA_ "sigExplanation" SG_ 784 CIM_310_CheckSum "null";
BA_ "sigConfig" SG_ 784 CIM_310_CheckSum "null";
BA_ "sigSecLevel" SG_ 784 CIM_310_AliveCounter "null";
BA_ "sigExplanation" SG_ 784 CIM_310_AliveCounter "null";
BA_ "sigConfig" SG_ 784 CIM_310_AliveCounter "null";
BA_ "sigSecLevel" SG_ 784 CIM_TurnLampSwtSts "B";
BA_ "sigExplanation" SG_ 784 CIM_TurnLampSwtSts "null";
BA_ "sigConfig" SG_ 784 CIM_TurnLampSwtSts "null";
BA_ "sigSecLevel" SG_ 784 CIM_HiBeamSwtSts "A";
BA_ "sigExplanation" SG_ 784 CIM_HiBeamSwtSts "null";
BA_ "sigConfig" SG_ 784 CIM_HiBeamSwtSts "null";
BA_ "sigSecLevel" SG_ 784 CIM_FrntWshrSwtSts "null";
BA_ "sigExplanation" SG_ 784 CIM_FrntWshrSwtSts "null";
BA_ "sigConfig" SG_ 784 CIM_FrntWshrSwtSts "null";
BA_ "sigSecLevel" SG_ 784 CIM_FrntWiprSwtSts "A";
BA_ "sigExplanation" SG_ 784 CIM_FrntWiprSwtSts "null";
BA_ "sigConfig" SG_ 784 CIM_FrntWiprSwtSts "null";
BA_ "sigSecLevel" SG_ 792 ESP_318_CheckSum "null";
BA_ "sigExplanation" SG_ 792 ESP_318_CheckSum "null";
BA_ "sigConfig" SG_ 792 ESP_318_CheckSum "null";
BA_ "sigSecLevel" SG_ 792 ESP_318_AliveCounter "null";
BA_ "sigExplanation" SG_ 792 ESP_318_AliveCounter "null";
BA_ "sigConfig" SG_ 792 ESP_318_AliveCounter "null";
BA_ "sigSecLevel" SG_ 792 ESP_BrkPedlStsVld "C";
BA_ "sigExplanation" SG_ 792 ESP_BrkPedlStsVld "null";
BA_ "sigConfig" SG_ 792 ESP_BrkPedlStsVld "null";
BA_ "sigSecLevel" SG_ 792 ESP_BrkPedlSts "C";
BA_ "sigExplanation" SG_ 792 ESP_BrkPedlSts "null";
BA_ "sigConfig" SG_ 792 ESP_BrkPedlSts "null";
BA_ "sigSecLevel" SG_ 792 ESP_VehSpdVld "B";
BA_ "sigExplanation" SG_ 792 ESP_VehSpdVld "null";
BA_ "sigConfig" SG_ 792 ESP_VehSpdVld "null";
BA_ "sigSecLevel" SG_ 792 ESP_SysActv "null";
BA_ "sigExplanation" SG_ 792 ESP_SysActv "null";
BA_ "sigConfig" SG_ 792 ESP_SysActv "null";
BA_ "sigSecLevel" SG_ 792 ESP_LampSwtOffIndcn "null";
BA_ "sigExplanation" SG_ 792 ESP_LampSwtOffIndcn "null";
BA_ "sigConfig" SG_ 792 ESP_LampSwtOffIndcn "null";
BA_ "sigSecLevel" SG_ 792 ESP_FltIndcn_EBD "null";
BA_ "sigExplanation" SG_ 792 ESP_FltIndcn_EBD "null";
BA_ "sigConfig" SG_ 792 ESP_FltIndcn_EBD "null";
BA_ "sigSecLevel" SG_ 792 ESP_FltIndcn_ABS "B";
BA_ "sigExplanation" SG_ 792 ESP_FltIndcn_ABS "null";
BA_ "sigConfig" SG_ 792 ESP_FltIndcn_ABS "null";
BA_ "sigSecLevel" SG_ 792 ESP_MilgRollgCntr_ODO "null";
BA_ "sigExplanation" SG_ 792 ESP_MilgRollgCntr_ODO "null";
BA_ "sigConfig" SG_ 792 ESP_MilgRollgCntr_ODO "null";
BA_ "sigSecLevel" SG_ 792 ESP_VehSpd "B";
BA_ "sigExplanation" SG_ 792 ESP_VehSpd "null";
BA_ "sigConfig" SG_ 792 ESP_VehSpd "null";
BA_ "sigSecLevel" SG_ 792 ESP_IninModSigIndcn "null";
BA_ "sigExplanation" SG_ 792 ESP_IninModSigIndcn "null";
BA_ "sigConfig" SG_ 792 ESP_IninModSigIndcn "null";
BA_ "sigSecLevel" SG_ 792 ESP_FltIndcn_TCS "B";
BA_ "sigExplanation" SG_ 792 ESP_FltIndcn_TCS "null";
BA_ "sigConfig" SG_ 792 ESP_FltIndcn_TCS "null";
BA_ "sigSecLevel" SG_ 792 ESP_CtrlSts_HDC "null";
BA_ "sigExplanation" SG_ 792 ESP_CtrlSts_HDC "null";
BA_ "sigConfig" SG_ 792 ESP_CtrlSts_HDC "null";
BA_ "sigSecLevel" SG_ 792 ESP_AvlIndcn_HDC "null";
BA_ "sigExplanation" SG_ 792 ESP_AvlIndcn_HDC "null";
BA_ "sigConfig" SG_ 792 ESP_AvlIndcn_HDC "null";
BA_ "sigSecLevel" SG_ 792 ESP_NoBrkP "null";
BA_ "sigExplanation" SG_ 792 ESP_NoBrkP "null";
BA_ "sigConfig" SG_ 792 ESP_NoBrkP "null";
BA_ "sigSecLevel" SG_ 792 ESP_RDAEnaFlg "null";
BA_ "sigExplanation" SG_ 792 ESP_RDAEnaFlg "null";
BA_ "sigConfig" SG_ 792 ESP_RDAEnaFlg "null";
BA_ "sigSecLevel" SG_ 819 BCM_333_CheckSum "null";
BA_ "sigExplanation" SG_ 819 BCM_333_CheckSum "null";
BA_ "sigConfig" SG_ 819 BCM_333_CheckSum "null";
BA_ "sigSecLevel" SG_ 819 BCM_333_AliveCounter "null";
BA_ "sigExplanation" SG_ 819 BCM_333_AliveCounter "null";
BA_ "sigConfig" SG_ 819 BCM_333_AliveCounter "null";
BA_ "sigSecLevel" SG_ 819 BCM_KL15_Off_Announcement "null";
BA_ "sigExplanation" SG_ 819 BCM_KL15_Off_Announcement "null";
BA_ "sigConfig" SG_ 819 BCM_KL15_Off_Announcement "null";
BA_ "sigSecLevel" SG_ 819 BCM_IG1Sts "null";
BA_ "sigExplanation" SG_ 819 BCM_IG1Sts "null";
BA_ "sigConfig" SG_ 819 BCM_IG1Sts "null";
BA_ "sigSecLevel" SG_ 819 BCM_PwrMod "B";
BA_ "sigExplanation" SG_ 819 BCM_PwrMod "null";
BA_ "sigConfig" SG_ 819 BCM_PwrMod "null";
BA_ "sigSecLevel" SG_ 819 BCM_PwrModVld "B";
BA_ "sigExplanation" SG_ 819 BCM_PwrModVld "null";
BA_ "sigConfig" SG_ 819 BCM_PwrModVld "null";
BA_ "sigSecLevel" SG_ 819 BCM_BrkSwtSts "null";
BA_ "sigExplanation" SG_ 819 BCM_BrkSwtSts "null";
BA_ "sigConfig" SG_ 819 BCM_BrkSwtSts "null";
BA_ "sigSecLevel" SG_ 819 BCM_IG1StsVld_CAPE "null";
BA_ "sigExplanation" SG_ 819 BCM_IG1StsVld_CAPE "null";
BA_ "sigConfig" SG_ 819 BCM_IG1StsVld_CAPE "null";
BA_ "sigSecLevel" SG_ 819 BCM_IG2StsVld_CAPE "null";
BA_ "sigExplanation" SG_ 819 BCM_IG2StsVld_CAPE "null";
BA_ "sigConfig" SG_ 819 BCM_IG2StsVld_CAPE "null";
BA_ "sigSecLevel" SG_ 819 BCM_KL30s_L "null";
BA_ "sigExplanation" SG_ 819 BCM_KL30s_L "null";
BA_ "sigConfig" SG_ 819 BCM_KL30s_L "null";
BA_ "sigSecLevel" SG_ 819 BCM_IG2Sts "null";
BA_ "sigExplanation" SG_ 819 BCM_IG2Sts "null";
BA_ "sigConfig" SG_ 819 BCM_IG2Sts "null";
BA_ "sigSecLevel" SG_ 819 BCM_InteriorSwtSt "null";
BA_ "sigExplanation" SG_ 819 BCM_InteriorSwtSt "null";
BA_ "sigConfig" SG_ 819 BCM_InteriorSwtSt "null";
BA_ "sigSecLevel" SG_ 821 BCM_335_CheckSum "null";
BA_ "sigExplanation" SG_ 821 BCM_335_CheckSum "null";
BA_ "sigConfig" SG_ 821 BCM_335_CheckSum "null";
BA_ "sigSecLevel" SG_ 821 BCM_335_AliveCounter "null";
BA_ "sigExplanation" SG_ 821 BCM_335_AliveCounter "null";
BA_ "sigConfig" SG_ 821 BCM_335_AliveCounter "null";
BA_ "sigSecLevel" SG_ 821 BCM_WiprInSrvPosn "null";
BA_ "sigExplanation" SG_ 821 BCM_WiprInSrvPosn "null";
BA_ "sigConfig" SG_ 821 BCM_WiprInSrvPosn "null";
BA_ "sigSecLevel" SG_ 821 BCM_IntLampTiSetSts "null";
BA_ "sigExplanation" SG_ 821 BCM_IntLampTiSetSts "null";
BA_ "sigConfig" SG_ 821 BCM_IntLampTiSetSts "null";
BA_ "sigSecLevel" SG_ 821 BCM_WaterPosnSnsrSwtSts "null";
BA_ "sigExplanation" SG_ 821 BCM_WaterPosnSnsrSwtSts "null";
BA_ "sigConfig" SG_ 821 BCM_WaterPosnSnsrSwtSts "null";
BA_ "sigSecLevel" SG_ 821 BCM_FrntFogLampOutpCmd "null";
BA_ "sigExplanation" SG_ 821 BCM_FrntFogLampOutpCmd "null";
BA_ "sigConfig" SG_ 821 BCM_FrntFogLampOutpCmd "null";
BA_ "sigSecLevel" SG_ 821 BCM_LicPlateLampOutpCmd "null";
BA_ "sigExplanation" SG_ 821 BCM_LicPlateLampOutpCmd "null";
BA_ "sigConfig" SG_ 821 BCM_LicPlateLampOutpCmd "null";
BA_ "sigSecLevel" SG_ 821 BCM_EnaSts_ADB "null";
BA_ "sigExplanation" SG_ 821 BCM_EnaSts_ADB "null";
BA_ "sigConfig" SG_ 821 BCM_EnaSts_ADB "null";
BA_ "sigSecLevel" SG_ 821 BCM_PwrSaveOutpCmd "null";
BA_ "sigExplanation" SG_ 821 BCM_PwrSaveOutpCmd "null";
BA_ "sigConfig" SG_ 821 BCM_PwrSaveOutpCmd "null";
BA_ "sigSecLevel" SG_ 821 BCM_ExtLampSwtSts "null";
BA_ "sigExplanation" SG_ 821 BCM_ExtLampSwtSts "null";
BA_ "sigConfig" SG_ 821 BCM_ExtLampSwtSts "null";
BA_ "sigSecLevel" SG_ 821 BCM_HornOutpCmd "null";
BA_ "sigExplanation" SG_ 821 BCM_HornOutpCmd "null";
BA_ "sigConfig" SG_ 821 BCM_HornOutpCmd "null";
BA_ "sigSecLevel" SG_ 821 BCM_HornSwtSts "null";
BA_ "sigExplanation" SG_ 821 BCM_HornSwtSts "null";
BA_ "sigConfig" SG_ 821 BCM_HornSwtSts "null";
BA_ "sigSecLevel" SG_ 821 BCM_WelLampOutpCmd "null";
BA_ "sigExplanation" SG_ 821 BCM_WelLampOutpCmd "null";
BA_ "sigConfig" SG_ 821 BCM_WelLampOutpCmd "null";
BA_ "sigSecLevel" SG_ 821 BCM_FolwMeHomeSts "null";
BA_ "sigExplanation" SG_ 821 BCM_FolwMeHomeSts "null";
BA_ "sigConfig" SG_ 821 BCM_FolwMeHomeSts "null";
BA_ "sigSecLevel" SG_ 821 BCM_FrntFogLampSwtSts "null";
BA_ "sigExplanation" SG_ 821 BCM_FrntFogLampSwtSts "null";
BA_ "sigConfig" SG_ 821 BCM_FrntFogLampSwtSts "null";
BA_ "sigSecLevel" SG_ 821 BCM_ReFogLampSwtSts "null";
BA_ "sigExplanation" SG_ 821 BCM_ReFogLampSwtSts "null";
BA_ "sigConfig" SG_ 821 BCM_ReFogLampSwtSts "null";
BA_ "sigSecLevel" SG_ 821 BCM_ReWiprBackSwtSts "null";
BA_ "sigExplanation" SG_ 821 BCM_ReWiprBackSwtSts "null";
BA_ "sigConfig" SG_ 821 BCM_ReWiprBackSwtSts "null";
BA_ "sigSecLevel" SG_ 821 BCM_RainClsSunroofSetSts "null";
BA_ "sigExplanation" SG_ 821 BCM_RainClsSunroofSetSts "null";
BA_ "sigConfig" SG_ 821 BCM_RainClsSunroofSetSts "null";
BA_ "sigSecLevel" SG_ 821 BCM_MirrLockAutoSetSts "null";
BA_ "sigExplanation" SG_ 821 BCM_MirrLockAutoSetSts "null";
BA_ "sigConfig" SG_ 821 BCM_MirrLockAutoSetSts "null";
BA_ "sigSecLevel" SG_ 821 BCM_FrntWshrOutpCmd "null";
BA_ "sigExplanation" SG_ 821 BCM_FrntWshrOutpCmd "null";
BA_ "sigConfig" SG_ 821 BCM_FrntWshrOutpCmd "null";
BA_ "sigSecLevel" SG_ 821 BCM_DangerAlrmLampSwtSts "A";
BA_ "sigExplanation" SG_ 821 BCM_DangerAlrmLampSwtSts "null";
BA_ "sigConfig" SG_ 821 BCM_DangerAlrmLampSwtSts "null";
BA_ "sigSecLevel" SG_ 821 BCM_ReDefrstHeatgCmd "null";
BA_ "sigExplanation" SG_ 821 BCM_ReDefrstHeatgCmd "null";
BA_ "sigConfig" SG_ 821 BCM_ReDefrstHeatgCmd "null";
BA_ "sigSecLevel" SG_ 821 BCM_RvsLampOutpCmd "null";
BA_ "sigExplanation" SG_ 821 BCM_RvsLampOutpCmd "null";
BA_ "sigConfig" SG_ 821 BCM_RvsLampOutpCmd "null";
BA_ "sigSecLevel" SG_ 821 BCM_IntLampOutpCmd "null";
BA_ "sigExplanation" SG_ 821 BCM_IntLampOutpCmd "null";
BA_ "sigConfig" SG_ 821 BCM_IntLampOutpCmd "null";
BA_ "sigSecLevel" SG_ 821 BCM_LeTrunLampOutpCmd "B";
BA_ "sigExplanation" SG_ 821 BCM_LeTrunLampOutpCmd "null";
BA_ "sigConfig" SG_ 821 BCM_LeTrunLampOutpCmd "null";
BA_ "sigSecLevel" SG_ 821 BCM_RiTrunLampOutpCmd "B";
BA_ "sigExplanation" SG_ 821 BCM_RiTrunLampOutpCmd "null";
BA_ "sigConfig" SG_ 821 BCM_RiTrunLampOutpCmd "null";
BA_ "sigSecLevel" SG_ 821 BCM_ReWiprOutpCmd "null";
BA_ "sigExplanation" SG_ 821 BCM_ReWiprOutpCmd "null";
BA_ "sigConfig" SG_ 821 BCM_ReWiprOutpCmd "null";
BA_ "sigSecLevel" SG_ 821 BCM_ReWshrOutpCmd "null";
BA_ "sigExplanation" SG_ 821 BCM_ReWshrOutpCmd "null";
BA_ "sigConfig" SG_ 821 BCM_ReWshrOutpCmd "null";
BA_ "sigSecLevel" SG_ 821 BCM_BrkLampSwtSts "null";
BA_ "sigExplanation" SG_ 821 BCM_BrkLampSwtSts "null";
BA_ "sigConfig" SG_ 821 BCM_BrkLampSwtSts "null";
BA_ "sigSecLevel" SG_ 821 BCM_HiBeamOutpCmd "null";
BA_ "sigExplanation" SG_ 821 BCM_HiBeamOutpCmd "null";
BA_ "sigConfig" SG_ 821 BCM_HiBeamOutpCmd "null";
BA_ "sigSecLevel" SG_ 821 BCM_LoBeamOutpCmd "null";
BA_ "sigExplanation" SG_ 821 BCM_LoBeamOutpCmd "null";
BA_ "sigConfig" SG_ 821 BCM_LoBeamOutpCmd "null";
BA_ "sigSecLevel" SG_ 821 BCM_PosnLampOutpCmd "A";
BA_ "sigExplanation" SG_ 821 BCM_PosnLampOutpCmd "null";
BA_ "sigConfig" SG_ 821 BCM_PosnLampOutpCmd "null";
BA_ "sigSecLevel" SG_ 821 BCM_BrkLampOutpCmd "A";
BA_ "sigExplanation" SG_ 821 BCM_BrkLampOutpCmd "null";
BA_ "sigConfig" SG_ 821 BCM_BrkLampOutpCmd "null";
BA_ "sigSecLevel" SG_ 821 BCM_ReFogLampOutpCmd "null";
BA_ "sigExplanation" SG_ 821 BCM_ReFogLampOutpCmd "null";
BA_ "sigConfig" SG_ 821 BCM_ReFogLampOutpCmd "null";
BA_ "sigSecLevel" SG_ 821 BCM_FrntWiprSpd "null";
BA_ "sigExplanation" SG_ 821 BCM_FrntWiprSpd "null";
BA_ "sigConfig" SG_ 821 BCM_FrntWiprSpd "null";
BA_ "sigSecLevel" SG_ 821 BCM_EnaReq_ADB "null";
BA_ "sigExplanation" SG_ 821 BCM_EnaReq_ADB "null";
BA_ "sigConfig" SG_ 821 BCM_EnaReq_ADB "null";
BA_ "sigSecLevel" SG_ 821 BCM_VehAmbBri "null";
BA_ "sigExplanation" SG_ 821 BCM_VehAmbBri "null";
BA_ "sigConfig" SG_ 821 BCM_VehAmbBri "null";
BA_ "GenSigStartValue" SG_ 821 BCM_VehAmbBri 255;
BA_ "sigSecLevel" SG_ 822 ICC_336_Checksum "null";
BA_ "sigExplanation" SG_ 822 ICC_336_Checksum "null";
BA_ "sigConfig" SG_ 822 ICC_336_Checksum "null";
BA_ "sigSecLevel" SG_ 822 ICC_336_AliveCounter "null";
BA_ "sigExplanation" SG_ 822 ICC_336_AliveCounter "null";
BA_ "sigConfig" SG_ 822 ICC_336_AliveCounter "null";
BA_ "sigSecLevel" SG_ 822 ICC_SetAtmLampBri "null";
BA_ "sigExplanation" SG_ 822 ICC_SetAtmLampBri "null";
BA_ "sigConfig" SG_ 822 ICC_SetAtmLampBri "null";
BA_ "sigSecLevel" SG_ 822 ICC_SuspSet "null";
BA_ "sigExplanation" SG_ 822 ICC_SuspSet "null";
BA_ "sigConfig" SG_ 822 ICC_SuspSet "null";
BA_ "sigSecLevel" SG_ 822 ICC_AtmLampOpenCmd "null";
BA_ "sigExplanation" SG_ 822 ICC_AtmLampOpenCmd "null";
BA_ "sigConfig" SG_ 822 ICC_AtmLampOpenCmd "null";
BA_ "sigSecLevel" SG_ 822 ICC_SteerAssiSet "B";
BA_ "sigExplanation" SG_ 822 ICC_SteerAssiSet "null";
BA_ "sigConfig" SG_ 822 ICC_SteerAssiSet "null";
BA_ "sigSecLevel" SG_ 822 ICC_SetStorageBriLvl "null";
BA_ "sigExplanation" SG_ 822 ICC_SetStorageBriLvl "null";
BA_ "sigConfig" SG_ 822 ICC_SetStorageBriLvl "null";
BA_ "sigSecLevel" SG_ 822 ICC_HDCSwtSig "null";
BA_ "sigExplanation" SG_ 822 ICC_HDCSwtSig "null";
BA_ "sigConfig" SG_ 822 ICC_HDCSwtSig "null";
BA_ "sigSecLevel" SG_ 822 ICC_ESPSwtSig "null";
BA_ "sigExplanation" SG_ 822 ICC_ESPSwtSig "null";
BA_ "sigConfig" SG_ 822 ICC_ESPSwtSig "null";
BA_ "sigSecLevel" SG_ 822 ICC_ReqCalifModHMIBtn "null";
BA_ "sigExplanation" SG_ 822 ICC_ReqCalifModHMIBtn "null";
BA_ "sigConfig" SG_ 822 ICC_ReqCalifModHMIBtn "null";
BA_ "sigSecLevel" SG_ 822 ICC_SpdLimOffs "null";
BA_ "sigExplanation" SG_ 822 ICC_SpdLimOffs "null";
BA_ "sigConfig" SG_ 822 ICC_SpdLimOffs "null";
BA_ "sigSecLevel" SG_ 822 ICC_iTPMSResetSig "null";
BA_ "sigExplanation" SG_ 822 ICC_iTPMSResetSig "null";
BA_ "sigConfig" SG_ 822 ICC_iTPMSResetSig "null";
BA_ "sigSecLevel" SG_ 822 ICC_WIFIOnOffSig "null";
BA_ "sigExplanation" SG_ 822 ICC_WIFIOnOffSig "null";
BA_ "sigConfig" SG_ 822 ICC_WIFIOnOffSig "null";
BA_ "sigSecLevel" SG_ 822 ICC_LeMirrAlrmLampFlt "null";
BA_ "sigExplanation" SG_ 822 ICC_LeMirrAlrmLampFlt "null";
BA_ "sigConfig" SG_ 822 ICC_LeMirrAlrmLampFlt "null";
BA_ "sigSecLevel" SG_ 822 ICC_RiMirrAlrmLampFlt "null";
BA_ "sigExplanation" SG_ 822 ICC_RiMirrAlrmLampFlt "null";
BA_ "sigConfig" SG_ 822 ICC_RiMirrAlrmLampFlt "null";
BA_ "sigSecLevel" SG_ 822 ICC_PhoneSt "null";
BA_ "sigExplanation" SG_ 822 ICC_PhoneSt "null";
BA_ "sigConfig" SG_ 822 ICC_PhoneSt "null";
BA_ "sigSecLevel" SG_ 822 ICC_SpeechSt "null";
BA_ "sigExplanation" SG_ 822 ICC_SpeechSt "null";
BA_ "sigConfig" SG_ 822 ICC_SpeechSt "null";
BA_ "sigSecLevel" SG_ 837 BCM_345_CheckSum "null";
BA_ "sigExplanation" SG_ 837 BCM_345_CheckSum "null";
BA_ "sigConfig" SG_ 837 BCM_345_CheckSum "null";
BA_ "sigSecLevel" SG_ 837 BCM_345_AliveCounter "null";
BA_ "sigExplanation" SG_ 837 BCM_345_AliveCounter "null";
BA_ "sigConfig" SG_ 837 BCM_345_AliveCounter "null";
BA_ "sigSecLevel" SG_ 837 BCM_OutpValResl_HUD "null";
BA_ "sigExplanation" SG_ 837 BCM_OutpValResl_HUD "null";
BA_ "sigConfig" SG_ 837 BCM_OutpValResl_HUD "null";
BA_ "sigSecLevel" SG_ 837 BCM_SunshadeRunngSts "null";
BA_ "sigExplanation" SG_ 837 BCM_SunshadeRunngSts "null";
BA_ "sigConfig" SG_ 837 BCM_SunshadeRunngSts "null";
BA_ "sigSecLevel" SG_ 837 BCM_RiSolaValr_RLS "A";
BA_ "sigExplanation" SG_ 837 BCM_RiSolaValr_RLS "null";
BA_ "sigConfig" SG_ 837 BCM_RiSolaValr_RLS "null";
BA_ "sigSecLevel" SG_ 837 BCM_LeSolaValr_RLS "A";
BA_ "sigExplanation" SG_ 837 BCM_LeSolaValr_RLS "null";
BA_ "sigConfig" SG_ 837 BCM_LeSolaValr_RLS "null";
BA_ "sigSecLevel" SG_ 837 BCM_WindshdHum_RLS "A";
BA_ "sigExplanation" SG_ 837 BCM_WindshdHum_RLS "null";
BA_ "sigConfig" SG_ 837 BCM_WindshdHum_RLS "null";
BA_ "sigSecLevel" SG_ 837 BCM_WindshdT_RLS "A";
BA_ "sigExplanation" SG_ 837 BCM_WindshdT_RLS "null";
BA_ "sigConfig" SG_ 837 BCM_WindshdT_RLS "null";
BA_ "sigSecLevel" SG_ 837 BCM_MeasdVal_HUD "null";
BA_ "sigExplanation" SG_ 837 BCM_MeasdVal_HUD "null";
BA_ "sigConfig" SG_ 837 BCM_MeasdVal_HUD "null";
BA_ "sigSecLevel" SG_ 837 BCM_SunshadePosnInfo "null";
BA_ "sigExplanation" SG_ 837 BCM_SunshadePosnInfo "null";
BA_ "sigConfig" SG_ 837 BCM_SunshadePosnInfo "null";
BA_ "sigSecLevel" SG_ 856 VCU_358_CheckSum "null";
BA_ "sigExplanation" SG_ 856 VCU_358_CheckSum "null";
BA_ "sigConfig" SG_ 856 VCU_358_CheckSum "null";
BA_ "sigSecLevel" SG_ 856 VCU_358_AliveCounter "null";
BA_ "sigExplanation" SG_ 856 VCU_358_AliveCounter "null";
BA_ "sigConfig" SG_ 856 VCU_358_AliveCounter "null";
BA_ "sigSecLevel" SG_ 856 VCU_EPedlEnaSig "null";
BA_ "sigExplanation" SG_ 856 VCU_EPedlEnaSig "null";
BA_ "sigConfig" SG_ 856 VCU_EPedlEnaSig "null";
BA_ "sigSecLevel" SG_ 856 VCU_ComLostFlt_ESP "null";
BA_ "sigExplanation" SG_ 856 VCU_ComLostFlt_ESP "null";
BA_ "sigConfig" SG_ 856 VCU_ComLostFlt_ESP "null";
BA_ "sigSecLevel" SG_ 856 VCU_ComFlt_iBooster "null";
BA_ "sigExplanation" SG_ 856 VCU_ComFlt_iBooster "null";
BA_ "sigConfig" SG_ 856 VCU_ComFlt_iBooster "null";
BA_ "sigSecLevel" SG_ 856 VCU_RegenLvlFb "null";
BA_ "sigExplanation" SG_ 856 VCU_RegenLvlFb "null";
BA_ "sigConfig" SG_ 856 VCU_RegenLvlFb "null";
BA_ "sigSecLevel" SG_ 856 VCU_AccelModFb "null";
BA_ "sigExplanation" SG_ 856 VCU_AccelModFb "null";
BA_ "sigConfig" SG_ 856 VCU_AccelModFb "null";
BA_ "sigSecLevel" SG_ 856 VCU_EPedlStsFb "null";
BA_ "sigExplanation" SG_ 856 VCU_EPedlStsFb "null";
BA_ "sigConfig" SG_ 856 VCU_EPedlStsFb "null";
BA_ "sigSecLevel" SG_ 856 VCU_CcTrgSpdDisp "null";
BA_ "sigExplanation" SG_ 856 VCU_CcTrgSpdDisp "null";
BA_ "sigConfig" SG_ 856 VCU_CcTrgSpdDisp "null";
BA_ "sigSecLevel" SG_ 856 VCU_Sts_CC_ICC "null";
BA_ "sigExplanation" SG_ 856 VCU_Sts_CC_ICC "null";
BA_ "sigConfig" SG_ 856 VCU_Sts_CC_ICC "null";
BA_ "sigSecLevel" SG_ 856 VCU_CCIconDisp "null";
BA_ "sigExplanation" SG_ 856 VCU_CCIconDisp "null";
BA_ "sigConfig" SG_ 856 VCU_CCIconDisp "null";
BA_ "sigSecLevel" SG_ 856 VCU_DispSpdUnit_CC "null";
BA_ "sigExplanation" SG_ 856 VCU_DispSpdUnit_CC "null";
BA_ "sigConfig" SG_ 856 VCU_DispSpdUnit_CC "null";
BA_ "sigSecLevel" SG_ 866 ICC_MetaCountryCode "null";
BA_ "sigExplanation" SG_ 866 ICC_MetaCountryCode "null";
BA_ "sigConfig" SG_ 866 ICC_MetaCountryCode "null";
BA_ "sigSecLevel" SG_ 866 ICC_MetaMapProvider "null";
BA_ "sigExplanation" SG_ 866 ICC_MetaMapProvider "null";
BA_ "sigConfig" SG_ 866 ICC_MetaMapProvider "null";
BA_ "sigSecLevel" SG_ 866 ICC_MetaMsgType "null";
BA_ "sigExplanation" SG_ 866 ICC_MetaMsgType "null";
BA_ "sigConfig" SG_ 866 ICC_MetaMsgType "null";
BA_ "GenSigStartValue" SG_ 866 ICC_MetaMsgType 6;
BA_ "sigSecLevel" SG_ 866 ICC_MetaHwVer "null";
BA_ "sigExplanation" SG_ 866 ICC_MetaHwVer "null";
BA_ "sigConfig" SG_ 866 ICC_MetaHwVer "null";
BA_ "sigSecLevel" SG_ 866 ICC_MetaProtVerMinorSub "null";
BA_ "sigExplanation" SG_ 866 ICC_MetaProtVerMinorSub "null";
BA_ "sigConfig" SG_ 866 ICC_MetaProtVerMinorSub "null";
BA_ "sigSecLevel" SG_ 866 ICC_MetaProtVerMajor "null";
BA_ "sigExplanation" SG_ 866 ICC_MetaProtVerMajor "null";
BA_ "sigConfig" SG_ 866 ICC_MetaProtVerMajor "null";
BA_ "sigSecLevel" SG_ 866 ICC_MetaCycCnt "null";
BA_ "sigExplanation" SG_ 866 ICC_MetaCycCnt "null";
BA_ "sigConfig" SG_ 866 ICC_MetaCycCnt "null";
BA_ "sigSecLevel" SG_ 866 ICC_MetaRegionCode "null";
BA_ "sigExplanation" SG_ 866 ICC_MetaRegionCode "null";
BA_ "sigConfig" SG_ 866 ICC_MetaRegionCode "null";
BA_ "sigSecLevel" SG_ 866 ICC_MetaDrvSide "null";
BA_ "sigExplanation" SG_ 866 ICC_MetaDrvSide "null";
BA_ "sigConfig" SG_ 866 ICC_MetaDrvSide "null";
BA_ "sigSecLevel" SG_ 866 ICC_MetaMapVerYear "null";
BA_ "sigExplanation" SG_ 866 ICC_MetaMapVerYear "null";
BA_ "sigConfig" SG_ 866 ICC_MetaMapVerYear "null";
BA_ "sigSecLevel" SG_ 866 ICC_MetaMapVerQtr "null";
BA_ "sigExplanation" SG_ 866 ICC_MetaMapVerQtr "null";
BA_ "sigConfig" SG_ 866 ICC_MetaMapVerQtr "null";
BA_ "sigSecLevel" SG_ 866 ICC_MetaProtVerMinor "null";
BA_ "sigExplanation" SG_ 866 ICC_MetaProtVerMinor "null";
BA_ "sigConfig" SG_ 866 ICC_MetaProtVerMinor "null";
BA_ "sigSecLevel" SG_ 866 ICC_MetaSpdUnits "null";
BA_ "sigExplanation" SG_ 866 ICC_MetaSpdUnits "null";
BA_ "sigConfig" SG_ 866 ICC_MetaSpdUnits "null";
BA_ "sigSecLevel" SG_ 866 ICC_Reserved "null";
BA_ "sigExplanation" SG_ 866 ICC_Reserved "null";
BA_ "sigConfig" SG_ 866 ICC_Reserved "null";
BA_ "sigSecLevel" SG_ 883 ECC_CrtSts "null";
BA_ "sigExplanation" SG_ 883 ECC_CrtSts "null";
BA_ "sigConfig" SG_ 883 ECC_CrtSts "null";
BA_ "sigSecLevel" SG_ 883 ECC_IninSts "null";
BA_ "sigExplanation" SG_ 883 ECC_IninSts "null";
BA_ "sigConfig" SG_ 883 ECC_IninSts "null";
BA_ "sigSecLevel" SG_ 883 ECC_PwrSysHeatMngtSts "null";
BA_ "sigExplanation" SG_ 883 ECC_PwrSysHeatMngtSts "null";
BA_ "sigConfig" SG_ 883 ECC_PwrSysHeatMngtSts "null";
BA_ "sigSecLevel" SG_ 883 ECC_ACSts "null";
BA_ "sigExplanation" SG_ 883 ECC_ACSts "null";
BA_ "sigConfig" SG_ 883 ECC_ACSts "null";
BA_ "sigSecLevel" SG_ 883 ECC_AirClnSts "null";
BA_ "sigExplanation" SG_ 883 ECC_AirClnSts "null";
BA_ "sigConfig" SG_ 883 ECC_AirClnSts "null";
BA_ "sigSecLevel" SG_ 883 ECC_WindSpdSts "null";
BA_ "sigExplanation" SG_ 883 ECC_WindSpdSts "null";
BA_ "sigConfig" SG_ 883 ECC_WindSpdSts "null";
BA_ "sigSecLevel" SG_ 883 ECC_BackRowAirOutlModSts "null";
BA_ "sigExplanation" SG_ 883 ECC_BackRowAirOutlModSts "null";
BA_ "sigConfig" SG_ 883 ECC_BackRowAirOutlModSts "null";
BA_ "sigSecLevel" SG_ 883 ECC_DrvrTSetSts "null";
BA_ "sigExplanation" SG_ 883 ECC_DrvrTSetSts "null";
BA_ "sigConfig" SG_ 883 ECC_DrvrTSetSts "null";
BA_ "sigSecLevel" SG_ 883 ECC_PassTSetSts "null";
BA_ "sigExplanation" SG_ 883 ECC_PassTSetSts "null";
BA_ "sigConfig" SG_ 883 ECC_PassTSetSts "null";
BA_ "sigSecLevel" SG_ 883 ECC_HeatSts "null";
BA_ "sigExplanation" SG_ 883 ECC_HeatSts "null";
BA_ "sigConfig" SG_ 883 ECC_HeatSts "null";
BA_ "sigSecLevel" SG_ 883 ECC_AUTOSts "null";
BA_ "sigExplanation" SG_ 883 ECC_AUTOSts "null";
BA_ "sigConfig" SG_ 883 ECC_AUTOSts "null";
BA_ "sigSecLevel" SG_ 883 ECC_SYNCSts "null";
BA_ "sigExplanation" SG_ 883 ECC_SYNCSts "null";
BA_ "sigConfig" SG_ 883 ECC_SYNCSts "null";
BA_ "sigSecLevel" SG_ 883 ECC_InfoSysWrmColdDisp "null";
BA_ "sigExplanation" SG_ 883 ECC_InfoSysWrmColdDisp "null";
BA_ "sigConfig" SG_ 883 ECC_InfoSysWrmColdDisp "null";
BA_ "sigSecLevel" SG_ 883 ECC_CircSts "null";
BA_ "sigExplanation" SG_ 883 ECC_CircSts "null";
BA_ "sigConfig" SG_ 883 ECC_CircSts "null";
BA_ "sigSecLevel" SG_ 883 ECC_ParticleConcVld "null";
BA_ "sigExplanation" SG_ 883 ECC_ParticleConcVld "null";
BA_ "sigConfig" SG_ 883 ECC_ParticleConcVld "null";
BA_ "sigSecLevel" SG_ 883 ECC_OutdT "null";
BA_ "sigExplanation" SG_ 883 ECC_OutdT "null";
BA_ "sigConfig" SG_ 883 ECC_OutdT "null";
BA_ "GenSigStartValue" SG_ 883 ECC_OutdT 48;
BA_ "sigSecLevel" SG_ 883 ECC_OutdTVld "null";
BA_ "sigExplanation" SG_ 883 ECC_OutdTVld "null";
BA_ "sigConfig" SG_ 883 ECC_OutdTVld "null";
BA_ "sigSecLevel" SG_ 883 ECC_MaxFrntDefrst "null";
BA_ "sigExplanation" SG_ 883 ECC_MaxFrntDefrst "null";
BA_ "sigConfig" SG_ 883 ECC_MaxFrntDefrst "null";
BA_ "sigSecLevel" SG_ 883 ECC_HeatMngtSysFlt "null";
BA_ "sigExplanation" SG_ 883 ECC_HeatMngtSysFlt "null";
BA_ "sigConfig" SG_ 883 ECC_HeatMngtSysFlt "null";
BA_ "sigSecLevel" SG_ 883 ECC_HeatMngtFctLim "null";
BA_ "sigExplanation" SG_ 883 ECC_HeatMngtFctLim "null";
BA_ "sigConfig" SG_ 883 ECC_HeatMngtFctLim "null";
BA_ "sigSecLevel" SG_ 883 ECC_DrvrAirOutlMod "null";
BA_ "sigExplanation" SG_ 883 ECC_DrvrAirOutlMod "null";
BA_ "sigConfig" SG_ 883 ECC_DrvrAirOutlMod "null";
BA_ "sigSecLevel" SG_ 883 ECC_PassAirOutlMod "null";
BA_ "sigExplanation" SG_ 883 ECC_PassAirOutlMod "null";
BA_ "sigConfig" SG_ 883 ECC_PassAirOutlMod "null";
BA_ "sigSecLevel" SG_ 883 ECC_RemSts "null";
BA_ "sigExplanation" SG_ 883 ECC_RemSts "null";
BA_ "sigConfig" SG_ 883 ECC_RemSts "null";
VAL_ 274 YRS_YawRateSnsrSts 3 "Reserved" 2 "Invalid" 1 "Valid" 0 "Initializing" ;
VAL_ 274 YRS_YawRateCalSts 1 "Sensor_Calibrated" 0 "Sensor_Not_Calibrated" ;
VAL_ 274 YRS_LatSnsrSts 3 "Reserved" 2 "Invalid" 1 "Valid" 0 "Initializing" ;
VAL_ 298 ESP_ExtBrkReqFlg 0 "QTarget_Off" 1 "QTarget_EBR" 2 "QTarget_EBREmergencyBA" 3 "Undefined" ;
VAL_ 298 ESP_FBldgCtrlSts 0 "PFC_Inactive" 1 "PFC_Hold" 2 "PFC_Active" 3 "Reserved" ;
VAL_ 298 ESP_MstCylVirtPTarValVld 0 "Initializing" 1 "Valid" 2 "Invalid" 3 "Reserved" ;
VAL_ 298 ESP_MstCylTarPVld 0 "Initializing" 1 "Valid" 2 "Invalid" 3 "Reserved" ;
VAL_ 298 ESP_StopMain2BackupState 0 "NotAvailable_Temporary" 1 "NotAvailable_NotReleased" 2 "NotAvailable_Permanent" 3 "NotActivated_Fullavailable" 4 "Activation_Preparation" 5 "Activation_Pending" 6 "Activation_PendingRedundancyLost" 7 "Activation_PendingFailOperation" 8 "Acivated_Fullavailable" 9 "Acivated_FailOperation" 10 "Acivated_RedundancyLost" 11 "Deactivation_Pending" 12 "Reserved" 13 "Reserved" 14 "Reserved" 15 "Reserved" ;
VAL_ 89 ACU_FrntCrashOutpSts 0 "no_crash,_level_0" 1 "front_crash_low,_level_1" 2 "front_crash_high,_level_2" 3 "unused" 4 "unused" 5 "unused" 6 "unused" 7 "invalid" ;
VAL_ 89 ACU_RiSideCrashOutpSts 0 "no_crash,_level_0" 1 "right_side_crash_high,_level_2" 2 "unused" 3 "invalid" ;
VAL_ 89 ACU_LeSideCrashOutpSts 0 "no_crash,_level_0" 1 "left_side_crash_high,_level_2" 2 "unused" 3 "invalid" ;
VAL_ 89 ACU_RearCrashOutpSts 0 "no_crash,_level_0" 1 "rear_crash_high,_level_2" 2 "unused" 3 "invalid" ;
VAL_ 89 ACU_RollovrCrashOutpSts 0 "no_crash,_level_0" 1 "rollover_crash,_level_2" 2 "unused" 3 "invalid" ;
VAL_ 89 ACU_Crash_cfm 0 "no_crash" 1 "crash_happened" 2 "not_used" 3 "invalid" ;
VAL_ 275 YRS_LgtSnsrSts 0 "Initializing" 1 "Valid" 2 "Invalid" 3 "Reserved" ;
VAL_ 276 ESP_OTARdy_Fb 0 "Initial" 1 "Ready" 2 "Not_Ready" 3 "Invalid" ;
VAL_ 276 ESP_FltIndcn_DTC 0 "No_Fault" 1 "Fault" ;
VAL_ 276 ESP_ActvSig_VDC 0 "ESP_Standby" 1 "ESP_Actually_Operating" ;
VAL_ 276 ESP_ActvSig_TCS 0 "TCS_Standby" 1 "TCS_Actually_Operating" ;
VAL_ 276 ESP_ActvSig_EBD 0 "EBD_Not_Active" 1 "EBD_Active" ;
VAL_ 276 ESP_ActvSig_DTC 0 "DTC_Not_Active" 1 "DTC_Active" ;
VAL_ 276 ESP_WarningOn 0 "No_Request" 1 "Yellow_Lamp_Request" 2 "Red_Lamp_Request" 3 "Reserved" ;
VAL_ 276 ESP_Actvndcn_CDD 0 "Not_Active" 1 "Active" ;
VAL_ 276 ESP_FltIndcn_CDD 0 "Available" 1 "Not_Available" ;
VAL_ 276 ESP_ActvIndcn_ABA 0 "Not_Active" 1 "Active" ;
VAL_ 276 ESP_FltIndcn_ABA 0 "Available" 1 "Not_Available" ;
VAL_ 276 ESP_ActvIndcn_ABP 0 "Not_Active" 1 "Active" ;
VAL_ 276 ESP_FltIndcn_ABP 0 "Available" 1 "Not_Available" ;
VAL_ 276 ESP_ActvIndcn_AEB 0 "Not_Active" 1 "Active" ;
VAL_ 276 ESP_FltIndcn_AEB 0 "Available" 1 "Not_Available" ;
VAL_ 276 ESP_ActvIndcn_AWB 0 "Not_Active" 1 "Active" ;
VAL_ 276 ESP_FltIndcn_AWB 0 "Available" 1 "Not_Available" ;
VAL_ 276 ESP_VehStandstillIndcn 0 "Not_Standstill" 1 "Standstill" 2 "Invalid" 3 "Reserved" ;
VAL_ 276 ESP_BrkOverTIndcn 0 "Not_High" 1 "Temp_Too_High" ;
VAL_ 276 ESP_FltIndcn_VDC 0 "No_Fault" 1 "Fault" ;
VAL_ 276 ESP_ActvIndcn_CDD_AP 0 "Not_Active" 1 "Active" ;
VAL_ 276 ESP_FltIndcn_CDD_AP 0 "No_Error" 1 "Error" ;
VAL_ 277 ESP_WhlSpdVld_RF 0 "Initializing" 1 "Valid" 2 "Invalid" 3 "Reserved" ;
VAL_ 277 ESP_WhlMovgDir_RF 0 "Init" 1 "Forward" 2 "Backward" 3 "Stop" 4 "Invalid" 5 "Reserved" 6 "Reserved" 7 "Reserved" ;
VAL_ 277 ESP_WhlMovgDir_LF 0 "Init" 1 "Forward" 2 "Backward" 3 "Stop" 4 "Invalid" 5 "Reserved" 6 "Reserved" 7 "Reserved" ;
VAL_ 277 ESP_WhlSpdVld_LF 0 "Initializing" 1 "Valid" 2 "Invalid" 3 "Reserved" ;
VAL_ 278 ESP_WhlSpdVld_RR 0 "Initializing" 1 "Valid" 2 "Invalid" 3 "Reserved" ;
VAL_ 278 ESP_WhlMovgDir_RR 0 "Init" 1 "Forward" 2 "Backward" 3 "Stop" 4 "Invalid" 5 "Reserved" 6 "Reserved" 7 "Reserved" ;
VAL_ 278 ESP_WhlMovgDir_RL 0 "Init" 1 "Forward" 2 "Backward" 3 "Stop" 4 "Invalid" 5 "Reserved" 6 "Reserved" 7 "Reserved" ;
VAL_ 278 ESP_WhlSpdVld_RL 0 "Initializing" 1 "Valid" 2 "Invalid" 3 "Reserved" ;
VAL_ 281 iBooster_OTARdy_Fb 0 "Initial" 1 "Ready" 2 "Not_Ready" 3 "Invalid" ;
VAL_ 281 iBooster_WarnOn 0 "No_Request_To_The_Warning_Lamp" 1 "Warning_Lamp_Requested" ;
VAL_ 281 iBooster_BrkPedlAppldFlg 0 "Brake_Pedal_Not_Applied" 1 "Brake_Pedal_Applied" ;
VAL_ 281 iBooster_BrkPedlAppldVld 0 "Initializing" 1 "Valid" 2 "Invalid" 3 "Reserved" ;
VAL_ 288 ESP_ActvSig_ABS 0 "ABS_Standby" 1 "ABS_Actually_Operating" ;
VAL_ 288 ESP_MstCylPVld 0 "Initializing" 1 "Valid" 2 "Invalid" 3 "Reserved" ;
VAL_ 288 ESP_MstCylPOffsVld 0 "Initializing" 1 "Valid" 2 "Invalid" 3 "Reserved" ;
VAL_ 293 ESP_WhlOdoEdgesVld_FL 0 "Initializing" 1 "Valid" 2 "Invalid" 3 "Reserved" ;
VAL_ 293 ESP_WhlOdoEdgesVld_FR 0 "Initializing" 1 "Valid" 2 "Invalid" 3 "Reserved" ;
VAL_ 293 ESP_WhlOdoEdgesVld_RL 0 "Initializing" 1 "Valid" 2 "Invalid" 3 "Reserved" ;
VAL_ 293 ESP_WhlOdoEdgesVld_RR 0 "Initializing" 1 "Valid" 2 "Invalid" 3 "Reserved" ;
VAL_ 440 ESP_ModFbSig 0 "Init" 1 "Normal" 2 "Sport" 3 "Reserved" 4 "Reserved" 5 "Reserved" 6 "Reserved" 7 "Invalid" ;
VAL_ 440 ESP_ModSwtAllw 0 "Not_Allowed" 1 "Allowed" ;
VAL_ 440 ESP_ActvVehHldFlg 0 "False" 1 "True" ;
VAL_ 440 ESP_VehSecuCdn 0 "ParkSt_Other" 1 "ParkSt_Reld" 2 "ParkSt_Appld" 3 "ParkSt_Reqd" 4 "ParkSt_ReqToutorOvrdn" 5 "Reversed" 6 "Reversed" 7 "Reversed" ;
VAL_ 440 ESP_BrkFStsFlg 0 "False" 1 "True" ;
VAL_ 440 ESP_CddApOpsDirMovmt 0 "False" 1 "True" ;
VAL_ 440 ESP_VehStopSts 0 "Not_Stop" 1 "Stop" ;
VAL_ 440 ESP_VehStandstillSts 0 "Not_Standstill" 1 "Standstill" ;
VAL_ 440 ESP_EPB_BenchMode 0 "Not_Active" 1 "Active" 2 "Reserved" 3 "Invalid" ;
VAL_ 440 ESP_RoadSlopVld 0 "Initializing" 1 "Valid" 2 "Invalid" 3 "Reserved" ;
VAL_ 440 ESP_AEBRdy 0 "Not_ready" 1 "Ready" 2 "Reserved" 3 "Invalid" ;
VAL_ 440 ESPACCRdy 0 "Not_ready" 1 "Ready" 2 "Reserved" 3 "Invalid" ;
VAL_ 440 ESP_ParkRdy 0 "Not_ready" 1 "Ready" 2 "Reserved" 3 "Invalid" ;
VAL_ 440 ESP_ReAEBRdy 0 "Not_ready" 1 "Ready" 2 "Reserved" 3 "Invalid" ;
VAL_ 440 ESP_SpclTerrainModFltIndcn 0 "Not_Available" 1 "Available" ;
VAL_ 440 ESP_DrvOffStRdy 0 "False" 1 "True" ;
VAL_ 440 ESP_TarLSMSts 0 "LSM_Off" 1 "LSM_On" ;
VAL_ 450 EPS_AbortFb 0 "No_Abort" 1 "Driver_Interference_StrWhl" 2 "Reserved" 3 "Reserved" 4 "Reserved" 5 "Reserved" 6 "EPS_Internal_Failure" 7 "Vehilce_Speed_Exceeds_Limits_When_In_Control" 8 "CAN_communication_issue" 9 "Other_Abort_Reasons" 10 "Reserved" 11 "Reserved" 12 "Reserved" 13 "Reserved" 14 "Reserved" 15 "Reserved" ;
VAL_ 450 EPS_SteerWhlAgSig 65535 "Invalid" ;
VAL_ 450 EPS_SteerAgSnsrCalSts 0 "Uncalibrated" 1 "Calibrated" ;
VAL_ 450 EPS_SteerWhlAgSigVld 0 "Initializing" 1 "Valid" 2 "Invalid" 3 "Reserved" ;
VAL_ 450 EPS_SteerWhlRotSpdDir 0 "Forward_rotation" 1 "Negative_rotation" 2 "No_rotation" 3 "Reserved" ;
VAL_ 450 EPS_SteerWhlRotSpdVld 0 "Initializing" 1 "Valid" 2 "Invalid" 3 "Reserved" ;
VAL_ 450 EPS_SteerWhlRotSpd 4095 "Invalid" ;
VAL_ 450 EPS_AdasLatCtrlSts 0 "Off" 1 "Available_For_Control" 2 "Active" 3 "Failure" ;
VAL_ 450 EPS_AdasLatCtrlStsVld 0 "Initializing" 1 "Valid" 2 "Active" 3 "Reserved" ;
VAL_ 450 EPS_AsscMotCrtTq 255 "Invalid" ;
VAL_ 452 EPS_DrvrSteerTqDir 0 "Postive_counterclockwise" 1 "Negative_clockwise" 2 "No_direction" 3 "Invalid" ;
VAL_ 452 EPS_DrvrSteerTqVld 0 "Initializing" 1 "Valid" 2 "Invalid" 3 "Reserved" ;
VAL_ 452 EPS_DrvrSteerTq 4095 "Invalid" ;
VAL_ 452 EPS_OTARdy_Fb 0 "Initial" 1 "Ready" 2 "Not_Ready" 3 "Invalid" ;
VAL_ 452 EPS_DrvrIntvSteerWhlDetd 0 "False_Unintervened" 1 "True_intervention" ;
VAL_ 452 EPS_DrvrIntvSteerWhlVld 0 "Initializing" 1 "Valid" 2 "Invalid" 3 "Reserved" ;
VAL_ 452 EPS_SteerSnsrSts 0 "Not_Failure" 1 "Failure" ;
VAL_ 452 EPS_PinionAg 65534 "Initializing" 65535 "Invalid" ;
VAL_ 532 VCU_RdyLamp 0 "Not_ready" 1 "Ready" ;
VAL_ 532 VCU_BrkLampCtrlSts 0 "No_request" 1 "lighting_request" ;
VAL_ 532 VCU_RemWakeUpEndFlg 0 "remote_control_not_ended" 1 "remote_control_ended" ;
VAL_ 532 VCU_StgyGearSig 0 "Undefined_initial_value" 1 "gear_P" 2 "gear_N" 3 "R_gear" 4 "gear_D" 5 "Reserved" 6 "gear_E" 7 "gear_S" 8 "Reserved" 9 "Reserved" 10 "Reserved" 11 "Reserved" 12 "Reserved" 13 "Reserved" 14 "Reserved" 15 "Reserved" ;
VAL_ 532 VCU_ShiftMisoper 0 "Normal" 1 "Abnormal" ;
VAL_ 532 VCU_GearSigVld 0 "Initializing" 1 "Valid" 2 "Invalid" 3 "Reserved" ;
VAL_ 532 VCU_GearSig 0 "Undefined_initial_value" 1 "gear_P" 2 "gear_N" 3 "R_gear" 4 "D_gear" 5 "Reserved" 6 "gear_E" 7 "gear_S" 8 "Reserved" 9 "Reserved" 10 "Reserved" 11 "Reserved" 12 "Reserved" 13 "Reserved" 14 "Reserved" 15 "Reserved" ;
VAL_ 532 VCU_ACCRdy 0 "Not_ready" 1 "Ready" ;
VAL_ 532 VCU_ParkRdy 0 "Not_ready" 1 "Ready" ;
VAL_ 532 VCU_APSPercVld 0 "Initializing" 1 "Valid" 2 "Invalid" 3 "Reserved" ;
VAL_ 532 VCU_VehSt 0 "VCUSleep" 1 "WakeUp" 2 "Init/StartUp" 3 "Standby" 4 "Driving" 5 "Charging" 6 "PostConditioning" 7 "HV_Active_Discharge" 8 "Afterrun" 9 "EmgcyOff" 10 "EmgcyOff_ADisch" 11 "Safestate" 65535 "Invalid" ;
VAL_ 532 VCU_BrkSig 0 "brake_pedal_not_pressed" 1 "Brake_pedal_depressed" ;
VAL_ 532 VCU_BrkSigVld 0 "Initializing" 1 "Valid" 2 "Invalid" 3 "Reserved" ;
VAL_ 532 VCU_DrvModSigFb 0 "Eco" 1 "Normal" 2 "Sport" 3 "Custom" 4 "Snow" 5 "Offroad" 6 "Valet" 7 "Invalid" ;
VAL_ 532 VCU_DrvModShiftMisoper 0 "Normal" 1 "Abnormal" ;
VAL_ 532 VCU_SpclTerrainModEnaSig 0 "Not_enabled" 1 "Enable" ;
VAL_ 784 CIM_TurnLampSwtSts 0 "Default_state" 1 "Turn_Left_left_steering_state" 2 "Turn_Right_right_steering_state" 3 "Turn_left_highway_flashing" 4 "Turn_right_highway_flashing" 5 "Mechanical_Failure" 6 "Invalid_left" 7 "Invalid_right" ;
VAL_ 784 CIM_HiBeamSwtSts 0 "Neutral_middle_position" 1 "High_beam_pull" 2 "High_beam_push" 3 "Invalid" ;
VAL_ 784 CIM_FrntWshrSwtSts 0 "Washing_OFF" 1 "Front_wash_1st_position_(MIST)" 2 "Front_wash_2nd_position" 3 "Invalid" ;
VAL_ 784 CIM_FrntWiprSwtSts 0 "Off_default" 1 "AutoLow_wiper_automatic_(low_sensitivity)" 2 "AutoHigh_Automatic_Wiper_(high_sensitivity)" 3 "Low_speed_continuous_scraping" 4 "High_continuous_high-speed_scraping" 5 "Reserved" 6 "Reserved" 7 "Invalid" ;
VAL_ 792 ESP_BrkPedlStsVld 0 "Initializing" 1 "Valid" 2 "Invalid" 3 "Reserved" ;
VAL_ 792 ESP_BrkPedlSts 0 "Brake_Pedal_Not_Pressed" 1 "Brake_Pedal_Pressed" ;
VAL_ 792 ESP_VehSpdVld 0 "Initializing" 1 "Valid" 2 "Invalid" 3 "Reserved" ;
VAL_ 792 ESP_SysActv 0 "No_Telltale_Requested" 1 "Telltale_Requested" ;
VAL_ 792 ESP_LampSwtOffIndcn 0 "No_Telltale_Requested" 1 "Telltale_Requested" ;
VAL_ 792 ESP_FltIndcn_EBD 0 "No_Telltale_Requested" 1 "Telltale_Requested" ;
VAL_ 792 ESP_FltIndcn_ABS 0 "No_Telltale_Requested" 1 "Telltale_Requested" ;
VAL_ 792 ESP_IninModSigIndcn 0 "Not_In_Initialization_Mode" 1 "In_Intialization_Mode" ;
VAL_ 792 ESP_FltIndcn_TCS 0 "No_Telltale_Requested" 1 "Telltale_Requested" ;
VAL_ 792 ESP_CtrlSts_HDC 0 "Off" 1 "On_Active_Braking" 2 "On_Not_Active_Braking" 3 "Reserved" ;
VAL_ 792 ESP_AvlIndcn_HDC 0 "Available" 1 "Not_Available" ;
VAL_ 792 ESP_NoBrkP 0 "Exist_Brk_Force" 1 "No_Brk_Force" ;
VAL_ 792 ESP_RDAEnaFlg 0 "Inactive_not_enabled" 1 "Active_enable" ;
VAL_ 819 BCM_KL15_Off_Announcement 0 "NotAvailable" 1 "No_Announcement" 2 "KL15_shutdown_announced" 3 "Reserved" ;
VAL_ 819 BCM_IG1Sts 0 "NotAvailable" 1 "Inactive" 2 "Active" 3 "Reserved" ;
VAL_ 819 BCM_PwrMod 0 "Off" 1 "ACC_(Reserved)" 2 "IGN_On" 3 "Crank_Pending_(Power_Anti-theft_Certification_Process)" 4 "Run" 5 "Crank_Off_(Reserved)" 6 "Reserved" 7 "Reserved" ;
VAL_ 819 BCM_PwrModVld 0 "Initializing" 1 "Valid" 2 "Invalid" 3 "Reserved" ;
VAL_ 819 BCM_BrkSwtSts 0 "No_Pressed" 1 "Pressed" ;
VAL_ 819 BCM_IG1StsVld_CAPE 0 "Initializing" 1 "Valid" 2 "Invalid" 3 "Reserved" ;
VAL_ 819 BCM_IG2StsVld_CAPE 0 "Initializing" 1 "Valid" 2 "Invalid" 3 "Reserved" ;
VAL_ 819 BCM_KL30s_L 0 "Not_Available" 1 "Inactive" 2 "Active" 3 "Reserved" ;
VAL_ 819 BCM_IG2Sts 0 "Not_Available" 1 "Inactive" 2 "Active" 3 "Reserved" ;
VAL_ 819 BCM_InteriorSwtSt 0 "Inactive" 1 "pressed" 2 "reserved" 3 "reserved" ;
VAL_ 821 BCM_WiprInSrvPosn 0 "No" 1 "Yes" ;
VAL_ 821 BCM_IntLampTiSetSts 0 "Not_Use" 1 "0" 2 "15" 3 "30" 4 "45" 5 "60" 6 "Reserved" 7 "Reserved" ;
VAL_ 821 BCM_WaterPosnSnsrSwtSts 0 "Inactive" 1 "Active" ;
VAL_ 821 BCM_FrntFogLampOutpCmd 0 "Off" 1 "On" ;
VAL_ 821 BCM_LicPlateLampOutpCmd 0 "Off" 1 "On" ;
VAL_ 821 BCM_EnaSts_ADB 0 "Inactive" 1 "Active" ;
VAL_ 821 BCM_PwrSaveOutpCmd 0 "Off" 1 "On" ;
VAL_ 821 BCM_ExtLampSwtSts 0 "Off" 1 "Auto" 2 "Position" 3 "Low_Beam" 4 "Reserved" 5 "Reserved" 6 "Reserved" 7 "Reserved" ;
VAL_ 821 BCM_HornOutpCmd 0 "Off" 1 "On" ;
VAL_ 821 BCM_HornSwtSts 0 "Off" 1 "On" ;
VAL_ 821 BCM_WelLampOutpCmd 0 "Off" 1 "On" ;
VAL_ 821 BCM_FolwMeHomeSts 0 "Inactive" 1 "Active" ;
VAL_ 821 BCM_FrntFogLampSwtSts 0 "Inactive" 1 "Active" ;
VAL_ 821 BCM_ReFogLampSwtSts 0 "Inactive" 1 "Active" ;
VAL_ 821 BCM_ReWiprBackSwtSts 0 "Inactive" 1 "Active" ;
VAL_ 821 BCM_RainClsSunroofSetSts 0 "Inactive" 1 "Active" ;
VAL_ 821 BCM_MirrLockAutoSetSts 0 "Off" 1 "On" ;
VAL_ 821 BCM_FrntWshrOutpCmd 0 "Off" 1 "On" ;
VAL_ 821 BCM_DangerAlrmLampSwtSts 0 "Off" 1 "On" ;
VAL_ 821 BCM_ReDefrstHeatgCmd 0 "Off" 1 "On" ;
VAL_ 821 BCM_RvsLampOutpCmd 0 "Off" 1 "On" ;
VAL_ 821 BCM_IntLampOutpCmd 0 "Off" 1 "On" ;
VAL_ 821 BCM_LeTrunLampOutpCmd 0 "Off" 1 "On" ;
VAL_ 821 BCM_RiTrunLampOutpCmd 0 "Off" 1 "On" ;
VAL_ 821 BCM_ReWiprOutpCmd 0 "Off" 1 "On" ;
VAL_ 821 BCM_ReWshrOutpCmd 0 "Off" 1 "On" ;
VAL_ 821 BCM_BrkLampSwtSts 0 "Inactive" 1 "Active" ;
VAL_ 821 BCM_HiBeamOutpCmd 0 "Off" 1 "On" ;
VAL_ 821 BCM_LoBeamOutpCmd 0 "Off" 1 "On" ;
VAL_ 821 BCM_PosnLampOutpCmd 0 "Off" 1 "Left_Park_On" 2 "Right_Park_On" 3 "All_On" ;
VAL_ 821 BCM_BrkLampOutpCmd 0 "Off" 1 "On" ;
VAL_ 821 BCM_ReFogLampOutpCmd 0 "Off" 1 "On" ;
VAL_ 821 BCM_EnaReq_ADB 0 "Inactive" 1 "Active" ;
VAL_ 821 BCM_VehAmbBri 254 "Maximum_value" 255 "Init.value/fault_value" ;
VAL_ 822 ICC_SetAtmLampBri 0 "Level_1" 1 "Level_2" 2 "Level_3" 3 "Level_4" 4 "Level_5" 5 "Level_6" 6 "Level_7" 7 "Level_8" 8 "Level_9" 9 "Level_10" 10 "Reserved" 11 "Reserved" 12 "Reserved" 13 "Reserved" 14 "Reserved" 15 "Reserved" ;
VAL_ 822 ICC_SuspSet 0 "Normal" 1 "Sport" 2 "Off_Road" 3 "Invalid" ;
VAL_ 822 ICC_OTAInhbRdy 0 "Initial" 1 "Inhibit" 2 "Not_Inhibit" 3 "Invalid" ;
VAL_ 822 ICC_AtmLampOpenCmd 0 "turn_off_ambient_light" 1 "turn_on_ambient_light" ;
VAL_ 822 ICC_SteerAssiSet 0 "Initial_value" 1 "Normal" 2 "ECO" 3 "Sport" 4 "Not_used" 5 "Not_used" 6 "Not_used" 7 "Invalid" ;
VAL_ 822 ICC_SetStorageBriLvl 0 "Level_1" 1 "Level_2" 2 "Level_3" 3 "Level_4" 4 "Level_5" 5 "Level_6" 6 "Level_7" 7 "Level_8" 8 "Level_9" 9 "Level_10" 10 "Reserved" 11 "Reserved" 12 "Reserved" 13 "Reserved" 14 "Reserved" 15 "Reserved" ;
VAL_ 822 ICC_HDCSwtSig 0 "No_Pressed" 1 "Pressed" ;
VAL_ 822 ICC_ESPSwtSig 0 "Normal" 1 "Sport" ;
VAL_ 822 ICC_ReqCalifModHMIBtn 0 "Init,_No_request" 1 "Request_California_Mode_OFF" 2 "Request_California_Mode_ON" 3 "Reserved" ;
VAL_ 822 ICC_iTPMSResetSig 0 "no_reset" 1 "reset" 2 "Reserved" 3 "Invalid" ;
VAL_ 822 ICC_WIFIOnOffSig 0 "Invalid" 1 "ON" 2 "OFF" 3 "Reserved" ;
VAL_ 822 ICC_LeMirrAlrmLampFlt 0 "No_Failure" 1 "Failure" 2 "Reserved" 3 "Reserved" ;
VAL_ 822 ICC_RiMirrAlrmLampFlt 0 "No_Failure" 1 "Failure" 2 "Reserved" 3 "Reserved" ;
VAL_ 822 ICC_PhoneSt 0 "Init" 1 "Not_active" 2 "Active" 3 "Error" ;
VAL_ 822 ICC_SpeechSt 0 "Init" 1 "Not_active" 2 "Active" 3 "Error" ;
VAL_ 822 ICC_RemReqFb 0 "Idle" 1 "Successful" 2 "Failed" 3 "Processing" ;
VAL_ 822 ICC_SpdLimFdb 0 "Idle" 1 "Successful" 2 "Failed" 3 "Processing" ;
VAL_ 822 ICC_OTARdy_Fb 0 "Initial" 1 "Ready" 2 "Not_Ready" 3 "Invalid" ;
VAL_ 837 BCM_OutpValResl_HUD 0 "HUD_Measuring_Range_1(4cd/m2)" 1 "HUD_Measuring_Range_1(40cd/m2)" ;
VAL_ 837 BCM_SunshadeRunngSts 0 "Stopped" 1 "Opening_Slide" 2 "Closing_Slide" 3 "Reversing_(AP/Stall)" 4 "Moving_Uninitialized" 5 "Reserved" 6 "Reserved" 7 "Reserved" ;
VAL_ 856 VCU_KickdwnFlg 0 "Inactive" 1 "Active" 3 "Invalid" ;
VAL_ 856 VCU_EPedlEnaSig 0 "Not_enabled" 1 "Enable" ;
VAL_ 856 VCU_ComLostFlt_ESP 0 "Normal" 1 "Abnormal" ;
VAL_ 856 VCU_ComFlt_iBooster 0 "Normal" 1 "Abnormal" ;
VAL_ 856 VCU_RegenLvlFb 0 "Off" 1 "Normal" 2 "High" 3 "Invalid" ;
VAL_ 856 VCU_AccelModFb 0 "Low" 1 "Medium_" 2 "High" 3 "Invalid" ;
VAL_ 856 VCU_EPedlStsFb 0 "OnePedalDrive" 1 "Roll" 2 "Creep" 3 "Invalid" ;
VAL_ 856 VCU_CcTrgSpdDisp 255 "no_display" ;
VAL_ 856 VCU_Sts_CC_ICC 0 "Off" 1 "Initialization" 2 "Standby" 3 "Active" 4 "Override" 5 "Reserved" 6 "Reserved" 7 "Deactivation_brake" 8 "Deactivation_other" 9 "Failure_reversible" 10 "Failure_irreversible" 11 "Reserved" 12 "Reserved" 13 "Reserved" 14 "Reserved" 15 "Reserved" ;
VAL_ 856 VCU_CCIconDisp 0 "No_Display" 1 "White" 2 "Green" 3 "Fault" 4 "Reserved" 5 "Reserved" 6 "Reserved" 7 "Reserved" ;
VAL_ 856 VCU_DispSpdUnit_CC 0 "KMH" 1 "MPH" ;
VAL_ 856 VCU_BoostEnStat 0 "Default" 1 "Boost_unavailable:_Max_activation_number_exceeded" 2 "Boost_unavailable:_Drive_Mode" 3 "Boost_unavailable:_EDU_Coolant_Inlet_Temperature" 4 "Boost_unavailable:_EDU_Coolant_Flow" 5 "Boost_unavailable:_EDU_Stator/_Rotor_Temperature" 6 "Boost_unavailable:_EDU_Decoupling_Unit_open" 7 "Boost_unavailable:_Battery_limitation" 8 "Boost_available" 9 "Boost_active" 10 "Boost_unavailable:_vehicle_not_in_standstil" 11 "Boost_unavailable:_multiple_causes" 15 "invalid" ;
VAL_ 856 VCU_OTARdy_Fb 0 "Initial" 1 "Ready" 2 "Not_Ready" 3 "Invalid" ;
VAL_ 856 VCU_OTA_ECUInhb_Req 0 "Init" 1 "Inhibit_Request" 2 "No_Inhibit_request" 3 "Invalid" ;
VAL_ 856 VCU_OTAVehCdnChk_ASIL 0 "OTA_veh_cond_not_ok" 1 "OTA_veh_cond_ok" 2 "Fault" 3 "Invalid" ;
VAL_ 856 VCU_OTAVehInhb_ASIL_Fb 0 "Inhibition_not_ok" 1 "Inhibition_ok" 2 "Reserved" 3 "Invalid" ;
VAL_ 866 ICC_MetaMapProvider 0 "Unknown" 1 "Nokia_HERE_(NAVTEQ)" 2 "TomTom_(Tele_Atlas)" 3 "Zenrin" 4 "IPC" 5 "NavInfo" 6 "Other" 7 "N/A" ;
VAL_ 866 ICC_MetaMsgType 0 "System_Specific" 1 "Position" 2 "Segment" 3 "Stub" 4 "Profile_Short" 5 "Profile_Long" 6 "Meta-data" 7 "Reserved" ;
VAL_ 866 ICC_MetaHwVer 0 "Unknown" ;
VAL_ 866 ICC_MetaDrvSide 0 "Driving_Side_Left" 1 "Driving_Side_Right_Default_is_0x1" ;
VAL_ 866 ICC_MetaSpdUnits 0 "Kilometers_Per_Hour_(km/h)" 1 "Miles_Per_Hour_(mph)_Default_is_0" ;
VAL_ 883 ECC_CrtSts 0 "Load_initialization" 1 "Low-voltage_state" 2 "Local_high_voltage_state" 3 "Local_charge_state" 4 "Remote_working_state" 5 "High_voltage_discharge_state" 6 "Delay_state" 7 "Reserved" 8 "Reserved" 9 "Reserved" 10 "Reserved" 11 "Reserved" 12 "Reserved" 13 "Reserved" 14 "Reserved" 15 "Reserved" ;
VAL_ 883 ECC_IninSts 0 "Incomplete_initialization" 1 "initialization_completed" ;
VAL_ 883 ECC_PwrSysHeatMngtSts 0 "No_action" 1 "Self_circulation_state" 2 "Forced_cooling" 3 "Reserved" ;
VAL_ 883 ECC_ACSts 0 "Off_state" 1 "ON_state" ;
VAL_ 883 ECC_AirClnSts 0 "Not_ON" 1 "On" ;
VAL_ 883 ECC_WindSpdSts 0 "Windless_gear" 1 "First_gear_of_wind_speed" 2 "Wind_speed_second_gear" 3 "third_gear_of_wind_speed" 4 "wind_speed_fourth_gear" 5 "Wind_speed_fifth_gear" 6 "Wind_speed_six" 7 "Wind_speed_seven_gear" 8 "Reserved" 9 "Reserved" 10 "Reserved" 11 "Reserved" 12 "Reserved" 13 "Reserved" 14 "Reserved" 15 "Reserved" ;
VAL_ 883 ECC_BackRowAirOutlModSts 0 "Rear_face_blowing" 1 "Face_blowing_foot_blowing_of_rear_row" 2 "Foot_blowing_of_rear_row" 3 "Back_row_cutoff" 4 "Reserved" 5 "Reserved" 6 "Reserved" 7 "Reserved" ;
VAL_ 883 ECC_DrvrTSetSts 0 "Inactive" 1 "Low" 2 "Low" 3 "Low" 4 "Low" 5 "Low" 6 "Low" 7 "Low" 8 "Low" 9 "Low" 10 "Low" 11 "Low" 12 "Low" 13 "Low" 14 "Low" 15 "Low" 16 "Low" 17 "Low" 18 "Low" 19 "Low" 20 "Low" 21 "Low" 22 "Low" 23 "Low" 24 "Low" 25 "Low" 26 "Low" 27 "Low" 28 "Low" 29 "Low" 30 "Low" 31 "Low" 32 "Low" 33 "Low" 34 "Low" 35 "Low" 36 "18¡æ" 37 "18.5¡æ" 38 "19¡æ" 39 "19.5¡æ" 40 "20¡æ" 41 "20.5¡æ" 42 "21¡æ" 43 "21.5¡æ" 44 "22¡æ" 45 "22.5¡æ" 46 "23¡æ" 47 "23.5¡æ" 48 "24¡æ" 49 "24.5¡æ" 50 "25¡æ" 51 "25.5¡æ" 52 "26¡æ" 53 "26.5¡æ" 54 "27¡æ" 55 "27.5¡æ" 56 "28¡æ" 57 "28.5¡æ" 58 "29¡æ" 59 "29.5¡æ" 60 "30¡æ" 61 "30.5¡æ" 62 "31¡æ" 63 "31.5¡æ" 64 "32¡æ" 65 "High" 66 "High" 67 "High" 68 "High" 69 "High" 70 "High" 71 "High" 72 "High" 73 "High" 74 "High" 75 "High" 76 "High" 77 "High" 78 "High" 79 "High" 80 "High" 81 "High" 82 "High" 83 "High" 84 "High" 85 "High" 86 "High" 87 "High" 88 "High" 89 "High" 90 "High" 91 "High" 92 "High" 93 "High" 94 "High" 95 "High" 96 "High" 97 "High" 98 "High" 99 "High" 100 "High" 101 "High" 102 "High" 103 "High" 104 "High" 105 "High" 106 "High" 107 "High" 108 "High" 109 "High" 110 "High" 111 "High" 112 "High" 113 "High" 114 "High" 115 "High" 116 "High" 117 "High" 118 "High" 119 "High" 120 "High" 121 "High" 122 "High" 123 "High" 124 "High" 125 "High" 126 "High" 127 "High" 128 "High" 129 "High" 130 "High" 131 "High" 132 "High" 133 "High" 134 "High" 135 "High" 136 "High" 137 "High" 138 "High" 139 "High" 140 "High" 141 "High" 142 "High" 143 "High" 144 "High" 145 "High" 146 "High" 147 "High" 148 "High" 149 "High" 150 "High" 151 "High" 152 "High" 153 "High" 154 "High" 155 "High" 156 "High" 157 "High" 158 "High" 159 "High" 160 "High" 161 "High" 162 "High" 163 "High" 164 "High" 165 "High" 166 "High" 167 "High" 168 "High" 169 "High" 170 "High" 171 "High" 172 "High" 173 "High" 174 "High" 175 "High" 176 "High" 177 "High" 178 "High" 179 "High" 180 "High" 181 "High" 182 "High" 183 "High" 184 "High" 185 "High" 186 "High" 187 "High" 188 "High" 189 "High" 190 "High" 191 "High" 192 "High" 193 "High" 194 "High" 195 "High" 196 "High" 197 "High" 198 "High" 199 "High" 200 "High" 201 "High" 202 "High" 203 "High" 204 "High" 205 "High" 206 "High" 207 "High" 208 "High" 209 "High" 210 "High" 211 "High" 212 "High" 213 "High" 214 "High" 215 "High" 216 "High" 217 "High" 218 "High" 219 "High" 220 "High" 221 "High" 222 "High" 223 "High" 224 "High" 225 "High" 226 "High" 227 "High" 228 "High" 229 "High" 230 "High" 231 "High" 232 "High" 233 "High" 234 "High" 235 "High" 236 "High" 237 "High" 238 "High" 239 "High" 240 "High" 241 "High" 242 "High" 243 "High" 244 "High" 245 "High" 246 "High" 247 "High" 248 "High" 249 "High" 250 "High" 251 "High" 252 "High" 253 "High" 254 "High" 255 "Invalid" ;
VAL_ 883 ECC_PassTSetSts 0 "Inactive" 1 "Low" 2 "Low" 3 "Low" 4 "Low" 5 "Low" 6 "Low" 7 "Low" 8 "Low" 9 "Low" 10 "Low" 11 "Low" 12 "Low" 13 "Low" 14 "Low" 15 "Low" 16 "Low" 17 "Low" 18 "Low" 19 "Low" 20 "Low" 21 "Low" 22 "Low" 23 "Low" 24 "Low" 25 "Low" 26 "Low" 27 "Low" 28 "Low" 29 "Low" 30 "Low" 31 "Low" 32 "Low" 33 "Low" 34 "Low" 35 "Low" 36 "18¡æ" 37 "18.5¡æ" 38 "19¡æ" 39 "19.5¡æ" 40 "20¡æ" 41 "20.5¡æ" 42 "21¡æ" 43 "21.5¡æ" 44 "22¡æ" 45 "22.5¡æ" 46 "23¡æ" 47 "23.5¡æ" 48 "24¡æ" 49 "24.5¡æ" 50 "25¡æ" 51 "25.5¡æ" 52 "26¡æ" 53 "26.5¡æ" 54 "27¡æ" 55 "27.5¡æ" 56 "28¡æ" 57 "28.5¡æ" 58 "29¡æ" 59 "29.5¡æ" 60 "30¡æ" 61 "30.5¡æ" 62 "31¡æ" 63 "31.5¡æ" 64 "32¡æ" 65 "High" 66 "High" 67 "High" 68 "High" 69 "High" 70 "High" 71 "High" 72 "High" 73 "High" 74 "High" 75 "High" 76 "High" 77 "High" 78 "High" 79 "High" 80 "High" 81 "High" 82 "High" 83 "High" 84 "High" 85 "High" 86 "High" 87 "High" 88 "High" 89 "High" 90 "High" 91 "High" 92 "High" 93 "High" 94 "High" 95 "High" 96 "High" 97 "High" 98 "High" 99 "High" 100 "High" 101 "High" 102 "High" 103 "High" 104 "High" 105 "High" 106 "High" 107 "High" 108 "High" 109 "High" 110 "High" 111 "High" 112 "High" 113 "High" 114 "High" 115 "High" 116 "High" 117 "High" 118 "High" 119 "High" 120 "High" 121 "High" 122 "High" 123 "High" 124 "High" 125 "High" 126 "High" 127 "High" 128 "High" 129 "High" 130 "High" 131 "High" 132 "High" 133 "High" 134 "High" 135 "High" 136 "High" 137 "High" 138 "High" 139 "High" 140 "High" 141 "High" 142 "High" 143 "High" 144 "High" 145 "High" 146 "High" 147 "High" 148 "High" 149 "High" 150 "High" 151 "High" 152 "High" 153 "High" 154 "High" 155 "High" 156 "High" 157 "High" 158 "High" 159 "High" 160 "High" 161 "High" 162 "High" 163 "High" 164 "High" 165 "High" 166 "High" 167 "High" 168 "High" 169 "High" 170 "High" 171 "High" 172 "High" 173 "High" 174 "High" 175 "High" 176 "High" 177 "High" 178 "High" 179 "High" 180 "High" 181 "High" 182 "High" 183 "High" 184 "High" 185 "High" 186 "High" 187 "High" 188 "High" 189 "High" 190 "High" 191 "High" 192 "High" 193 "High" 194 "High" 195 "High" 196 "High" 197 "High" 198 "High" 199 "High" 200 "High" 201 "High" 202 "High" 203 "High" 204 "High" 205 "High" 206 "High" 207 "High" 208 "High" 209 "High" 210 "High" 211 "High" 212 "High" 213 "High" 214 "High" 215 "High" 216 "High" 217 "High" 218 "High" 219 "High" 220 "High" 221 "High" 222 "High" 223 "High" 224 "High" 225 "High" 226 "High" 227 "High" 228 "High" 229 "High" 230 "High" 231 "High" 232 "High" 233 "High" 234 "High" 235 "High" 236 "High" 237 "High" 238 "High" 239 "High" 240 "High" 241 "High" 242 "High" 243 "High" 244 "High" 245 "High" 246 "High" 247 "High" 248 "High" 249 "High" 250 "High" 251 "High" 252 "High" 253 "High" 254 "High" 255 "Invalid" ;
VAL_ 883 ECC_HeatSts 0 "Off_state" 1 "ON_state" ;
VAL_ 883 ECC_AUTOSts 0 "Off" 1 "On" ;
VAL_ 883 ECC_SYNCSts 0 "Off" 1 "On" ;
VAL_ 883 ECC_InfoSysWrmColdDisp 0 "No_action" 1 "Natural_wind" 2 "Cold_air" 3 "Hot_air" ;
VAL_ 883 ECC_CircSts 0 "Inner_circulation_state" 1 "outer_circulation_state" ;
VAL_ 883 ECC_ParticleConcVld 0 "Initializing" 1 "Valid" 2 "Invalid" 3 "Reserved" ;
VAL_ 883 ECC_OutdT 255 "Invalid" ;
VAL_ 883 ECC_OutdTVld 0 "Initializing" 1 "Valid" 2 "Invalid" 3 "Reserved" ;
VAL_ 883 ECC_MaxFrntDefrst 0 "Not_opened" 1 "Open" ;
VAL_ 883 ECC_HeatMngtSysFlt 0 "Normal" 1 "Fault" ;
VAL_ 883 ECC_HeatMngtFctLim 0 "Functional" 1 "function_limit" ;
VAL_ 883 ECC_DrvrAirOutlMod 0 "Reserved" 1 "driver_face_blowing_mode" 2 "driver_face_blowing/foot_blowing_mode" 3 "Driver_foot_blowing_mode" 4 "driver_foot/window_mode" 5 "Window_blowing_mode" 6 "Reserved" 7 "Reserved" ;
VAL_ 883 ECC_PassAirOutlMod 0 "Reserved" 1 "front_passenger_face_blowing_mode" 2 "front_passenger_face_blowing/foot_blowing_mode" 3 "Front_passenger_foot_mode" 4 "Front_passenger_foot/window_mode" 5 "Reserved" 6 "Reserved" 7 "Reserved" ;
VAL_ 883 ECC_RemSts 0 "Standby" 1 "Working" 2 "Fault" 3 "Reserved" ;
VAL_ 883 ECC_OTAInhbRdy 0 "Initial" 1 "Inhibit" 2 "Not_Inhibit" 3 "Invalid" ;
SIG_GROUP_ 274 YRS_0x112 1 : YRS_YawRateSnsrSts YRS_YawRate YRS_112_AliveCounter YRS_LatSnsrSts YRS_112_CheckSum YRS_LatAcce YRS_YawRateCalSts;
SIG_GROUP_ 298 ESP_0x12A 1 : ESP_StopMain2BackupState ESP_MstCylTarP ESP_MstCylTarPVld ESP_MstCylVirtPTarValVld ESP_VirtP ESP_ExtBrkReq ESP_FBldgCtrlSts ESP_ExtBrkReqFlg ESP_12A_AliveCounter ESP_12A_CheckSum;
SIG_GROUP_ 32 GW_Syn_All 1 : Syn_TripCntrVal_Byte0_All Syn_MACInfo_Byte2_All Syn_MACInfo_Byte1_All Syn_MACInfo_Byte0_All Syn_RstCntrVal_Byte1_All Syn_RstCntrVal_Byte2_All Syn_RstCntrVal_Byte0_All Syn_TripCntrVal_Byte1_All;
SIG_GROUP_ 89 ACU_0x59 1 : ACU_Crash_cfm ACU_RollovrCrashOutpSts ACU_RearCrashOutpSts ACU_LeSideCrashOutpSts ACU_RiSideCrashOutpSts ACU_FrntCrashOutpSts ACU_59_AliveCounter ACU_59_CheckSum;
SIG_GROUP_ 275 YRS_0x113 1 : YRS_113_AliveCounter YRS_LgtAcce YRS_LgtSnsrSts YRS_113_CheckSum;
SIG_GROUP_ 276 ESP_0x114 1 : ESP_FltIndcn_CDD_AP ESP_FltIndcn_VDC ESP_114_AliveCounter ESP_ActvSig_VDC ESP_OTARdy_Fb ESP_FltIndcn_AWB ESP_ActvIndcn_CDD_AP ESP_BrkOverTIndcn ESP_VehStandstillIndcn ESP_FltIndcn_AEB ESP_ActvSig_TCS ESP_ActvSig_EBD ESP_ActvIndcn_AWB ESP_WarningOn ESP_ActvIndcn_AEB ESP_FltIndcn_ABP ESP_ActvIndcn_ABA ESP_ActvIndcn_ABP ESP_Actvndcn_CDD ESP_FltIndcn_ABA ESP_FltIndcn_CDD ESP_ActvSig_DTC ESP_FltIndcn_DTC ESP_114_CheckSum;
SIG_GROUP_ 277 ESP_0x115 1 : ESP_WhlSpdVld_LF ESP_WhlSpd_LF ESP_WhlMovgDir_LF ESP_WhlMovgDir_RF ESP_WhlSpdVld_RF ESP_WhlSpd_RF ESP_115_AliveCounter ESP_115_CheckSum;
SIG_GROUP_ 278 ESP_0x116 1 : ESP_WhlSpdVld_RL ESP_WhlSpd_RL ESP_WhlMovgDir_RL ESP_WhlMovgDir_RR ESP_WhlSpdVld_RR ESP_WhlSpd_RR ESP_116_AliveCounter ESP_116_CheckSum;
SIG_GROUP_ 281 iBooster_0x119 1 : iBooster_119_CheckSum iBooster_WarnOn iBooster_BrkPedlAppldVld iBooster_BrkPedlAppldFlg iBooster_OTARdy_Fb iBooster_119_AliveCounter;
SIG_GROUP_ 288 ESP_0x120 1 : ESP_TotBrkTqReq ESP_MstCylPOffsVld ESP_MstCylPVld ESP_MstCylPOffs ESP_MstCylP ESP_ActvSig_ABS ESP_120_AliveCounter ESP_120_CheckSum;
SIG_GROUP_ 293 ESP_0x125 1 : ESP_125_CheckSum ESP_125_AliveCounter ESP_WhlOdoEdges_FL ESP_WhlOdoEdges_FR ESP_WhlOdoEdges_RL ESP_WhlOdoEdges_RR ESP_WhlOdoEdgesVld_FL ESP_WhlOdoEdgesVld_FR ESP_WhlOdoEdgesVld_RL ESP_WhlOdoEdgesVld_RR;
SIG_GROUP_ 372 TBOX_0x174 1 : TBOX_XAgrRate TBOX_XVelocity TBOX_174_AliveCounter TBOX_XAcce TBOX_174_CheckSum;
SIG_GROUP_ 373 TBOX_0x175 1 : TBOX_YAgrRate TBOX_YVelocity TBOX_YAcce TBOX_175_CheckSum TBOX_175_AliveCounter;
SIG_GROUP_ 374 TBOX_0x176 1 : TBOX_ZAgrRate TBOX_176_CheckSum TBOX_ZVelocity TBOX_ZAcce TBOX_176_AliveCounter;
SIG_GROUP_ 375 TBOX_0x177 1 : TBOX_PitchStdDev TBOX_Pitch_A TBOX_177_AliveCounter TBOX_DftlAge TBOX_177_CheckSum;
SIG_GROUP_ 376 TBOX_0x178 1 : TBOX_Roll TBOX_RollStdDev TBOX_178_AliveCounter TBOX_178_CheckSum;
SIG_GROUP_ 377 TBOX_0x179 1 : TBOX_HeadingStdDev TBOX_Heading TBOX_179_AliveCounter TBOX_179_CheckSum;
SIG_GROUP_ 440 ESP_0x1B8 1 : ESP_ModFbSig ESP_ActvVehHldFlg ESP_VehSecuCdn ESP_ReAEBRdy ESP_AEBRdy ESP_TarLSMSts ESP_RoadSlop ESPACCRdy ESP_EPB_BenchMode ESP_CddApOpsDirMovmt ESP_VehStopSts ESP_DrvOffStRdy ESP_SpclTerrainModFltIndcn ESP_ParkRdy ESP_RoadSlopVld ESP_VehStandstillSts ESP_BrkFStsFlg ESP_ModSwtAllw ESP_1B8_AliveCounter ESP_1B8_CheckSum;
SIG_GROUP_ 450 EPS_0x1C2 1 : EPS_1C2_AliveCounter EPS_1C2_CheckSum EPS_AbortFb EPS_SteerWhlAgSig EPS_SteerAgSnsrCalSts EPS_SteerWhlAgSigVld EPS_SteerWhlRotSpdDir EPS_SteerWhlRotSpdVld EPS_SteerWhlRotSpd EPS_AdasLatCtrlSts EPS_AdasLatCtrlStsVld EPS_AsscMotCrtTq;
SIG_GROUP_ 452 EPS_0x1C4 1 : EPS_PinionAg EPS_SteerSnsrSts EPS_DrvrIntvSteerWhlVld EPS_DrvrIntvSteerWhlDetd EPS_OTARdy_Fb EPS_DrvrSteerTq EPS_DrvrSteerTqVld EPS_DrvrSteerTqDir EPS_1C4_AliveCounter EPS_1C4_CheckSum;
SIG_GROUP_ 532 VCU_0x214 1 : VCU_SpclTerrainModEnaSig VCU_214_234_CheckSum VCU_214_234_AliveCounter VCU_RdyLamp VCU_StgyGearSig VCU_RemWakeUpEndFlg VCU_BrkLampCtrlSts VCU_ShiftMisoper VCU_DrvModShiftMisoper VCU_DrvModSigFb VCU_GearSigVld VCU_BrkSig VCU_GearSig VCU_VehSt VCU_ACCRdy VCU_ParkRdy VCU_APSPerc VCU_APSPercVld VCU_BrkSigVld;
SIG_GROUP_ 778 ESP_0x30A 1 : ESP_YAWVOffs ESP_LatOffs ESP_LgtOffs ESP_30A_AliveCounter ESP_30A_CheckSum;
SIG_GROUP_ 784 CIM_0x310 1 : CIM_HiBeamSwtSts CIM_FrntWiprSwtSts CIM_FrntWshrSwtSts CIM_310_AliveCounter CIM_TurnLampSwtSts CIM_310_CheckSum;
SIG_GROUP_ 792 ESP_0x318 1 : ESP_318_CheckSum ESP_318_AliveCounter ESP_BrkPedlStsVld ESP_SysActv ESP_FltIndcn_EBD ESP_BrkPedlSts ESP_VehSpdVld ESP_LampSwtOffIndcn ESP_FltIndcn_ABS ESP_MilgRollgCntr_ODO ESP_VehSpd ESP_IninModSigIndcn ESP_RDAEnaFlg ESP_NoBrkP ESP_AvlIndcn_HDC ESP_FltIndcn_TCS ESP_CtrlSts_HDC;
SIG_GROUP_ 819 BCM_0x333 1 : BCM_333_CheckSum BCM_333_AliveCounter BCM_KL15_Off_Announcement BCM_IG1Sts BCM_PwrMod BCM_PwrModVld BCM_BrkSwtSts BCM_IG1StsVld_CAPE BCM_IG2StsVld_CAPE BCM_KL30s_L BCM_IG2Sts BCM_InteriorSwtSt;
SIG_GROUP_ 821 BCM_0x335 1 : BCM_335_AliveCounter BCM_VehAmbBri BCM_IntLampTiSetSts BCM_WaterPosnSnsrSwtSts BCM_FrntFogLampOutpCmd BCM_EnaReq_ADB BCM_ReWiprBackSwtSts BCM_RainClsSunroofSetSts BCM_BrkLampOutpCmd BCM_EnaSts_ADB BCM_PosnLampOutpCmd BCM_LoBeamOutpCmd BCM_FolwMeHomeSts BCM_ReFogLampSwtSts BCM_ReWiprOutpCmd BCM_FrntWshrOutpCmd BCM_HiBeamOutpCmd BCM_FrntWiprSpd BCM_LeTrunLampOutpCmd BCM_RvsLampOutpCmd BCM_DangerAlrmLampSwtSts BCM_IntLampOutpCmd BCM_ReWshrOutpCmd BCM_BrkLampSwtSts BCM_RiTrunLampOutpCmd BCM_ReFogLampOutpCmd BCM_ReDefrstHeatgCmd BCM_MirrLockAutoSetSts BCM_FrntFogLampSwtSts BCM_PwrSaveOutpCmd BCM_WelLampOutpCmd BCM_ExtLampSwtSts BCM_HornSwtSts BCM_HornOutpCmd BCM_LicPlateLampOutpCmd BCM_WiprInSrvPosn BCM_335_CheckSum;
SIG_GROUP_ 822 ICC_0x336 1 : ICC_336_AliveCounter ICC_OTARdy_Fb ICC_RemReqFb ICC_SuspSet ICC_SetAtmLampBri ICC_LeMirrAlrmLampFlt ICC_SpdLimFdb ICC_SpeechSt ICC_OTAInhbRdy ICC_SteerAssiSet ICC_HDCSwtSig ICC_iTPMSResetSig ICC_ESPSwtSig ICC_SpdLimOffs ICC_PhoneSt ICC_RiMirrAlrmLampFlt ICC_WIFIOnOffSig ICC_ReqCalifModHMIBtn ICC_SetStorageBriLvl ICC_AtmLampOpenCmd ICC_336_Checksum;
SIG_GROUP_ 837 BCM_0x345 1 : BCM_SunshadePosnInfo BCM_MeasdVal_HUD BCM_WindshdT_RLS BCM_LeSolaValr_RLS BCM_WindshdHum_RLS BCM_RiSolaValr_RLS BCM_SunshadeRunngSts BCM_OutpValResl_HUD BCM_345_AliveCounter BCM_345_CheckSum;
SIG_GROUP_ 856 VCU_0x358 1 : VCU_358_AliveCounter VCU_KickdwnFlg VCU_OTAVehInhb_ASIL_Fb VCU_OTAVehCdnChk_ASIL VCU_EPedlEnaSig VCU_ComLostFlt_ESP VCU_OTA_ECUInhb_Req VCU_CCIconDisp VCU_OTARdy_Fb VCU_CcTrgSpdDisp VCU_BoostEnStat VCU_DispSpdUnit_CC VCU_Sts_CC_ICC VCU_EPedlStsFb VCU_AccelModFb VCU_RegenLvlFb VCU_ComFlt_iBooster VCU_358_CheckSum;
SIG_GROUP_ 866 ICC_0x362 1 : ICC_Reserved ICC_MetaSpdUnits ICC_MetaCountryCode ICC_MetaMapProvider ICC_MetaMapVerQtr ICC_MetaProtVerMinor ICC_MetaHwVer ICC_MetaMapVerYear ICC_MetaCycCnt ICC_MetaDrvSide ICC_MetaRegionCode ICC_MetaProtVerMajor ICC_MetaProtVerMinorSub ICC_MetaMsgType;
SIG_GROUP_ 883 ECC_0x373 1 : ECC_IninSts ECC_PwrSysHeatMngtSts ECC_ACSts ECC_AirClnSts ECC_DrvrTSetSts ECC_OTAInhbRdy ECC_RemSts ECC_DrvrAirOutlMod ECC_BackRowAirOutlModSts ECC_HeatSts ECC_MaxFrntDefrst ECC_HeatMngtFctLim ECC_PassAirOutlMod ECC_AUTOSts ECC_InfoSysWrmColdDisp ECC_HeatMngtSysFlt ECC_CircSts ECC_OutdT ECC_ParticleConcVld ECC_OutdTVld ECC_SYNCSts ECC_PassTSetSts ECC_WindSpdSts ECC_CrtSts;
